VERSION "10.9.1"

NS_ :

BS_:

BU_: ACM ADAS_Body APM ASU_Gateway BCM BCM_BPM CCU_F CCU_R DUMMY_BCM_BPM DUMMY_ECU ETG LDM_L LDM_R OCS_P PSM_D SHVU_F SHVU_R TRM XGW_Body

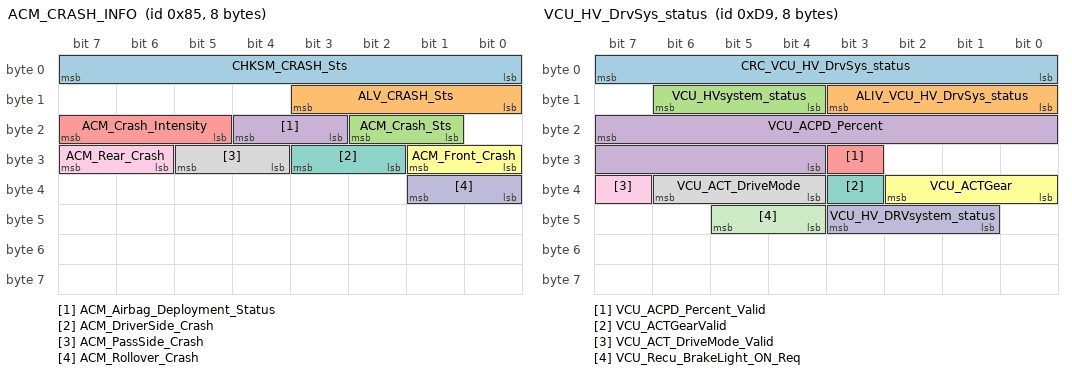
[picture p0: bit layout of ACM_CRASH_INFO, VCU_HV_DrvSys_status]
BO_ 133 ACM_CRASH_INFO: 8 ACM
 SG_ CHKSM_CRASH_Sts : 7|8@0+ (1,0) [0|255] ""  BCM,ETG,XGW_Body
 SG_ ALV_CRASH_Sts : 11|4@0+ (1,0) [0|14] ""  BCM,ETG,XGW_Body
 SG_ ACM_Crash_Sts : 18|2@0+ (1,0) [0|3] ""  BCM,CCU_F,ETG,XGW_Body
 SG_ ACM_Airbag_Deployment_Status : 20|2@0+ (1,0) [0|3] "-"  ETG,XGW_Body
 SG_ ACM_Crash_Intensity : 23|3@0+ (1,0) [0|7] ""  CCU_F,ETG,XGW_Body
 SG_ ACM_Front_Crash : 25|2@0+ (1,0) [0|3] "-"  BCM,ETG,XGW_Body
 SG_ ACM_DriverSide_Crash : 27|2@0+ (1,0) [0|3] ""  BCM,ETG,XGW_Body
 SG_ ACM_PassSide_Crash : 29|2@0+ (1,0) [0|3] "-"  BCM,ETG,XGW_Body
 SG_ ACM_Rear_Crash : 31|2@0+ (1,0) [0|3] "-"  BCM,ETG,XGW_Body
 SG_ ACM_Rollover_Crash : 33|2@0+ (1,0) [0|3] "-"  BCM,ETG,XGW_Body

BO_ 134 ACM_CRASH_DELTA_V_INFO: 8 ACM
 SG_ ACM_CrashDeltaV_PackID : 7|8@0+ (1,0) [1|9] ""  XGW_Body
 SG_ ACM_DeltaVx_01 : 15|9@0+ (1,-250) [-250|250] "Km/h"  XGW_Body
 SG_ ACM_DeltaVx_02 : 22|9@0+ (1,-250) [-250|250] "Km/h"  XGW_Body
 SG_ ACM_DeltaVx_03 : 29|9@0+ (1,-250) [-250|250] "Km/h"  XGW_Body
 SG_ ACM_DeltaVy_01 : 36|9@0+ (1,-250) [-250|250] "Km/h"  XGW_Body
 SG_ ACM_DeltaVy_02 : 43|9@0+ (1,-250) [-250|250] "Km/h"  XGW_Body
 SG_ ACM_DeltaVy_03 : 50|9@0+ (1,-250) [-250|250] "Km/h"  XGW_Body

BO_ 149 IDB_FUNCTION: 8 XGW_Body
 SG_ CHKSM_IDB_FUNCTION : 7|8@0+ (1,0) [0|255] ""  ACM,BCM,DUMMY_ECU
 SG_ ALV_IDB_FUNCTION : 11|4@0+ (1,0) [0|14] ""  ACM,BCM,DUMMY_ECU
 SG_ STAT_ABS : 13|2@0+ (1,0) [0|3] ""  DUMMY_ECU
 SG_ ABS_Active : 15|2@0+ (1,0) [0|3] ""  DUMMY_ECU
 SG_ AYC_Active : 17|2@0+ (1,0) [0|3] "Bit"  DUMMY_ECU
 SG_ ASR_Active : 19|2@0+ (1,0) [0|3] "-"  DUMMY_ECU
 SG_ STAT_DSC : 21|2@0+ (1,0) [0|3] "-"  ACM
 SG_ DSC_Active : 23|2@0+ (1,0) [0|3] ""  DUMMY_ECU
 SG_ HBA_ActiveSignal : 25|2@0+ (1,0) [0|3] ""  DUMMY_ECU
 SG_ ARM_ActiveSignal : 27|2@0+ (1,0) [0|3] "-"  DUMMY_ECU
 SG_ STAT_AutoHazardBlinking : 29|2@0+ (1,0) [0|3] "Bit"  BCM
 SG_ MSR_Active : 31|2@0+ (1,0) [0|3] "-"  DUMMY_ECU
 SG_ HSA_ActiveSignal : 33|2@0+ (1,0) [0|3] ""  DUMMY_ECU
 SG_ EPBi_ECD_ActiveSignal : 35|2@0+ (1,0) [0|3] ""  DUMMY_ECU
 SG_ TSM_Active : 37|2@0+ (1,0) [0|3] "-"  DUMMY_ECU
 SG_ HAS_Available : 41|2@0+ (1,0) [0|3] ""  DUMMY_ECU
 SG_ STAT_EBD : 43|2@0+ (1,0) [0|3] ""  DUMMY_ECU
 SG_ EBD_Active : 45|2@0+ (1,0) [0|3] ""  DUMMY_ECU
 SG_ ST_BRG_MSA : 55|4@0+ (1,0) [0|15] ""  DUMMY_ECU

BO_ 217 VCU_HV_DrvSys_status: 8 XGW_Body
 SG_ CRC_VCU_HV_DrvSys_status : 7|8@0+ (1,0) [0|255] ""  ACM,BCM,LDM_L,LDM_R
 SG_ ALIV_VCU_HV_DrvSys_status : 11|4@0+ (1,0) [0|14] ""  ACM,BCM,LDM_L,LDM_R
 SG_ VCU_HVsystem_status : 14|3@0+ (1,0) [0|7] "-"  ACM,BCM
 SG_ VCU_ACPD_Percent : 23|12@0+ (0.0625,0) [0|100] "%"  ACM
 SG_ VCU_ACPD_Percent_Valid : 27|1@0+ (1,0) [0|1] ""  ACM
 SG_ VCU_ACTGear : 34|3@0+ (1,0) [0|7] ""  BCM,LDM_L,LDM_R
 SG_ VCU_ACTGearValid : 35|1@0+ (1,0) [0|1] ""  BCM,LDM_L,LDM_R
 SG_ VCU_ACT_DriveMode : 38|3@0+ (1,0) [0|7] ""  BCM
 SG_ VCU_ACT_DriveMode_Valid : 39|1@0+ (1,0) [0|1] "-"  BCM
 SG_ VCU_HV_DRVsystem_status : 43|3@0+ (1,0) [0|7] ""  BCM
 SG_ VCU_Recu_BrakeLight_ON_Req : 45|2@0+ (1,0) [0|3] "-"  BCM

BO_ 256 MHU_Vehicle_Info: 8 XGW_Body
 SG_ CHKSM_MHU_VEH_INFO : 7|8@0+ (1,0) [0|255] ""  BCM
 SG_ ALV_MHU_VEH_INFO : 11|4@0+ (1,0) [0|14] ""  BCM
 SG_ MHU_UserProfileId : 23|4@0+ (1,0) [0|15] "-"  BCM
 SG_ MHU_Connectivity_Status : 47|3@0+ (1,0) [0|7] ""  BCM

BO_ 258 BCM_LOGICAL_CLAMP: 3 BCM
 SG_ CHKSM_BCM_LOGICAL_CLAMP : 7|8@0+ (1,0) [0|255] ""  ASU_Gateway,XGW_Body
 SG_ ALIVE_BCM_LOGICAL_CLAMP : 11|4@0+ (1,0) [0|14] ""  ASU_Gateway,XGW_Body
 SG_ STAT_CL30s_Light_L : 13|2@0+ (1,0) [0|3] ""  XGW_Body
 SG_ STAT_CL30s_L : 15|2@0+ (1,0) [0|3] "Bit"  ASU_Gateway,XGW_Body
 SG_ STAT_CL15Wup_L : 17|2@0+ (1,0) [0|3] "Bit"  ASU_Gateway,XGW_Body
 SG_ STAT_CrankRelayHW_BCM : 19|2@0+ (1,0) [0|3] "Bit"  XGW_Body

BO_ 259 BCM_ENERGY_MANAGEMENT: 8 BCM
 SG_ REQ_ConsumerControlSeatMassage : 13|2@0+ (1,0) [0|3] "" XGW_Body
 SG_ REQ_ConsumerControlWirelessCharg : 15|2@0+ (1,0) [0|3] "-"  XGW_Body
 SG_ REQ_ConsumerControlAudioVolumeCo : 18|3@0+ (1,0) [0|7] "-"  XGW_Body
 SG_ REQ_CCU_PTC_Limitation : 21|3@0+ (1,0) [0|7] ""  CCU_F,CCU_R
 SG_ REQ_ConsumerControlRearDefrost : 23|2@0+ (1,0) [0|3] "-"  CCU_F,CCU_R,XGW_Body
 SG_ REQ_ConsumerControlSeatHeatingRe : 31|8@0+ (1,0) [0|100] "%"  SHVU_F,SHVU_R,XGW_Body
 SG_ REQ_ConsumerControlSeatVentilati : 39|8@0+ (1,0) [0|100] "%"  SHVU_F,SHVU_R,XGW_Body
 SG_ REQ_ConsumerControlSeatHeatingFr : 47|8@0+ (1,0) [0|100] "%"  SHVU_F,SHVU_R,XGW_Body
 SG_ DriverIdealTimerCount : 55|8@0+ (5,0) [0|1275] "s"  XGW_Body
 SG_ REQ_ConsumerControlVentilationCl : 63|8@0+ (1,0) [0|100] "%"  CCU_F,CCU_R,SHVU_F,SHVU_R,XGW_Body

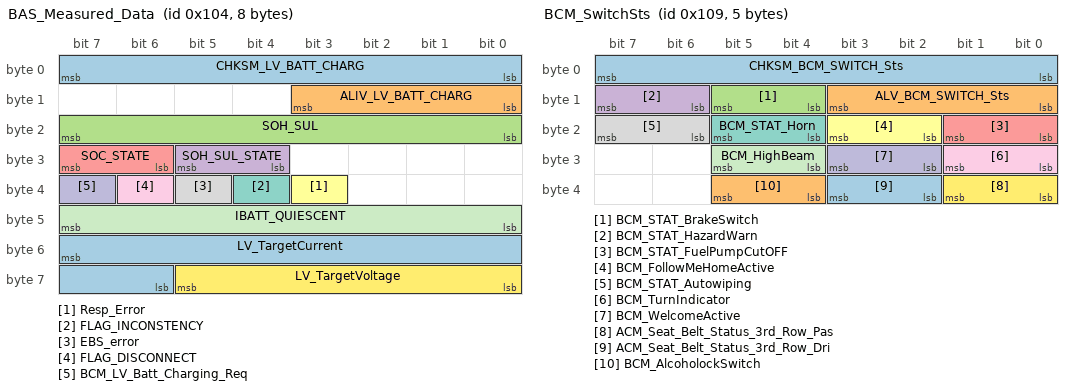
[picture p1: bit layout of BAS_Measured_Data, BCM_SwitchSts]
BO_ 260 BAS_Measured_Data: 8 BCM
 SG_ CHKSM_LV_BATT_CHARG : 7|8@0+ (1,0) [0|255] ""  XGW_Body
 SG_ ALIV_LV_BATT_CHARG : 11|4@0+ (1,0) [0|14] ""  XGW_Body
 SG_ SOH_SUL : 23|8@0+ (1,0) [0|100] "%"  XGW_Body
 SG_ SOH_SUL_STATE : 29|2@0+ (1,0) [0|3] ""  XGW_Body
 SG_ SOC_STATE : 31|2@0+ (1,0) [0|3] "%"  XGW_Body
 SG_ Resp_Error : 35|1@0+ (1,0) [0|1] ""  XGW_Body
 SG_ FLAG_INCONSTENCY : 36|1@0+ (1,0) [0|1] "%"  XGW_Body
 SG_ EBS_error : 37|1@0+ (1,0) [0|1] ""  XGW_Body
 SG_ FLAG_DISCONNECT : 38|1@0+ (1,0) [0|1] ""  XGW_Body
 SG_ BCM_LV_Batt_Charging_Req : 39|1@0+ (1,0) [0|1] ""  XGW_Body
 SG_ IBATT_QUIESCENT : 47|8@0+ (0.00390625,0) [0|0.984375] ""  DUMMY_ECU
 SG_ LV_TargetVoltage : 61|6@0+ (0.112903,9) [9|16] "V" XGW_Body
 SG_ LV_TargetCurrent : 55|10@0+ (0.25,-128) [-128|127] "A" XGW_Body

BO_ 261 BCM_STAT_DOOR_FLAP: 4 BCM
 SG_ CHKSM_BCM_STAT_DOOR_FLAP : 7|8@0+ (1,0) [0|255] ""  ADAS_Body,APM,ASU_Gateway,CCU_F,CCU_R,XGW_Body
 SG_ ALIVE_BCM_STAT_DOOR_FLAP : 11|4@0+ (1,0) [0|14] ""  ADAS_Body,APM,ASU_Gateway,CCU_F,CCU_R,XGW_Body
 SG_ BCM_STAT_TrunkAjar : 17|2@0+ (1,0) [0|3] "Bit"  ADAS_Body,APM,ASU_Gateway,CCU_R,XGW_Body
 SG_ BCM_STAT_DoorAjarFL : 19|2@0+ (1,0) [0|3] "Bit"  ADAS_Body,APM,ASU_Gateway,CCU_F,CCU_R,XGW_Body
 SG_ BCM_STAT_DoorAjarFR : 21|2@0+ (1,0) [0|3] "Bit"  ADAS_Body,APM,ASU_Gateway,CCU_F,CCU_R,XGW_Body
 SG_ BCM_STAT_DoorAjarRL : 23|2@0+ (1,0) [0|3] "Bit"  ADAS_Body,APM,ASU_Gateway,CCU_F,CCU_R,XGW_Body
 SG_ BCM_STAT_DoorAjarRR : 25|2@0+ (1,0) [0|3] "Bit"  ADAS_Body,APM,ASU_Gateway,CCU_F,CCU_R,XGW_Body
 SG_ BCM_STAT_BonnetAjar : 27|2@0+ (1,0) [0|3] "Bit"  ADAS_Body,APM,XGW_Body

BO_ 262 BCM_LIGHT: 8 BCM
 SG_ CHKSM_BCM_LIGHT : 7|8@0+ (1,0) [0|255] ""  ADAS_Body,APM,CCU_F,LDM_L,LDM_R,XGW_Body
 SG_ ALIVE_BCM_LIGHT : 11|4@0+ (1,0) [0|14] ""  ADAS_Body,APM,CCU_F,LDM_L,LDM_R,XGW_Body
 SG_ BCM_DayRunningLampSts : 13|2@0+ (1,0) [0|3] ""  ADAS_Body,LDM_L,LDM_R,XGW_Body
 SG_ BCM_ReverseLightSts : 15|2@0+ (1,0) [0|3] ""  ADAS_Body,TRM,XGW_Body
 SG_ BCM_StopLightSts : 17|2@0+ (1,0) [0|3] ""  ADAS_Body,TRM,XGW_Body
 SG_ BCM_LicensePlateLightSts : 19|2@0+ (1,0) [0|3] ""  ADAS_Body,XGW_Body
 SG_ BCM_Fr_Dimming_dome_lampSts : 21|2@0+ (1,0) [0|3] ""  ADAS_Body,XGW_Body
 SG_ BCM_Rr_Dimming_dome_lampSts : 23|2@0+ (1,0) [0|3] ""  ADAS_Body,XGW_Body
 SG_ BCM_STAT_InteriorLight : 25|2@0+ (1,0) [0|3] "Bit"  ADAS_Body,XGW_Body
 SG_ BCM_STAT_LightActivation : 28|3@0+ (1,0) [0|7] "-"  ADAS_Body,LDM_L,LDM_R,TRM,XGW_Body
 SG_ BCM_HighBeamSts : 31|2@0+ (1,0) [0|3] ""  ADAS_Body,LDM_L,LDM_R,TRM,XGW_Body
 SG_ BCM_STAT_SwitchLightBrightness : 39|7@0+ (1,0) [0|100] "%"  ADAS_Body,XGW_Body
 SG_ BCM_LowBeamSts : 41|2@0+ (1,0) [0|3] "-"  ADAS_Body,LDM_L,LDM_R,TRM,XGW_Body
 SG_ BCM_RearFogLmpSts : 43|2@0+ (1,0) [0|3] "-"  ADAS_Body,TRM,XGW_Body
 SG_ BCM_FrntFogLmpSts : 45|2@0+ (1,0) [0|3] ""  ADAS_Body,XGW_Body
 SG_ BCM_PosLmpSts : 47|2@0+ (1,0) [0|3] "-"  ADAS_Body,LDM_L,LDM_R,TRM,XGW_Body
 SG_ BCM_BackGrdCl58Sts : 51|2@0+ (1,0) [0|3] ""  DUMMY_ECU
 SG_ BCM_HornSts : 53|2@0+ (1,0) [0|3] ""  XGW_Body
 SG_ BCM_TurnIndicatorSts : 55|2@0+ (1,0) [0|3] ""  ADAS_Body,LDM_L,LDM_R,TRM,XGW_Body

BO_ 263 BCM_STAT_CENTRAL_LOCK: 3 BCM
 SG_ CHKSM_BCM_CENTRAL_LOCK : 7|8@0+ (1,0) [0|255] ""  ADAS_Body,ASU_Gateway,XGW_Body
 SG_ ALV_BCM_CENTRAL_LOCK : 11|4@0+ (1,0) [0|14] ""  ADAS_Body,ASU_Gateway,XGW_Body
 SG_ STAT_CDL_LED : 15|2@0+ (1,0) [0|3] "-"  XGW_Body
 SG_ STAT_DoorUnlockFL : 17|2@0+ (1,0) [0|3] "Bit"  XGW_Body
 SG_ STAT_ATWS : 20|3@0+ (1,0) [0|7] "Bit"  ADAS_Body,XGW_Body
 SG_ BCM_CentralLockSwSts : 21|1@0+ (1,0) [0|0] ""  DUMMY_ECU
 SG_ STAT_DoorLockFL : 23|2@0+ (1,0) [0|3] "Bit"  ADAS_Body,ASU_Gateway,XGW_Body

BO_ 265 BCM_SwitchSts: 5 BCM
 SG_ CHKSM_BCM_SWITCH_Sts : 7|8@0+ (1,0) [0|255] ""  ACM,ADAS_Body,LDM_L,LDM_R,TRM,XGW_Body
 SG_ ALV_BCM_SWITCH_Sts : 11|4@0+ (1,0) [0|14] ""  ACM,ADAS_Body,LDM_L,LDM_R,TRM,XGW_Body
 SG_ BCM_STAT_BrakeSwitch : 13|2@0+ (1,0) [0|3] ""  ACM,ADAS_Body,TRM,XGW_Body
 SG_ BCM_STAT_HazardWarn : 15|2@0+ (1,0) [0|3] "-"  ADAS_Body,LDM_L,LDM_R,TRM,XGW_Body
 SG_ BCM_STAT_FuelPumpCutOFF : 17|2@0+ (1,0) [0|3] ""  XGW_Body
 SG_ BCM_FollowMeHomeActive : 19|2@0+ (1,0) [0|3] ""  TRM,XGW_Body
 SG_ BCM_STAT_Horn : 21|2@0+ (1,0) [0|3] "-"  XGW_Body
 SG_ BCM_STAT_Autowiping : 23|2@0+ (1,0) [0|3] ""  XGW_Body
 SG_ BCM_TurnIndicator : 25|2@0+ (1,0) [0|3] ""  ADAS_Body,LDM_L,LDM_R,TRM,XGW_Body
 SG_ BCM_WelcomeActive : 27|2@0+ (1,0) [0|3] "-"  TRM,XGW_Body
 SG_ BCM_HighBeam : 29|2@0+ (1,0) [0|3] ""  LDM_L,LDM_R,TRM,XGW_Body
 SG_ ACM_Seat_Belt_Status_3rd_Row_Pas : 33|2@0+ (1,0) [0|3] ""  XGW_Body
 SG_ ACM_Seat_Belt_Status_3rd_Row_Dri : 35|2@0+ (1,0) [0|3] "-"  XGW_Body
 SG_ BCM_AlcoholockSwitch : 37|2@0+ (1,0) [0|3] ""  DUMMY_ECU

BO_ 266 BCM_VOLTAGE: 8 BCM
 SG_ CHKSM_BCM_VOLTAGE : 7|8@0+ (1,0) [0|255] ""  ACM,ADAS_Body,APM,ASU_Gateway,BCM_BPM,CCU_F,CCU_R,ETG,LDM_L,LDM_R,OCS_P,PSM_D,SHVU_F,SHVU_R,TRM,XGW_Body
 SG_ ALIVE_BCM_VOLTAGE : 11|4@0+ (1,0) [0|14] ""  ACM,ADAS_Body,APM,ASU_Gateway,BCM_BPM,CCU_F,CCU_R,ETG,LDM_L,LDM_R,OCS_P,PSM_D,SHVU_F,SHVU_R,TRM,XGW_Body
 SG_ LV_BatteryType : 13|2@0+ (1,0) [0|3] "Number" XGW_Body
 SG_ UBatt : 23|14@0+ (0.0009777,3) [3|18] "V"  ACM,ADAS_Body,APM,ASU_Gateway,BCM_BPM,CCU_F,CCU_R,ETG,LDM_L,LDM_R,OCS_P,PSM_D,SHVU_F,SHVU_R,TRM,XGW_Body
 SG_ LV_Batt_Temp : 39|8@0+ (1,-40) [-40|105] "Degree C"  ACM,ADAS_Body,APM,ASU_Gateway,BCM_BPM,CCU_F,CCU_R,ETG,LDM_L,LDM_R,OCS_P,PSM_D,SHVU_F,SHVU_R,TRM,XGW_Body
 SG_ LV_SOC : 47|8@0+ (1,0) [0|100] "%"  ACM,ADAS_Body,APM,ASU_Gateway,BCM_BPM,CCU_F,CCU_R,ETG,LDM_L,LDM_R,OCS_P,PSM_D,SHVU_F,SHVU_R,TRM,XGW_Body
 SG_ LV_Batt_Current : 55|16@0+ (0.03125,-1536) [-1536|511.90625] "A"  ACM,ADAS_Body,APM,ASU_Gateway,BCM_BPM,CCU_F,CCU_R,ETG,LDM_L,LDM_R,OCS_P,PSM_D,SHVU_F,SHVU_R,TRM,XGW_Body

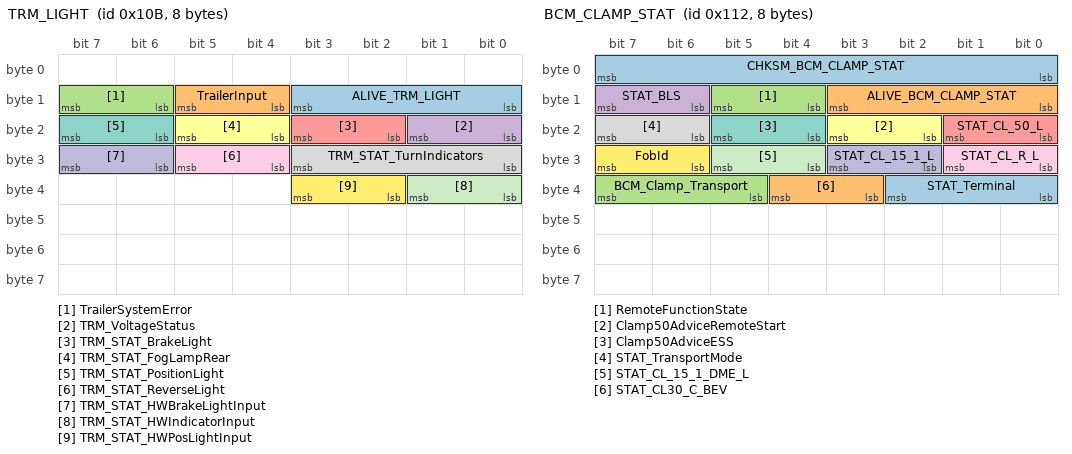
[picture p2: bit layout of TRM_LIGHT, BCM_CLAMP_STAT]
BO_ 267 TRM_LIGHT: 8 TRM
 SG_ ALIVE_TRM_LIGHT : 11|4@0+ (1,0) [0|14] ""  BCM,XGW_Body
 SG_ TrailerInput : 13|2@0+ (1,0) [0|3] ""  BCM,XGW_Body
 SG_ TrailerSystemError : 15|2@0+ (1,0) [0|3] ""  BCM,XGW_Body
 SG_ TRM_VoltageStatus : 17|2@0+ (1,0) [0|3] ""  BCM,XGW_Body
 SG_ TRM_STAT_BrakeLight : 19|2@0+ (1,0) [0|3] ""  BCM,XGW_Body
 SG_ TRM_STAT_FogLampRear : 21|2@0+ (1,0) [0|3] ""  BCM,XGW_Body
 SG_ TRM_STAT_PositionLight : 23|2@0+ (1,0) [0|3] ""  BCM,XGW_Body
 SG_ TRM_STAT_TurnIndicators : 27|4@0+ (1,0) [0|15] ""  BCM,XGW_Body
 SG_ TRM_STAT_ReverseLight : 29|2@0+ (1,0) [0|3] ""  BCM,XGW_Body
 SG_ TRM_STAT_HWBrakeLightInput : 31|2@0+ (1,0) [0|3] ""  BCM,XGW_Body
 SG_ TRM_STAT_HWIndicatorInput : 33|2@0+ (1,0) [0|3] ""  BCM,XGW_Body
 SG_ TRM_STAT_HWPosLightInput : 35|2@0+ (1,0) [0|3] ""  BCM,XGW_Body

BO_ 268 BCM_RemoteCtrlSts: 8 BCM
 SG_ Checksum_0x10C : 7|8@0+ (1,0) [0|255] ""  XGW_Body
 SG_ Rolling_Counter_0x10C : 11|4@0+ (1,0) [0|14] ""  XGW_Body
 SG_ BCM_TboxAuthStatus : 23|2@0+ (1,0) [0|3] "-"  XGW_Body
 SG_ BCM_RandomNum32bit : 31|32@0+ (1,0) [0|4294967295] "-"  XGW_Body

BO_ 269 MHU_BCM_DoorsCtrl: 8 XGW_Body
 SG_ MHU_APM_ReqWindow : 3|2@0+ (1,0) [0|3] "-"  BCM
 SG_ MHU_BCM_RemoteDoorCtrl : 5|2@0+ (1,0) [0|3] "-"  BCM
 SG_ MHU_BCM_reqTrunk : 7|2@0+ (1,0) [0|3] "-"  BCM
 SG_ MHU_BCM_reqFrunk : 9|2@0+ (1,0) [0|3] "-"  BCM
 SG_ MHU_BCM_ReqSunroof : 23|8@0+ (1,0) [0|255] "%"  BCM
 SG_ TBOX_AuthCode_0x10D : 55|16@0+ (1,0) [0|65535] "-"  BCM

BO_ 270 BCM_ENTRY_CONTROL: 3 BCM
 SG_ GlobalWindowReq : 3|3@0+ (1,0) [0|7] ""  APM
 SG_ RemoteAccessKey : 7|4@0+ (1,0) [0|15] "-"  APM,ETG,XGW_Body
 SG_ PassiveAccessTrunk : 9|2@0+ (1,0) [0|3] "-"  ETG,XGW_Body
 SG_ ComfortOpen : 11|2@0+ (1,0) [0|3] "-"  ETG,XGW_Body
 SG_ PassiveAccessDoor : 13|2@0+ (1,0) [0|3] "-"  APM,ETG,XGW_Body
 SG_ FksOpen : 15|2@0+ (1,0) [0|3] ""  ETG,XGW_Body

BO_ 271 MHU_BCM_HornLightControl: 8 XGW_Body
 SG_ MHU_SetHornOnOff : 3|2@0+ (1,0) [0|3] "-"  BCM
 SG_ MHU_SetLowBeam : 5|2@0+ (1,0) [0|3] ""  BCM
 SG_ MHU_SetHighBeam : 7|2@0+ (1,0) [0|3] ""  BCM
 SG_ TBOX_AuthCode_0x10F : 55|16@0+ (1,0) [0|65535] "-"  BCM

BO_ 273 BCM_Stat_SwitchLightBrightness: 8 BCM
 SG_ BCM_Stat_SwitchLightBrightness : 7|8@0+ (0.4,0) [0|102] ""  XGW_Body
 SG_ BCM_Rear_Wiper_Park_Pos_Status : 32|1@0+ (1,0) [0|1] ""  DUMMY_ECU
 SG_ BCM_Front_Wiper_Park_Pos_Status : 33|1@0+ (1,0) [0|1] ""  DUMMY_ECU
 SG_ BCM_Rear_Wash_Status : 34|1@0+ (1,0) [0|1] ""  DUMMY_ECU
 SG_ BCM_Front_Wash_Status : 35|1@0+ (1,0) [0|1] ""  DUMMY_ECU

BO_ 274 BCM_CLAMP_STAT: 8 BCM
 SG_ CHKSM_BCM_CLAMP_STAT : 7|8@0+ (1,0) [0|255] ""  ACM,ADAS_Body,APM,ASU_Gateway,BCM_BPM,CCU_F,CCU_R,ETG,LDM_L,LDM_R,OCS_P,PSM_D,SHVU_F,SHVU_R,TRM,XGW_Body
 SG_ ALIVE_BCM_CLAMP_STAT : 11|4@0+ (1,0) [0|14] ""  ACM,ADAS_Body,APM,ASU_Gateway,BCM_BPM,CCU_F,CCU_R,ETG,LDM_L,LDM_R,OCS_P,PSM_D,SHVU_F,SHVU_R,TRM,XGW_Body
 SG_ RemoteFunctionState : 13|2@0+ (1,0) [0|3] ""  ACM,ADAS_Body,APM,ASU_Gateway,BCM_BPM,CCU_F,CCU_R,ETG,LDM_L,LDM_R,OCS_P,PSM_D,SHVU_F,SHVU_R,TRM,XGW_Body
 SG_ STAT_BLS : 15|2@0+ (1,0) [0|3] "-"  ACM,ADAS_Body,APM,ASU_Gateway,BCM_BPM,CCU_F,CCU_R,ETG,LDM_L,LDM_R,OCS_P,PSM_D,SHVU_F,SHVU_R,TRM,XGW_Body
 SG_ STAT_CL_50_L : 17|2@0+ (1,0) [0|3] ""  ACM,ADAS_Body,APM,ASU_Gateway,BCM_BPM,CCU_F,CCU_R,ETG,LDM_L,LDM_R,OCS_P,PSM_D,SHVU_F,SHVU_R,TRM,XGW_Body
 SG_ Clamp50AdviceRemoteStart : 19|2@0+ (1,0) [0|3] "-"  ACM,ADAS_Body,APM,ASU_Gateway,BCM_BPM,CCU_F,CCU_R,ETG,LDM_L,LDM_R,OCS_P,PSM_D,SHVU_F,SHVU_R,TRM,XGW_Body
 SG_ Clamp50AdviceESS : 21|2@0+ (1,0) [0|3] "-"  ACM,ADAS_Body,APM,ASU_Gateway,BCM_BPM,CCU_F,CCU_R,ETG,LDM_L,LDM_R,OCS_P,PSM_D,SHVU_F,SHVU_R,TRM,XGW_Body
 SG_ STAT_TransportMode : 23|2@0+ (1,0) [0|3] "" XGW_Body
 SG_ STAT_CL_R_L : 25|2@0+ (1,0) [0|3] ""  ACM,ADAS_Body,APM,ASU_Gateway,BCM_BPM,CCU_F,CCU_R,ETG,LDM_L,LDM_R,OCS_P,PSM_D,SHVU_F,SHVU_R,TRM,XGW_Body
 SG_ STAT_CL_15_1_L : 27|2@0+ (1,0) [0|3] "-"  ACM,ADAS_Body,APM,ASU_Gateway,BCM_BPM,CCU_F,CCU_R,ETG,LDM_L,LDM_R,OCS_P,PSM_D,SHVU_F,SHVU_R,TRM,XGW_Body
 SG_ STAT_CL_15_1_DME_L : 29|2@0+ (1,0) [0|3] ""  ACM,ADAS_Body,APM,ASU_Gateway,BCM_BPM,CCU_F,CCU_R,ETG,LDM_L,LDM_R,OCS_P,PSM_D,SHVU_F,SHVU_R,TRM,XGW_Body
 SG_ FobId : 31|2@0+ (1,0) [0|3] "Bit"  ACM,ADAS_Body,APM,ASU_Gateway,BCM_BPM,CCU_F,CCU_R,ETG,LDM_L,LDM_R,OCS_P,PSM_D,SHVU_F,SHVU_R,TRM,XGW_Body
 SG_ STAT_Terminal : 34|3@0+ (1,0) [0|7] "Bit"  ACM,ADAS_Body,APM,ASU_Gateway,BCM_BPM,CCU_F,CCU_R,ETG,LDM_L,LDM_R,OCS_P,PSM_D,SHVU_F,SHVU_R,TRM,XGW_Body
 SG_ STAT_CL30_C_BEV : 36|2@0+ (1,0) [0|3] "Bit"  ACM,ADAS_Body,APM,ASU_Gateway,BCM_BPM,CCU_F,CCU_R,ETG,LDM_L,LDM_R,OCS_P,PSM_D,SHVU_F,SHVU_R,TRM,XGW_Body
 SG_ BCM_Clamp_Transport : 39|3@0+ (1,0) [0|7] ""  ACM,ADAS_Body,APM,ASU_Gateway,BCM_BPM,CCU_F,CCU_R,ETG,LDM_L,LDM_R,OCS_P,PSM_D,SHVU_F,SHVU_R,TRM,XGW_Body

BO_ 276 BCM_LVBAT_Data: 8 BCM
 SG_ CHKSM_LVBAT_DATA : 7|8@0+ (1,0) [0|255] "" XGW_Body
 SG_ ALIV_LVBAT_DATA : 11|4@0+ (1,0) [0|14] "" XGW_Body
 SG_ LV_ErrorSts : 14|3@0+ (1,0) [0|7] "" XGW_Body
 SG_ LV_MinCellVolt : 23|8@0+ (0.015625,1) [1|5] "V" XGW_Body
 SG_ LV_MaxCellVolt : 31|8@0+ (0.015625,1) [1|5] "V" XGW_Body
 SG_ LV_MinCellTemp : 39|8@0+ (1,-40) [-40|215] "Degree C" XGW_Body
 SG_ LV_MaxCellTemp : 47|8@0+ (1,-40) [-40|215] "Degree C" XGW_Body
 SG_ LV_Discharger_Err : 48|1@0+ (1,0) [0|1] "" XGW_Body
 SG_ LV_Discharger_Sts : 49|1@0+ (1,0) [0|1] "" XGW_Body
 SG_ LV_Charger_Err : 50|1@0+ (1,0) [0|1] "" XGW_Body
 SG_ LV_Charger_Sts : 51|1@0+ (1,0) [0|1] "" XGW_Body
 SG_ LV_OverVoltage : 52|1@0+ (1,0) [0|1] "" XGW_Body
 SG_ LV_UnderVoltage : 53|1@0+ (1,0) [0|1] "" XGW_Body
 SG_ LV_OverCurrent : 54|1@0+ (1,0) [0|1] "" XGW_Body
 SG_ LV_UnderTemp : 55|1@0+ (1,0) [0|1] "" XGW_Body
 SG_ LV_OverTemp : 56|1@0+ (1,0) [0|1] "" XGW_Body
 SG_ LV_OverCharge : 57|1@0+ (1,0) [0|1] "" XGW_Body
 SG_ LV_OverDischarge : 58|1@0+ (1,0) [0|1] "" XGW_Body
 SG_ LV_CellBalance_Sts : 59|1@0+ (1,0) [0|1] "" XGW_Body
 SG_ LV_CellBalance_Error : 60|1@0+ (1,0) [0|1] "" XGW_Body
 SG_ LV_ThermalRunaway : 61|1@0+ (1,0) [0|1] "" XGW_Body
 SG_ LV_WarmupRequest : 63|2@0+ (1,0) [0|3] "" XGW_Body

BO_ 277 BCM_Childlock: 8 BCM
 SG_ BCM_ChildLock_Feedback : 7|2@0+ (1,0) [0|3] ""  XGW_Body

BO_ 278 BCM_LVBAT_COM_INFO2: 8 BCM
 SG_ CHKSM_LVBAT_INFO2 : 7|8@0+ (1,0) [0|255] "" XGW_Body
 SG_ ALIV_LVBAT_INFO2 : 11|4@0+ (1,0) [0|14] "" XGW_Body
 SG_ LV_MaxAllowDischargeCurrent : 16|8@0+ (1,0) [0|253] "A" XGW_Body
 SG_ LV_WakeupReason : 19|3@0+ (1,0) [0|7] "" XGW_Body
 SG_ LV_MaxAllowChargeCurrent : 24|8@0+ (1,0) [0|253] "A" XGW_Body
 SG_ LV_SOE : 32|7@0+ (1,0) [0|100] "%" XGW_Body

BO_ 280 BCM_MHU_Ctrl_Fbk: 8 BCM
 SG_ CHKSM_BCM_MHU_Ctrl_Fbk : 7|8@0+ (1,0) [0|255] "" XGW_Body
 SG_ ALV_BCM_MHU_Ctrl_Fbk : 11|4@0+ (1,0) [0|14] "" XGW_Body
 SG_ BCM_DrvInhibitStsFbk : 13|2@0+ (1,0) [0|3] "" XGW_Body

BO_ 282 MHU_ServiceMode_Setting: 8 XGW_Body
 SG_ MHU_SET_WiperServicePositionMod : 5|2@0+ (1,0) [0|3] ""  BCM
 SG_ MHU_Read_KeyFobOnCenterConsole : 7|2@0+ (1,0) [0|3] ""  BCM

BO_ 283 MHU_BCM_RemoteClampCtrl: 8 XGW_Body
 SG_ TBOX_STAT_TerminalReq : 7|3@0+ (1,0) [0|7] "-"  BCM
 SG_ TBOX_AuthCode_0x11B : 55|16@0+ (1,0) [0|65535] ""  BCM

BO_ 284 MHU_BCM_FOTAClampCtrl: 8 XGW_Body
 SG_ TBOX_FOTA_STAT_TerminalReq : 7|3@0+ (1,0) [0|7] "-"  BCM

BO_ 285 CCU_RearHVACControl: 8 CCU_F
 SG_ CCU_ERL_Rear : 7|8@0+ (1,0) [0|255] ""  CCU_R
 SG_ CCU_EvapTempSet_Rear : 15|8@0+ (0.1,-5) [-5|20.5] "Degree C"  CCU_R
 SG_ CCU_AirDistribFlapPos_Rear : 23|8@0+ (0.5,0) [0|100] "%"  CCU_R
 SG_ CCU_BlowerFltPwm_Rear : 31|8@0+ (0.5,0) [0|100] "%"  CCU_R
 SG_ CCU_DuctTargetTemp_Rear : 39|8@0+ (0.5,-40) [-40|85] "Degree C"  CCU_R
 SG_ CCU_TempFlapPos_Rear : 47|8@0+ (0.5,0) [0|100] "%"  CCU_R
 SG_ CCU_FanSpeed_Rear : 51|4@0+ (1,0) [0|15] "%"  CCU_R
 SG_ CCUF_InteriorTemp_Rear : 63|8@0+ (0.5,-40) [-40|85] "Degree C"  DUMMY_ECU

BO_ 286 CCUR_SensorInfo: 8 CCU_R
 SG_ CCUR_DuctActRearFace : 7|8@0+ (0.5,-40) [-40|85] "Degree C"  CCU_F
 SG_ CCUR_DuctActRearFoot : 15|8@0+ (0.5,-40) [-40|85] "Degree C"  CCU_F
 SG_ CCUR_EvaporatorTemp : 23|8@0+ (0.5,-40) [-40|85] "Degree C"  CCU_F
 SG_ CCUR_InteriorTemp : 31|8@0+ (0.5,-40) [-40|85] "Degree C"  CCU_F
 SG_ CCUR_AirDistribFeedback_Rear : 39|8@0+ (0.5,0) [0|5] "V"  CCU_F
 SG_ CCUR_TempFeedback_Rear : 47|8@0+ (0.5,0) [0|5] "V"  CCU_F
 SG_ CCUR_BlowerFeedback_Rear : 55|8@0+ (0.5,0) [0|5] "V"  CCU_F

BO_ 287 MHU_BCM_Ctrl: 8 XGW_Body
 SG_ MHU_DrvInhibitSts : 13|2@0+ (1,0) [0|3] "" BCM
 SG_ TBOX_AuthCode_0x11F : 55|16@0+ (1,0) [0|65535] "" BCM

BO_ 290 CCU_MaxReq: 4 CCU_F
 SG_ CHKSM_CCU_REQUEST : 7|8@0+ (1,0) [0|255] ""  XGW_Body
 SG_ ALV_CCU_REQUEST : 11|4@0+ (1,0) [0|14] ""  XGW_Body
 SG_ CCU_REQ_MaxCool : 13|2@0+ (1,0) [0|3] ""  XGW_Body
 SG_ CCU_REQ_MaxHeat : 15|2@0+ (1,0) [0|3] ""  XGW_Body
 SG_ CCU_REQ_ESSMotorControl : 18|3@0+ (1,0) [0|7] "Bit"  XGW_Body
 SG_ CCU_AC_PWM : 31|7@0+ (1,0) [0|100] "%"  XGW_Body

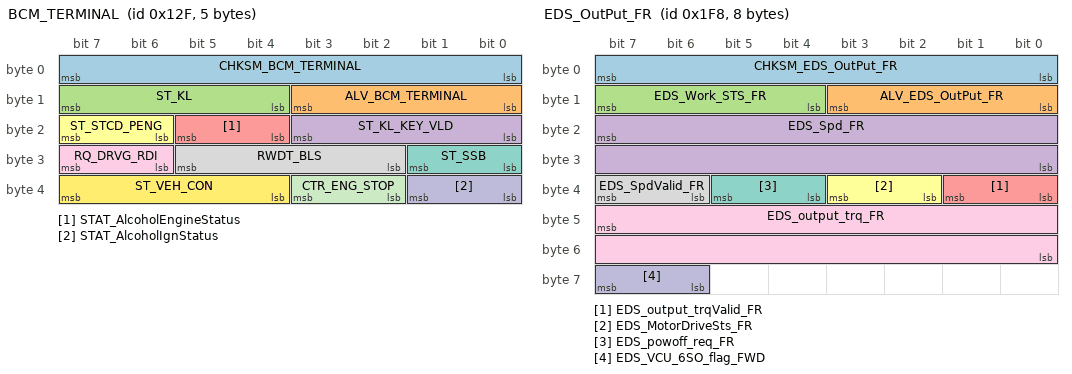
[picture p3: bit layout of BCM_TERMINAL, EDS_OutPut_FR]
BO_ 303 BCM_TERMINAL: 5 BCM
 SG_ CHKSM_BCM_TERMINAL : 7|8@0+ (1,0) [0|255] ""  XGW_Body
 SG_ ALV_BCM_TERMINAL : 11|4@0+ (1,0) [0|14] ""  XGW_Body
 SG_ ST_KL : 15|4@0+ (1,0) [0|15] "-"  XGW_Body
 SG_ ST_KL_KEY_VLD : 19|4@0+ (1,0) [0|15] ""  XGW_Body
 SG_ STAT_AlcoholEngineStatus : 21|2@0+ (1,0) [0|3] ""  XGW_Body
 SG_ ST_STCD_PENG : 23|2@0+ (1,0) [0|3] ""  XGW_Body
 SG_ ST_SSB : 25|2@0+ (1,0) [0|3] "-"  XGW_Body
 SG_ RWDT_BLS : 29|4@0+ (1,0) [0|15] "-"  XGW_Body
 SG_ RQ_DRVG_RDI : 31|2@0+ (1,0) [0|3] ""  XGW_Body
 SG_ STAT_AlcoholIgnStatus : 33|2@0+ (1,0) [0|3] ""  XGW_Body
 SG_ CTR_ENG_STOP : 35|2@0+ (1,0) [0|3] "Bit"  XGW_Body
 SG_ ST_VEH_CON : 39|4@0+ (1,0) [0|15] "-"  XGW_Body

BO_ 359 VCU_TWV1_Frm: 8 XGW_Body
 SG_ TWV1_N_Position : 7|16@0+ (0.1,0) [0|100] "%"  CCU_F
 SG_ TWV1_St_Feedback : 23|16@0+ (1,0) [0|15] ""  CCU_F
 SG_ TWV1_Frm_Error : 39|1@0+ (1,0) [0|1] ""  CCU_F

BO_ 376 YSS_LongAcc: 8 XGW_Body
 SG_ CHKSM_YSS_LongAcc : 7|8@0+ (1,0) [0|255] ""  ASU_Gateway
 SG_ ALV_YSS_LongAcc : 11|4@0+ (1,0) [0|14] ""  ASU_Gateway
 SG_ YSS_LONG_ACCUNFILTERED_QUAL : 15|4@0+ (1,0) [0|15] ""  ASU_Gateway
 SG_ YSS_LONG_ACC_UNFILTERED : 23|16@0+ (0.002,-65.532) [-65.532|65.532] "m/s2"  ASU_Gateway
 SG_ YSS_LONG_ACC_QUAL : 35|4@0+ (1,0) [0|15] ""  ASU_Gateway
 SG_ YSS_LONG_ACC : 47|16@0+ (0.002,-65.532) [-65.532|65.532] "m/s2"  ASU_Gateway

BO_ 381 YSS_YawRate: 8 XGW_Body
 SG_ CHKSM_YSS_YawRate : 7|8@0+ (1,0) [0|255] ""  ASU_Gateway
 SG_ ALV_YSS_YawRate : 11|4@0+ (1,0) [0|14] ""  ASU_Gateway
 SG_ YSS_YAW_RATEUNFILTERED_QUAL : 15|4@0+ (1,0) [0|15] ""  ASU_Gateway
 SG_ YSS_YAW_RATE_UNFILTERED : 23|16@0+ (0.005,-163.83) [-163.83|163.83] "°/s"  ASU_Gateway
 SG_ YSS_YAW_RATE_QUAL : 35|4@0+ (1,0) [0|15] ""  ASU_Gateway
 SG_ YSS_SC_STATUS : 39|4@0+ (1,0) [0|15] ""  ASU_Gateway
 SG_ YSS_YAW_RATE : 47|16@0+ (0.005,-163.83) [-163.83|163.83] "°/s"  ASU_Gateway
 SG_ YSS_TEMPERATURE : 63|8@0+ (1,-40) [-40|115] "°C"  ASU_Gateway

BO_ 382 SAS_Sensor: 7 XGW_Body
 SG_ CHKSM_SAS_Sensor : 7|8@0+ (1,0) [0|255] ""  ACM,BCM,LDM_L,LDM_R
 SG_ ALV_SAS_Sensor : 11|4@0+ (1,0) [0|14] ""  ACM,BCM,LDM_L,LDM_R
 SG_ SAS_SASStsSnsr : 13|2@0+ (1,0) [0|1] "-"  ACM,LDM_L,LDM_R
 SG_ SAS_SteerWhlRotSpd : 21|14@0+ (0.125,-1024) [-1024|1023.875] "degree/s"  LDM_L,LDM_R
 SG_ SAS_SteerWhlRotSpdStatus : 23|2@0+ (1,0) [0|1] ""  LDM_L,LDM_R
 SG_ SAS_SASFailure : 33|2@0+ (1,0) [0|1] ""  ACM,LDM_L,LDM_R
 SG_ SAS_Calibrated : 35|2@0+ (1,0) [0|1] ""  ACM,LDM_L,LDM_R
 SG_ SAS_SteerWheelAngleValid : 39|2@0+ (1,0) [0|1] ""  ACM,LDM_L,LDM_R
 SG_ SAS_SteerWheelAngle : 47|16@0+ (0.0238,-780) [-780|779.7] "deg"  ACM,BCM,LDM_L,LDM_R

BO_ 385 CAM_MSG1: 8 ADAS_Body
 SG_ CAM_CamSts : 1|2@0+ (1,0) [0|3] ""  LDM_L,LDM_R
 SG_ CAM_AmbLi : 8|1@0+ (1,0) [0|1] ""  LDM_L,LDM_R
 SG_ CAM_RoadIllmn : 12|1@0+ (1,0) [0|1] ""  LDM_L,LDM_R
 SG_ CAM_Obj_TrfcStyle : 21|2@0+ (1,0) [0|3] ""  LDM_L,LDM_R

BO_ 401 CAM_MSG2: 8 ADAS_Body
 SG_ CAM_Obj1_ID : 7|8@0+ (1,0) [0|255] ""  LDM_L,LDM_R
 SG_ CAM_Obj1_HozlDst : 14|9@0+ (1,0) [0|511] "m"  LDM_L,LDM_R
 SG_ CAM_Obj1_Valid : 15|1@0+ (1,0) [0|1] ""  LDM_L,LDM_R
 SG_ CAM_Obj1_HozlPosnRi : 19|10@0+ (0.08,-40) [-40|40] "degree"  LDM_L,LDM_R
 SG_ CAM_Obj1_Typ : 21|2@0+ (1,0) [0|3] ""  LDM_L,LDM_R
 SG_ CAM_Obj1_HozlPosnLe : 25|10@0+ (0.08,-40) [-40|40] "degree"  LDM_L,LDM_R
 SG_ CAM_Obj1_VertPosn : 47|8@0+ (0.1,-12) [-12|12] "degree"  LDM_L,LDM_R
 SG_ CAM_Obj1_HozlSpdLe : 55|8@0+ (0.5,-64) [-64|63.5] "degree/s"  LDM_L,LDM_R
 SG_ CAM_Obj1_HozlSpdRi : 63|8@0+ (0.5,-64) [-64|63.5] "degree/s"  LDM_L,LDM_R

BO_ 404 CAM_MSG3: 8 ADAS_Body
 SG_ CAM_Obj2_ID : 7|8@0+ (1,0) [0|255] ""  LDM_L,LDM_R
 SG_ CAM_Obj2_HozlDst : 14|9@0+ (1,0) [0|511] "m"  LDM_L,LDM_R
 SG_ CAM_Obj2_Valid : 15|1@0+ (1,0) [0|1] ""  LDM_L,LDM_R
 SG_ CAM_Obj2_HozlPosnRi : 19|10@0+ (0.08,-40) [-40|40] "degree"  LDM_L,LDM_R
 SG_ CAM_Obj2_Typ : 21|2@0+ (1,0) [0|3] ""  LDM_L,LDM_R
 SG_ CAM_Obj2_HozlPosnLe : 25|10@0+ (0.08,-40) [-40|40] "degree"  LDM_L,LDM_R
 SG_ CAM_Obj2_VertPosn : 47|8@0+ (0.1,-12) [-12|12] "degree"  LDM_L,LDM_R
 SG_ CAM_Obj2_HozlSpdLe : 55|8@0+ (0.5,-64) [-64|63.5] "degree/s"  LDM_L,LDM_R
 SG_ CAM_Obj2_HozlSpdRi : 63|8@0+ (0.5,-64) [-64|63.5] "degree/s"  LDM_L,LDM_R

BO_ 406 CAM_MSG4: 8 ADAS_Body
 SG_ CAM_Obj3_ID : 7|8@0+ (1,0) [0|255] ""  LDM_L,LDM_R
 SG_ CAM_Obj3_HozlDst : 14|9@0+ (1,0) [0|511] "m"  LDM_L,LDM_R
 SG_ CAM_Obj3_Valid : 15|1@0+ (1,0) [0|1] ""  LDM_L,LDM_R
 SG_ CAM_Obj3_HozlPosnRi : 19|10@0+ (0.08,-40) [-40|40] "degree"  LDM_L,LDM_R
 SG_ CAM_Obj3_Typ : 21|2@0+ (1,0) [0|3] ""  LDM_L,LDM_R
 SG_ CAM_Obj3_HozlPosnLe : 25|10@0+ (0.08,-40) [-40|40] "degree"  LDM_L,LDM_R
 SG_ CAM_Obj3_VertPosn : 47|8@0+ (0.1,-12) [-12|12] "degree"  LDM_L,LDM_R
 SG_ CAM_Obj3_HozlSpdLe : 55|8@0+ (0.5,-64) [-64|63.5] "degree/s"  LDM_L,LDM_R
 SG_ CAM_Obj3_HozlSpdRi : 63|8@0+ (0.5,-64) [-64|63.5] "degree/s"  LDM_L,LDM_R

BO_ 410 CAM_MSG5: 8 ADAS_Body
 SG_ CAM_Obj4_ID : 7|8@0+ (1,0) [0|255] ""  LDM_L,LDM_R
 SG_ CAM_Obj4_HozlDst : 14|9@0+ (1,0) [0|511] "m"  LDM_L,LDM_R
 SG_ CAM_Obj4_Valid : 15|1@0+ (1,0) [0|1] ""  LDM_L,LDM_R
 SG_ CAM_Obj4_HozlPosnRi : 19|10@0+ (0.08,-40) [-40|40] "degree"  LDM_L,LDM_R
 SG_ CAM_Obj4_Typ : 21|2@0+ (1,0) [0|3] ""  LDM_L,LDM_R
 SG_ CAM_Obj4_HozlPosnLe : 25|10@0+ (0.08,-40) [-40|40] "degree"  LDM_L,LDM_R
 SG_ CAM_Obj4_VertPosn : 47|8@0+ (0.1,-12) [-12|12] "degree"  LDM_L,LDM_R
 SG_ CAM_Obj4_HozlSpdLe : 55|8@0+ (0.5,-64) [-64|63.5] "degree/s"  LDM_L,LDM_R
 SG_ CAM_Obj4_HozlSpdRi : 63|8@0+ (0.5,-64) [-64|63.5] "degree/s"  LDM_L,LDM_R

BO_ 412 CAM_MSG6: 8 ADAS_Body
 SG_ CAM_Obj5_ID : 7|8@0+ (1,0) [0|255] ""  LDM_L,LDM_R
 SG_ CAM_Obj5_HozlDst : 14|9@0+ (1,0) [0|511] "m"  LDM_L,LDM_R
 SG_ CAM_Obj5_Valid : 15|1@0+ (1,0) [0|1] ""  LDM_L,LDM_R
 SG_ CAM_Obj5_HozlPosnRi : 19|10@0+ (0.08,-40) [-40|40] "degree"  LDM_L,LDM_R
 SG_ CAM_Obj5_Typ : 21|2@0+ (1,0) [0|3] ""  LDM_L,LDM_R
 SG_ CAM_Obj5_HozlPosnLe : 25|10@0+ (0.08,-40) [-40|40] "degree"  LDM_L,LDM_R
 SG_ CAM_Obj5_VertPosn : 47|8@0+ (0.1,-12) [-12|12] "degree"  LDM_L,LDM_R
 SG_ CAM_Obj5_HozlSpdLe : 55|8@0+ (0.5,-64) [-64|63.5] "degree/s"  LDM_L,LDM_R
 SG_ CAM_Obj5_HozlSpdRi : 63|8@0+ (0.5,-64) [-64|63.5] "degree/s"  LDM_L,LDM_R

BO_ 413 CAM_MSG7: 8 ADAS_Body
 SG_ CAM_Obj6_ID : 7|8@0+ (1,0) [0|255] ""  LDM_L,LDM_R
 SG_ CAM_Obj6_HozlDst : 14|9@0+ (1,0) [0|511] "m"  LDM_L,LDM_R
 SG_ CAM_Obj6_Valid : 15|1@0+ (1,0) [0|1] ""  LDM_L,LDM_R
 SG_ CAM_Obj6_HozlPosnRi : 19|10@0+ (0.08,-40) [-40|40] "degree"  LDM_L,LDM_R
 SG_ CAM_Obj6_Typ : 21|2@0+ (1,0) [0|3] ""  LDM_L,LDM_R
 SG_ CAM_Obj6_HozlPosnLe : 25|10@0+ (0.08,-40) [-40|40] "degree"  LDM_L,LDM_R
 SG_ CAM_Obj6_VertPosn : 47|8@0+ (0.1,-12) [-12|12] "degree"  LDM_L,LDM_R
 SG_ CAM_Obj6_HozlSpdLe : 55|8@0+ (0.5,-64) [-64|63.5] "degree/s"  LDM_L,LDM_R
 SG_ CAM_Obj6_HozlSpdRi : 63|8@0+ (0.5,-64) [-64|63.5] "degree/s"  LDM_L,LDM_R

BO_ 414 CAM_MSG8: 8 ADAS_Body
 SG_ CAM_Obj7_ID : 7|8@0+ (1,0) [0|255] ""  LDM_L,LDM_R
 SG_ CAM_Obj7_HozlDst : 14|9@0+ (1,0) [0|511] "m"  LDM_L,LDM_R
 SG_ CAM_Obj7_Valid : 15|1@0+ (1,0) [0|1] ""  LDM_L,LDM_R
 SG_ CAM_Obj7_HozlPosnRi : 19|10@0+ (0.08,-40) [-40|40] "degree"  LDM_L,LDM_R
 SG_ CAM_Obj7_Typ : 21|2@0+ (1,0) [0|3] ""  LDM_L,LDM_R
 SG_ CAM_Obj7_HozlPosnLe : 25|10@0+ (0.08,-40) [-40|40] "degree"  LDM_L,LDM_R
 SG_ CAM_Obj7_VertPosn : 47|8@0+ (0.1,-12) [-12|12] "degree"  LDM_L,LDM_R
 SG_ CAM_Obj7_HozlSpdLe : 55|8@0+ (0.5,-64) [-64|63.5] "degree/s"  LDM_L,LDM_R
 SG_ CAM_Obj7_HozlSpdRi : 63|8@0+ (0.5,-64) [-64|63.5] "degree/s"  LDM_L,LDM_R

BO_ 415 CAM_MSG9: 8 ADAS_Body
 SG_ CAM_Obj8_ID : 7|8@0+ (1,0) [0|255] ""  LDM_L,LDM_R
 SG_ CAM_Obj8_HozlDst : 14|9@0+ (1,0) [0|511] "m"  LDM_L,LDM_R
 SG_ CAM_Obj8_Valid : 15|1@0+ (1,0) [0|1] ""  LDM_L,LDM_R
 SG_ CAM_Obj8_HozlPosnRi : 19|10@0+ (0.08,-40) [-40|40] "degree"  LDM_L,LDM_R
 SG_ CAM_Obj8_Typ : 21|2@0+ (1,0) [0|3] ""  LDM_L,LDM_R
 SG_ CAM_Obj8_HozlPosnLe : 25|10@0+ (0.08,-40) [-40|40] "degree"  LDM_L,LDM_R
 SG_ CAM_Obj8_VertPosn : 47|8@0+ (0.1,-12) [-12|12] "degree"  LDM_L,LDM_R
 SG_ CAM_Obj8_HozlSpdLe : 55|8@0+ (0.5,-64) [-64|63.5] "degree/s"  LDM_L,LDM_R
 SG_ CAM_Obj8_HozlSpdRi : 63|8@0+ (0.5,-64) [-64|63.5] "degree/s"  LDM_L,LDM_R

BO_ 417 IDB_V_VEH: 5 XGW_Body
 SG_ CHSKM_V_VEH : 7|8@0+ (1,0) [0|255] ""  ACM
 SG_ ALIV_V_VEH : 11|4@0+ (1,0) [0|14] ""  ACM
 SG_ V_VEH_COG : 23|16@0+ (0.015625,0) [0|350] "km/h"  ACM
 SG_ DVCO_VEH : 35|3@0+ (1,0) [0|7] ""  ACM
 SG_ QU_V_VEH_COG : 39|4@0+ (1,0) [0|15] ""  ACM

BO_ 504 EDS_OutPut_FR: 8 XGW_Body
 SG_ CHKSM_EDS_OutPut_FR : 7|8@0+ (1,0) [0|255] ""  ACM,ADAS_Body,APM,ASU_Gateway,BCM_BPM,CCU_F,CCU_R,ETG,LDM_L,LDM_R,OCS_P,PSM_D,SHVU_F,SHVU_R,TRM
 SG_ ALV_EDS_OutPut_FR : 11|4@0+ (1,0) [0|14] ""  ACM,ADAS_Body,APM,ASU_Gateway,BCM_BPM,CCU_F,CCU_R,ETG,LDM_L,LDM_R,OCS_P,PSM_D,SHVU_F,SHVU_R,TRM
 SG_ EDS_Work_STS_FR : 15|4@0+ (1,0) [0|15] "-"  ACM,ADAS_Body,APM,ASU_Gateway,BCM_BPM,CCU_F,CCU_R,ETG,LDM_L,LDM_R,OCS_P,PSM_D,SHVU_F,SHVU_R,TRM
 SG_ EDS_Spd_FR : 23|16@0+ (1,-20000) [-20000|20000] "rpm"  ACM,ADAS_Body,APM,ASU_Gateway,BCM_BPM,CCU_F,CCU_R,ETG,LDM_L,LDM_R,OCS_P,PSM_D,SHVU_F,SHVU_R,TRM
 SG_ EDS_output_trqValid_FR : 33|2@0+ (1,0) [0|1] ""  ACM,ADAS_Body,APM,ASU_Gateway,BCM_BPM,CCU_F,CCU_R,ETG,LDM_L,LDM_R,OCS_P,PSM_D,SHVU_F,SHVU_R,TRM
 SG_ EDS_MotorDriveSts_FR : 35|2@0+ (1,0) [0|3] ""  ACM,ADAS_Body,APM,ASU_Gateway,BCM_BPM,CCU_F,CCU_R,ETG,LDM_L,LDM_R,OCS_P,PSM_D,SHVU_F,SHVU_R,TRM
 SG_ EDS_powoff_req_FR : 37|2@0+ (1,0) [0|1] ""  ACM,ADAS_Body,APM,ASU_Gateway,BCM_BPM,CCU_F,CCU_R,ETG,LDM_L,LDM_R,OCS_P,PSM_D,SHVU_F,SHVU_R,TRM
 SG_ EDS_SpdValid_FR : 39|2@0+ (1,0) [0|1] ""  ACM,ADAS_Body,APM,ASU_Gateway,BCM_BPM,CCU_F,CCU_R,ETG,LDM_L,LDM_R,OCS_P,PSM_D,SHVU_F,SHVU_R,TRM
 SG_ EDS_output_trq_FR : 47|16@0+ (1,-2000) [-2000|2000] "Nm"  ACM,ADAS_Body,APM,ASU_Gateway,BCM_BPM,CCU_F,CCU_R,ETG,LDM_L,LDM_R,OCS_P,PSM_D,SHVU_F,SHVU_R,TRM
 SG_ EDS_VCU_6SO_flag_FWD : 63|2@0+ (1,0) [0|1] ""  ACM,ADAS_Body,APM,ASU_Gateway,BCM_BPM,CCU_F,CCU_R,ETG,LDM_L,LDM_R,OCS_P,PSM_D,SHVU_F,SHVU_R,TRM

BO_ 505 EDS_OutPut_RR: 8 XGW_Body
 SG_ CHKSM_EDS_OutPut_RR : 7|8@0+ (1,0) [0|255] ""  ACM,ADAS_Body,APM,ASU_Gateway,BCM_BPM,CCU_F,CCU_R,ETG,LDM_L,LDM_R,OCS_P,PSM_D,SHVU_F,SHVU_R,TRM
 SG_ ALV_EDS_OutPut_RR : 11|4@0+ (1,0) [0|14] ""  ACM,ADAS_Body,APM,ASU_Gateway,BCM_BPM,CCU_F,CCU_R,ETG,LDM_L,LDM_R,OCS_P,PSM_D,SHVU_F,SHVU_R,TRM
 SG_ EDS_Work_STS_RR : 15|4@0+ (1,0) [0|15] "-"  ACM,ADAS_Body,APM,ASU_Gateway,BCM_BPM,CCU_F,CCU_R,ETG,LDM_L,LDM_R,OCS_P,PSM_D,SHVU_F,SHVU_R,TRM
 SG_ EDS_Spd_RR : 23|16@0+ (1,-20000) [-20000|20000] "rpm"  ACM,ADAS_Body,APM,ASU_Gateway,BCM_BPM,CCU_F,CCU_R,ETG,LDM_L,LDM_R,OCS_P,PSM_D,SHVU_F,SHVU_R,TRM
 SG_ EDS_output_trqValid_RR : 33|2@0+ (1,0) [0|1] ""  ACM,ADAS_Body,APM,ASU_Gateway,BCM_BPM,CCU_F,CCU_R,ETG,LDM_L,LDM_R,OCS_P,PSM_D,SHVU_F,SHVU_R,TRM
 SG_ EDS_MotorDriveSts_RR : 35|2@0+ (1,0) [0|3] ""  ACM,ADAS_Body,APM,ASU_Gateway,BCM_BPM,CCU_F,CCU_R,ETG,LDM_L,LDM_R,OCS_P,PSM_D,SHVU_F,SHVU_R,TRM
 SG_ EDS_powoff_req_RR : 37|2@0+ (1,0) [0|1] ""  ACM,ADAS_Body,APM,ASU_Gateway,BCM_BPM,CCU_F,CCU_R,ETG,LDM_L,LDM_R,OCS_P,PSM_D,SHVU_F,SHVU_R,TRM
 SG_ EDS_SpdValid_RR : 39|2@0+ (1,0) [0|1] ""  ACM,ADAS_Body,APM,ASU_Gateway,BCM_BPM,CCU_F,CCU_R,ETG,LDM_L,LDM_R,OCS_P,PSM_D,SHVU_F,SHVU_R,TRM
 SG_ EDS_output_trq_RR : 47|16@0+ (1,-2000) [-2000|2000] "Nm"  ACM,ADAS_Body,APM,ASU_Gateway,BCM_BPM,CCU_F,CCU_R,ETG,LDM_L,LDM_R,OCS_P,PSM_D,SHVU_F,SHVU_R,TRM
 SG_ EDS_VCU_6SO_flag_RWD : 63|2@0+ (1,0) [0|1] "-"  ACM,ADAS_Body,APM,ASU_Gateway,BCM_BPM,CCU_F,CCU_R,ETG,LDM_L,LDM_R,OCS_P,PSM_D,SHVU_F,SHVU_R,TRM

BO_ 519 BCM_SunroofSts: 8 BCM
 SG_ SR_Undervoltage_Fault_Sts : 0|1@0+ (1,0) [0|1] ""  XGW_Body
 SG_ SR_Overvoltage_Fault_Sts : 1|1@0+ (1,0) [0|1] ""  XGW_Body
 SG_ SR_SLEEP_RQ : 2|1@0+ (1,0) [0|1] "-"  XGW_Body
 SG_ SR_Position : 5|3@0+ (1,0) [0|7] ""  XGW_Body
 SG_ SR_Motor_Running_Sts : 7|2@0+ (1,0) [0|3] ""  XGW_Body
 SG_ SR_MotorReverse_Fault_Sts : 8|1@0+ (1,0) [0|1] ""  XGW_Body
 SG_ SR_Hall_Fault_Sts : 9|1@0+ (1,0) [0|1] ""  XGW_Body
 SG_ SR_Normalisation_Sts : 10|1@0+ (1,0) [0|1] ""  XGW_Body
 SG_ SR_Relay_Fault : 11|1@0+ (1,0) [0|1] ""  XGW_Body
 SG_ SR_Commu_Fault_Sts : 12|1@0+ (1,0) [0|1] ""  XGW_Body
 SG_ SR_Initialisation_Status : 13|1@0+ (1,0) [0|1] ""  XGW_Body
 SG_ SR_Ctrl_Result : 15|2@0+ (1,0) [0|3] ""  XGW_Body
 SG_ SR_ThermalProtection_Fault_Sts : 16|1@0+ (1,0) [0|1] "-"  XGW_Body
 SG_ SR_Posit_Percentage : 23|7@0+ (1,0) [0|100] "%"  XGW_Body
 SG_ SR_Operation_Stat : 27|4@0+ (1,0) [0|8] "-"  XGW_Body
 SG_ SR_Error_RSP : 28|1@0+ (1,0) [0|1] ""  XGW_Body
 SG_ BCM_AutoSunroof_Sts : 30|2@0+ (1,0) [0|3] ""  XGW_Body

BO_ 520 BCM_SunshadeSts: 8 BCM
 SG_ SS_MotorReverse_Fault_Status : 0|1@0+ (1,0) [0|1] ""  XGW_Body
 SG_ SS_Motor_Running_Status : 2|2@0+ (1,0) [0|3] ""  XGW_Body
 SG_ SS_Position : 5|3@0+ (1,0) [0|7] ""  XGW_Body
 SG_ SS_SLEEP_RQ : 6|1@0+ (1,0) [0|1] "-"  XGW_Body
 SG_ SS_Undervoltage_Fault_Status : 7|1@0+ (1,0) [0|1] ""  XGW_Body
 SG_ SS_Ctrl_Result : 9|2@0+ (1,0) [0|3] ""  XGW_Body
 SG_ SS_Overvoltage_Fault_Status : 10|1@0+ (1,0) [0|1] ""  XGW_Body
 SG_ SS_Relay_Fault : 11|1@0+ (1,0) [0|1] ""  XGW_Body
 SG_ SS_Normalisation_Status : 12|1@0+ (1,0) [0|1] ""  XGW_Body
 SG_ SS_Hall_Fault_Status : 13|1@0+ (1,0) [0|1] ""  XGW_Body
 SG_ SS_Commu_Fault_Status : 14|1@0+ (1,0) [0|1] ""  XGW_Body
 SG_ SS_Initialisation_Status : 15|1@0+ (1,0) [0|1] ""  XGW_Body
 SG_ SS_Posit_Percentage : 22|7@0+ (1,0) [0|100] "%"  XGW_Body
 SG_ SS_ThermalProtection_Flt_Sts : 23|1@0+ (1,0) [0|1] ""  XGW_Body
 SG_ SS_Operation_State : 31|3@0+ (1,0) [0|7] ""  XGW_Body
 SG_ SECCAN_SunshadeSts : 55|8@0+ (1,0) [0|255] ""  XGW_Body
 SG_ SS_Error_RSP : 63|1@0+ (1,0) [0|1] ""  XGW_Body

BO_ 522 ETG_STATUS: 8 ETG
 SG_ ETG_Lift_Gate_Status : 2|3@0+ (1,0) [0|7] "-"  BCM,XGW_Body
 SG_ ETG_Power_Latch_Status : 5|3@0+ (1,0) [0|7] "-"  BCM,XGW_Body
 SG_ ETG_Latch_Segment : 7|2@0+ (1,0) [0|3] ""  BCM,XGW_Body
 SG_ ETG_Opening_Percentage : 15|8@0+ (1,0) [0|100] "%"  BCM,XGW_Body
 SG_ ETG_DSW_Status : 16|1@0+ (1,0) [0|1] ""  BCM,XGW_Body
 SG_ ETG_GSW_Status : 17|1@0+ (1,0) [0|1] ""  BCM,XGW_Body
 SG_ ETG_LTS_Status : 18|1@0+ (1,0) [0|1] "-"  BCM,XGW_Body
 SG_ ETG_RTS_Status : 19|1@0+ (1,0) [0|1] "-"  BCM,XGW_Body
 SG_ ETG_HAL_Status : 20|1@0+ (1,0) [0|1] "-"  BCM,XGW_Body
 SG_ ETG_FUL_Status : 21|1@0+ (1,0) [0|1] "-"  BCM,XGW_Body
 SG_ ETG_AJR_Status : 22|1@0+ (1,0) [0|1] ""  BCM,XGW_Body
 SG_ ETG_NTL_Status : 23|1@0+ (1,0) [0|1] "-"  BCM,XGW_Body
 SG_ ETG_ERR_Voltage : 25|2@0+ (1,0) [0|3] "-"  BCM,XGW_Body
 SG_ ETG_ERR_Left_Motor : 27|2@0+ (1,0) [0|3] ""  BCM,XGW_Body
 SG_ ETG_ERR_Right_Motor : 29|2@0+ (1,0) [0|3] "-"  BCM,XGW_Body
 SG_ ETG_ERR_Latch : 31|2@0+ (1,0) [0|3] "-"  BCM,XGW_Body
 SG_ ETG_ERR_Hall : 33|2@0+ (1,0) [0|3] ""  BCM,XGW_Body
 SG_ ETG_Lift_Motor_Stall : 34|1@0+ (1,0) [0|1] ""  BCM,XGW_Body
 SG_ ETG_Lift_Motor_AntiPinch : 35|1@0+ (1,0) [0|1] "-"  BCM,XGW_Body
 SG_ ETG_Lift_Motor_Thermal : 36|1@0+ (1,0) [0|1] ""  BCM,XGW_Body
 SG_ ETG_Power_Latch_Thermal : 37|1@0+ (1,0) [0|1] "-"  BCM,XGW_Body
 SG_ ETG_Abuse_Protection : 38|1@0+ (1,0) [0|1] ""  BCM,XGW_Body

BO_ 523 BCM_FKS_STATUS: 2 BCM
 SG_ FKS_RespError : 0|1@0+ (1,0) [0|1] "-"  XGW_Body
 SG_ FKS_OpenReq : 2|2@0+ (1,0) [0|3] ""  XGW_Body
 SG_ FKS_HWError : 3|1@0+ (1,0) [0|1] "-"  XGW_Body
 SG_ FKS_AntennaError : 5|2@0+ (1,0) [0|3] "-"  XGW_Body
 SG_ FKS_OverVolDected : 6|1@0+ (1,0) [0|1] "-"  XGW_Body
 SG_ FKS_UnderVolDected : 7|1@0+ (1,0) [0|1] "-"  XGW_Body
 SG_ FKS_activate_deactivate : 10|2@0+ (1,0) [0|3] "-"  XGW_Body

BO_ 524 IC_ODO: 8 XGW_Body
 SG_ CHKSM_IC_ODO : 7|8@0+ (1,0) [0|255] ""  ACM,ADAS_Body,ASU_Gateway,BCM,CCU_R,LDM_L,LDM_R,OCS_P,PSM_D,SHVU_F,SHVU_R
 SG_ ALIV_IC_ODO : 11|4@0+ (1,0) [0|14] ""  ACM,ADAS_Body,ASU_Gateway,BCM,CCU_R,LDM_L,LDM_R,OCS_P,PSM_D,SHVU_F,SHVU_R
 SG_ MHU_Odometer_IC : 23|20@0+ (1,0) [0|999999] "km"  ACM,ADAS_Body,ASU_Gateway,BCM,CCU_R,LDM_L,LDM_R,OCS_P,PSM_D,SHVU_F,SHVU_R

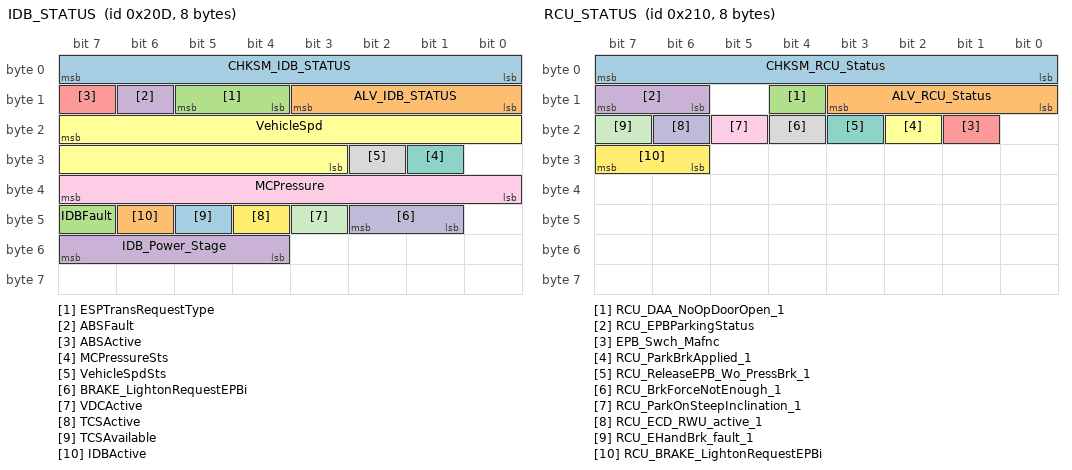
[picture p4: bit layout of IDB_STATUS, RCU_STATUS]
BO_ 525 IDB_STATUS: 8 XGW_Body
 SG_ CHKSM_IDB_STATUS : 7|8@0+ (1,0) [0|255] ""  ACM,APM,ASU_Gateway,BCM,CCU_F,CCU_R,ETG,LDM_L,LDM_R,OCS_P,PSM_D,SHVU_F,SHVU_R,TRM
 SG_ ALV_IDB_STATUS : 11|4@0+ (1,0) [0|14] ""  ACM,APM,ASU_Gateway,BCM,CCU_F,CCU_R,ETG,LDM_L,LDM_R,OCS_P,PSM_D,SHVU_F,SHVU_R,TRM
 SG_ ESPTransRequestType : 13|2@0+ (1,0) [0|3] ""  APM,CCU_F,CCU_R,ETG,TRM
 SG_ ABSFault : 14|1@0+ (1,0) [0|1] ""  ACM,APM,CCU_F,CCU_R,ETG,TRM
 SG_ ABSActive : 15|1@0+ (1,0) [0|1] ""  ACM,APM,CCU_F,CCU_R,ETG,TRM
 SG_ VehicleSpd : 23|13@0+ (0.05625,0) [0|300] "km/h"  ACM,ADAS_Body,APM,ASU_Gateway,BCM,BCM_BPM,CCU_F,CCU_R,ETG,LDM_L,LDM_R,OCS_P,PSM_D,SHVU_F,SHVU_R,TRM
 SG_ MCPressureSts : 25|1@0+ (1,0) [0|1] ""  APM,ASU_Gateway,CCU_F,CCU_R,ETG,TRM
 SG_ VehicleSpdSts : 26|1@0+ (1,0) [0|1] ""  ACM,APM,ASU_Gateway,BCM,CCU_F,CCU_R,ETG,LDM_L,LDM_R,OCS_P,PSM_D,SHVU_F,SHVU_R,TRM
 SG_ MCPressure : 39|8@0+ (2,-42.5) [-42.5|465.5] "bar"  APM,ASU_Gateway,CCU_F,CCU_R,ETG,TRM
 SG_ BRAKE_LightonRequestEPBi : 42|2@0+ (1,0) [0|3] ""  APM,BCM,CCU_F,CCU_R,ETG,TRM
 SG_ VDCActive : 43|1@0+ (1,0) [0|1] ""  APM,CCU_F,CCU_R,ETG,TRM
 SG_ TCSActive : 44|1@0+ (1,0) [0|1] ""  APM,CCU_F,CCU_R,ETG,TRM
 SG_ TCSAvailable : 45|1@0+ (1,0) [0|1] ""  APM,CCU_F,CCU_R,ETG,TRM
 SG_ IDBActive : 46|1@0+ (1,0) [0|1] ""  ACM,APM,CCU_F,CCU_R,ETG,TRM
 SG_ IDBFault : 47|1@0+ (1,0) [0|1] ""  ACM,APM,CCU_F,CCU_R,ETG,TRM
 SG_ IDB_Power_Stage : 55|4@0+ (1,0) [0|15] ""  APM,CCU_F,CCU_R,ETG,TRM

BO_ 527 ADAS_BCM_Status: 8 ADAS_Body
 SG_ ADAS_BCM_Status : 2|3@0+ (1,0) [0|7] ""  BCM
 SG_ ADAS_BCM_HeadlightReq : 3|1@0+ (1,0) [0|1] ""  BCM
 SG_ ADAS_BCM_IndicatorlightReq : 7|3@0+ (1,0) [0|7] ""  BCM
 SG_ ADAS_BCM_FoldMirrorReq : 15|2@0+ (1,0) [0|3] ""  BCM
 SG_ SECCAN_ADAS_BCM_Sts : 63|8@0+ (1,0) [0|255] ""  BCM

BO_ 528 RCU_STATUS: 8 XGW_Body
 SG_ CHKSM_RCU_Status : 7|8@0+ (1,0) [0|255] "" BCM
 SG_ ALV_RCU_Status : 11|4@0+ (1,0) [0|14] "" BCM
 SG_ RCU_DAA_NoOpDoorOpen_1 : 12|1@0+ (1,0) [0|1] "" BCM
 SG_ RCU_EPBParkingStatus : 15|2@0+ (1,0) [0|3] "" BCM
 SG_ EPB_Swch_Mafnc : 17|1@0+ (1,0) [0|1] "" BCM
 SG_ RCU_ParkBrkApplied_1 : 18|1@0+ (1,0) [0|1] "" BCM
 SG_ RCU_ReleaseEPB_Wo_PressBrk_1 : 19|1@0+ (1,0) [0|1] "" BCM
 SG_ RCU_BrkForceNotEnough_1 : 20|1@0+ (1,0) [0|1] "" BCM
 SG_ RCU_ParkOnSteepInclination_1 : 21|1@0+ (1,0) [0|1] "" BCM
 SG_ RCU_ECD_RWU_active_1 : 22|1@0+ (1,0) [0|1] "" BCM
 SG_ RCU_EHandBrk_fault_1 : 23|1@0+ (1,0) [0|1] "" BCM
 SG_ RCU_BRAKE_LightonRequestEPBi : 31|2@0+ (1,0) [0|3] "" BCM

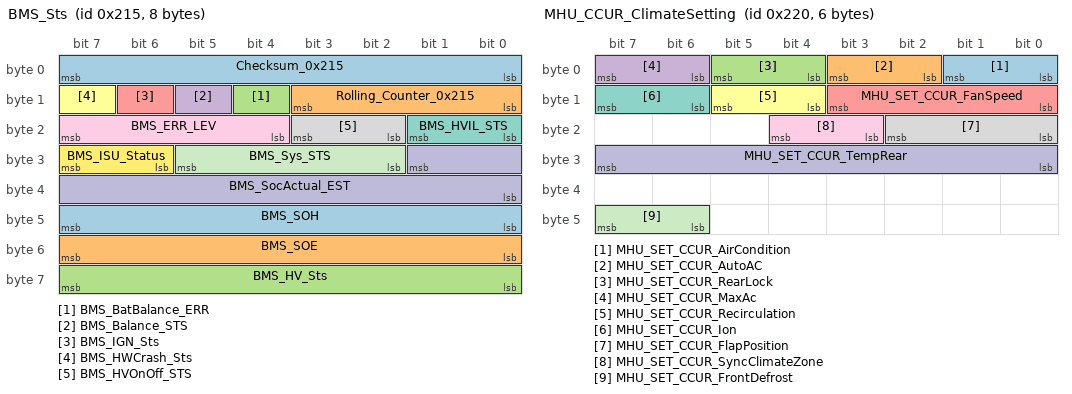
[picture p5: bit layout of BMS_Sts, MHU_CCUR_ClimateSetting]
BO_ 533 BMS_Sts: 8 XGW_Body
 SG_ Checksum_0x215 : 7|8@0+ (1,0) [0|255] ""  BCM,DUMMY_ECU
 SG_ Rolling_Counter_0x215 : 11|4@0+ (1,0) [0|14] ""  BCM,DUMMY_ECU
 SG_ BMS_BatBalance_ERR : 12|1@0+ (1,0) [0|1] ""  DUMMY_ECU
 SG_ BMS_Balance_STS : 13|1@0+ (1,0) [0|1] ""  DUMMY_ECU
 SG_ BMS_IGN_Sts : 14|1@0+ (1,0) [0|1] ""  DUMMY_ECU
 SG_ BMS_HWCrash_Sts : 15|1@0+ (1,0) [0|1] ""  DUMMY_ECU
 SG_ BMS_HVIL_STS : 17|2@0+ (1,0) [0|3] ""  DUMMY_ECU
 SG_ BMS_HVOnOff_STS : 19|2@0+ (1,0) [0|3] ""  BCM,DUMMY_ECU
 SG_ BMS_ERR_LEV : 23|4@0+ (1,0) [0|7] "-"  DUMMY_ECU
 SG_ BMS_SocActual_EST : 25|10@0+ (0.1,0) [0|100] "%"  BCM
 SG_ BMS_Sys_STS : 29|4@0+ (1,0) [0|15] ""  DUMMY_ECU
 SG_ BMS_ISU_Status : 31|2@0+ (1,0) [0|3] ""  DUMMY_ECU
 SG_ BMS_SOH : 47|8@0+ (0.5,0) [0|100] "%"  DUMMY_ECU
 SG_ BMS_SOE : 55|8@0+ (0.5,0) [0|100] "%"  DUMMY_ECU
 SG_ BMS_HV_Sts : 63|8@0+ (1,0) [0|255] ""  DUMMY_ECU

BO_ 537 VCU_PTControl: 8 XGW_Body
 SG_ CHSKM_VCU_PTControl : 7|8@0+ (1,0) [0|255] ""  BCM
 SG_ ALV_VCU_PTControl : 11|4@0+ (1,0) [0|14] ""  BCM
 SG_ VCU_ChargeAllow : 54|1@0+ (1,0) [0|1] ""  BCM

BO_ 544 MHU_CCUR_ClimateSetting: 6 XGW_Body
 SG_ MHU_SET_CCUR_AirCondition : 1|2@0+ (1,0) [0|3] "-"  CCU_F
 SG_ MHU_SET_CCUR_AutoAC : 3|2@0+ (1,0) [0|3] "-"  CCU_F
 SG_ MHU_SET_CCUR_RearLock : 5|2@0+ (1,0) [0|3] "-"  CCU_F
 SG_ MHU_SET_CCUR_MaxAc : 7|2@0+ (1,0) [0|3] ""  CCU_F
 SG_ MHU_SET_CCUR_FanSpeed : 11|4@0+ (1,0) [0|7] "-"  CCU_F
 SG_ MHU_SET_CCUR_Recirculation : 13|2@0+ (1,0) [0|3] "-"  CCU_F
 SG_ MHU_SET_CCUR_Ion : 15|2@0+ (1,0) [0|3] ""  CCU_F
 SG_ MHU_SET_CCUR_FlapPosition : 18|3@0+ (1,0) [0|7] "-"  CCU_F
 SG_ MHU_SET_CCUR_SyncClimateZone : 20|2@0+ (1,0) [0|3] "-"  CCU_F
 SG_ MHU_SET_CCUR_TempRear : 31|8@0+ (0.5,0) [16|32] "Degree C"  CCU_F
 SG_ MHU_SET_CCUR_FrontDefrost : 47|2@0+ (1,0) [0|3] ""  CCU_F

BO_ 545 CCUR_ClimateSetting: 8 CCU_R
 SG_ CCUR_Req_AirCondition : 1|2@0+ (1,0) [0|3] ""  CCU_F,XGW_Body
 SG_ CCUR_AirDistribFlapActPos : 15|8@0+ (0.5,0) [0|100] ""  CCU_F
 SG_ CCUR_TempFlapActPos : 23|8@0+ (0.5,0) [0|100] ""  CCU_F
 SG_ SECCAN_CCUR : 63|8@0+ (1,0) [0|255] ""  CCU_F,XGW_Body

BO_ 546 CCUF_ClimateSetting: 8 CCU_F
 SG_ FRONT_SET_Rear_AirCondition : 1|2@0+ (1,0) [0|3] ""  CCU_R,XGW_Body
 SG_ SECCAN_CCUF : 63|8@0+ (1,0) [0|255] ""  CCU_R,XGW_Body

BO_ 547 DoorFLCommand: 8 BCM
 SG_ NDoorFLVehicleLocked : 1|2@0+ (1,0) [0|3] ""  DUMMY_ECU
 SG_ NDoorFLVehicleMoving : 3|2@0+ (1,0) [0|3] ""  DUMMY_ECU
 SG_ NDoorFLOpenInvRequested : 5|2@0+ (1,0) [0|3] ""  XGW_Body
 SG_ NDoorFLOpenRequested : 7|2@0+ (1,0) [0|3] ""  XGW_Body
 SG_ NDoorFLChildLocked : 9|2@0+ (1,0) [0|3] ""  DUMMY_ECU
 SG_ NDoorFLVehicleCrash : 11|2@0+ (1,0) [0|3] ""  DUMMY_ECU
 SG_ NDoorFLCommandCounter : 23|8@0+ (1,0) [0|255] ""  XGW_Body
 SG_ NDoorFLCloseInvRequested : 25|2@0+ (1,0) [0|3] ""  XGW_Body
 SG_ NDoorFLCloseRequested : 27|2@0+ (1,0) [0|3] ""  XGW_Body

BO_ 548 VCU_BMS_Thermal_FB: 8 XGW_Body
 SG_ CHSKM_VCU_BMS_Thermal_FB : 7|8@0+ (1,0) [0|255] ""  BCM
 SG_ ALIV_VCU_BMS_Thermal_FB : 11|4@0+ (1,0) [0|14] ""  BCM
 SG_ VCU_BMS_PTCOnOff_Sts : 12|1@0+ (1,0) [0|1] ""  BCM
 SG_ VCU_BMS_ValveOnOff_Sts : 13|1@0+ (1,0) [0|1] ""  BCM
 SG_ VCU_BMS_PumpFB : 18|3@0+ (1,0) [0|3] ""  BCM

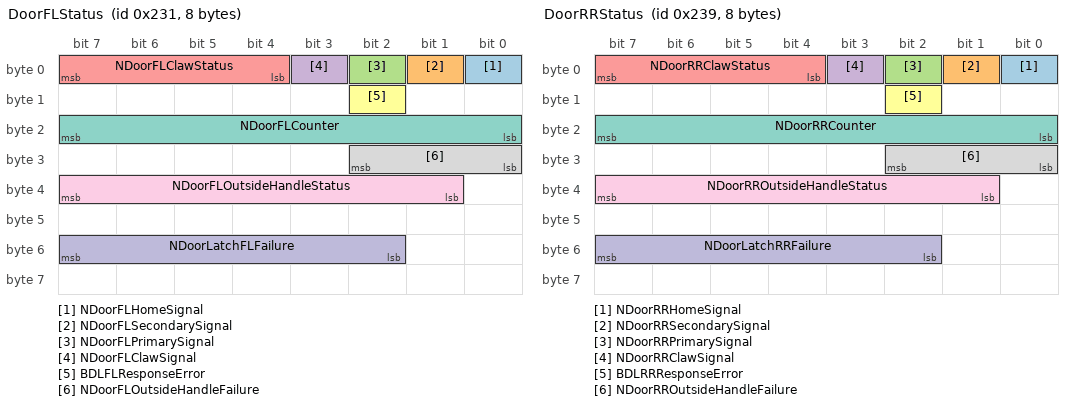
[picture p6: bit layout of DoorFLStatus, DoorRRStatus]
BO_ 561 DoorFLStatus: 8 XGW_Body
 SG_ NDoorFLHomeSignal : 0|1@0+ (1,0) [0|1] ""  BCM
 SG_ NDoorFLSecondarySignal : 1|1@0+ (1,0) [0|1] ""  BCM
 SG_ NDoorFLPrimarySignal : 2|1@0+ (1,0) [0|1] ""  BCM
 SG_ NDoorFLClawSignal : 3|1@0+ (1,0) [0|1] ""  BCM
 SG_ NDoorFLClawStatus : 7|4@0+ (1,0) [0|15] ""  BCM
 SG_ BDLFLResponseError : 10|1@0+ (1,0) [0|1] ""  BCM
 SG_ NDoorFLCounter : 23|8@0+ (1,0) [0|255] ""  BCM
 SG_ NDoorFLOutsideHandleFailure : 26|3@0+ (1,0) [0|7] ""  BCM
 SG_ NDoorFLOutsideHandleStatus : 39|7@0+ (1,0) [0|127] ""  BCM
 SG_ NDoorLatchFLFailure : 55|6@0+ (1,0) [0|63] ""  BCM

BO_ 565 TRM_STATUS: 3 TRM
 SG_ CHKSM_TRM_STATUS : 7|8@0+ (1,0) [0|255] ""  ADAS_Body,XGW_Body
 SG_ ALIVE_TRM_STATUS : 11|4@0+ (1,0) [0|14] ""  ADAS_Body,XGW_Body
 SG_ TowingDetected : 21|2@0+ (1,0) [0|3] ""  ADAS_Body,XGW_Body
 SG_ TrailerDetected : 23|2@0+ (1,0) [0|3] ""  ADAS_Body,ASU_Gateway,XGW_Body

BO_ 569 DoorRRStatus: 8 XGW_Body
 SG_ NDoorRRHomeSignal : 0|1@0+ (1,0) [0|1] ""  BCM
 SG_ NDoorRRSecondarySignal : 1|1@0+ (1,0) [0|1] ""  BCM
 SG_ NDoorRRPrimarySignal : 2|1@0+ (1,0) [0|1] ""  BCM
 SG_ NDoorRRClawSignal : 3|1@0+ (1,0) [0|1] ""  BCM
 SG_ NDoorRRClawStatus : 7|4@0+ (1,0) [0|15] ""  BCM
 SG_ BDLRRResponseError : 10|1@0+ (1,0) [0|1] ""  BCM
 SG_ NDoorRRCounter : 23|8@0+ (1,0) [0|255] ""  BCM
 SG_ NDoorRROutsideHandleFailure : 26|3@0+ (1,0) [0|7] ""  BCM
 SG_ NDoorRROutsideHandleStatus : 39|7@0+ (1,0) [0|127] ""  BCM
 SG_ NDoorLatchRRFailure : 55|6@0+ (1,0) [0|63] ""  BCM

BO_ 578 DoorFRCommand: 8 BCM
 SG_ NDoorFRVehicleLocked : 1|2@0+ (1,0) [0|3] ""  DUMMY_ECU
 SG_ NDoorFRVehicleMoving : 3|2@0+ (1,0) [0|3] ""  DUMMY_ECU
 SG_ NDoorFROpenInvRequested : 5|2@0+ (1,0) [0|3] ""  XGW_Body
 SG_ NDoorFROpenRequested : 7|2@0+ (1,0) [0|3] ""  XGW_Body
 SG_ NDoorFRChildLocked : 9|2@0+ (1,0) [0|3] ""  DUMMY_ECU
 SG_ NDoorFRVehicleCrash : 11|2@0+ (1,0) [0|3] ""  DUMMY_ECU
 SG_ NDoorFRCommandCounter : 23|8@0+ (1,0) [0|255] ""  XGW_Body
 SG_ NDoorFRCloseInvRequested : 25|2@0+ (1,0) [0|3] ""  XGW_Body
 SG_ NDoorFRCloseRequested : 27|2@0+ (1,0) [0|3] ""  XGW_Body

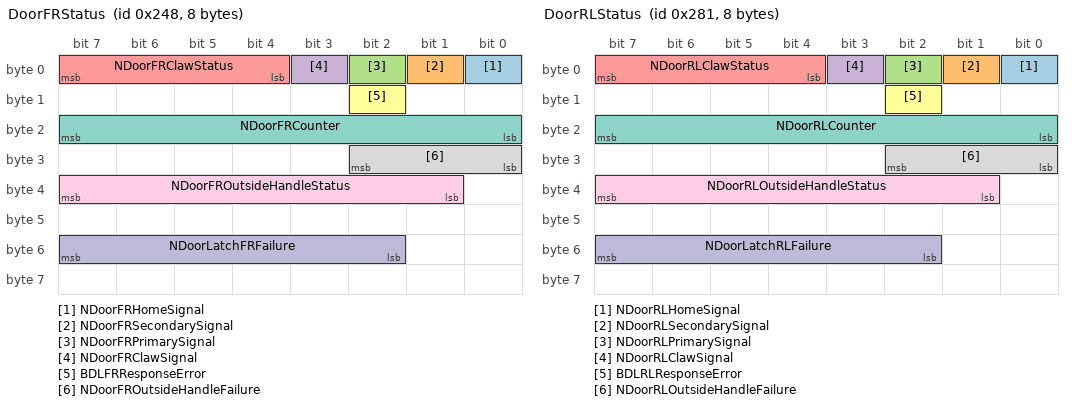
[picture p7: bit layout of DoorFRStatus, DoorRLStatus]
BO_ 584 DoorFRStatus: 8 XGW_Body
 SG_ NDoorFRHomeSignal : 0|1@0+ (1,0) [0|1] ""  BCM
 SG_ NDoorFRSecondarySignal : 1|1@0+ (1,0) [0|1] ""  BCM
 SG_ NDoorFRPrimarySignal : 2|1@0+ (1,0) [0|1] ""  BCM
 SG_ NDoorFRClawSignal : 3|1@0+ (1,0) [0|1] ""  BCM
 SG_ NDoorFRClawStatus : 7|4@0+ (1,0) [0|15] ""  BCM
 SG_ BDLFRResponseError : 10|1@0+ (1,0) [0|1] ""  BCM
 SG_ NDoorFRCounter : 23|8@0+ (1,0) [0|255] ""  BCM
 SG_ NDoorFROutsideHandleFailure : 26|3@0+ (1,0) [0|7] ""  BCM
 SG_ NDoorFROutsideHandleStatus : 39|7@0+ (1,0) [0|127] ""  BCM
 SG_ NDoorLatchFRFailure : 55|6@0+ (1,0) [0|63] ""  BCM

BO_ 592 BMS_VCU_THMReq: 8 XGW_Body
 SG_ CHSKM_BMS_VCU_THMReq : 7|8@0+ (1,0) [0|255] ""  BCM
 SG_ ALV_BMS_VCU_THMReq : 11|4@0+ (1,0) [0|14] ""  BCM
 SG_ BMS_FlowRate_Req : 23|8@0+ (1,0) [0|50] "l/min"  BCM
 SG_ BMS_CoolPwrDemand : 31|12@0+ (0.1,0) [0|10] "kW"  BCM
 SG_ BMS_HeatPwrDemand : 35|12@0+ (0.1,0) [0|10] "kW"  BCM
 SG_ BMS_VCU_PTCOnOff_Req : 48|1@0+ (1,0) [0|1] ""  BCM
 SG_ BMS_VCU_ValveOnOff_Req : 49|1@0+ (1,0) [0|1] ""  BCM
 SG_ BMS_PreHeatCoolReq : 51|2@0+ (1,0) [0|3] "" BCM

BO_ 593 DoorRLCommand: 8 BCM
 SG_ NDoorRLVehicleLocked : 1|2@0+ (1,0) [0|3] ""  DUMMY_ECU
 SG_ NDoorRLVehicleMoving : 3|2@0+ (1,0) [0|3] ""  DUMMY_ECU
 SG_ NDoorRLOpenInvRequested : 5|2@0+ (1,0) [0|3] ""  XGW_Body
 SG_ NDoorRLOpenRequested : 7|2@0+ (1,0) [0|3] ""  XGW_Body
 SG_ NDoorRLChildLocked : 9|2@0+ (1,0) [0|3] ""  DUMMY_ECU
 SG_ NDoorRLVehicleCrash : 11|2@0+ (1,0) [0|3] ""  DUMMY_ECU
 SG_ NDoorRLCommandCounter : 23|8@0+ (1,0) [0|255] ""  XGW_Body
 SG_ NDoorRLCloseInvRequested : 25|2@0+ (1,0) [0|3] ""  XGW_Body
 SG_ NDoorRLCloseRequested : 27|2@0+ (1,0) [0|3] ""  XGW_Body

BO_ 596 IDB_AVL_RPM_WHL_REAR: 8 XGW_Body
 SG_ CRC_AVL_RPM_WHL_REAR : 7|8@0+ (1,0) [0|255] ""  LDM_L,LDM_R
 SG_ ALIV_AVL_RPM_WHL_REAR : 11|4@0+ (1,0) [0|14] ""  LDM_L,LDM_R
 SG_ AVL_RPM_WHL_RLH : 23|16@0+ (0.0156,-511.9844) [-400|400] "rad/s"  LDM_L,LDM_R
 SG_ AVL_RPM_WHL_RRH : 39|16@0+ (0.0156,-511.9844) [-400|400] "rad/s"  LDM_L,LDM_R
 SG_ QU_AVL_RPM_WHL_RLH : 55|4@0+ (1,0) [0|15] "Bit"  LDM_L,LDM_R
 SG_ QU_AVL_RPM_WHL_RRH : 63|4@0+ (1,0) [0|15] "Bit"  LDM_L,LDM_R

BO_ 597 IDB_AVL_RPM_WHL_FRONT: 8 XGW_Body
 SG_ CRC_AVL_RPM_WHL_FRONT : 7|8@0+ (1,0) [0|255] ""  LDM_L,LDM_R
 SG_ ALIV_AVL_RPM_WHL_FRONT : 11|4@0+ (1,0) [0|14] ""  LDM_L,LDM_R
 SG_ AVL_RPM_WHL_FLH : 23|16@0+ (0.0156,-511.9844) [-400|400] "rad/s"  LDM_L,LDM_R
 SG_ AVL_RPM_WHL_FRH : 39|16@0+ (0.0156,-511.9844) [-400|400] "rad/s"  LDM_L,LDM_R
 SG_ QU_AVL_RPM_WHL_FLH : 55|4@0+ (1,0) [0|15] "Bit"  LDM_L,LDM_R
 SG_ QU_AVL_RPM_WHL_FRH : 63|4@0+ (1,0) [0|15] "Bit"  LDM_L,LDM_R

BO_ 598 BCM_LDM_Animation_Info: 8 BCM
 SG_ BCM_Animation_Req : 18|3@0+ (1,0) [0|7] ""  LDM_L,LDM_R
 SG_ BCM_Charging_Sts : 21|3@0+ (1,0) [0|7] ""  LDM_L,LDM_R
 SG_ BCM_Lock_Sts : 23|2@0+ (1,0) [0|3] ""  LDM_L,LDM_R
 SG_ BCM_Panic_Status : 24|1@0+ (1,0) [0|1] ""  LDM_L,LDM_R
 SG_ BCM_Charging_SOC : 28|4@0+ (1,0) [0|15] ""  LDM_L,LDM_R
 SG_ BCM_LeftPosLmpSts : 33|2@0+ (1,0) [0|3] ""  LDM_L
 SG_ BCM_RightPosLmpSts : 35|2@0+ (1,0) [0|3] ""  LDM_R

BO_ 618 ST_LCS_VEH: 3 ASU_Gateway
 SG_ ALIV_ST_LCS_VEH : 0|4@1+ (1,0) [0|14] ""  BCM,DUMMY_ECU
 SG_ ST_ECU_ST_LCS_VEH : 4|4@1+ (1,0) [0|15] ""  BCM,DUMMY_ECU
 SG_ QU_FN_LCS_VEH : 8|12@1+ (1,0) [0|0] ""  BCM,DUMMY_ECU

BO_ 641 DoorRLStatus: 8 XGW_Body
 SG_ NDoorRLHomeSignal : 0|1@0+ (1,0) [0|1] ""  BCM
 SG_ NDoorRLSecondarySignal : 1|1@0+ (1,0) [0|1] ""  BCM
 SG_ NDoorRLPrimarySignal : 2|1@0+ (1,0) [0|1] ""  BCM
 SG_ NDoorRLClawSignal : 3|1@0+ (1,0) [0|1] ""  BCM
 SG_ NDoorRLClawStatus : 7|4@0+ (1,0) [0|15] ""  BCM
 SG_ BDLRLResponseError : 10|1@0+ (1,0) [0|1] ""  BCM
 SG_ NDoorRLCounter : 23|8@0+ (1,0) [0|255] ""  BCM
 SG_ NDoorRLOutsideHandleFailure : 26|3@0+ (1,0) [0|7] ""  BCM
 SG_ NDoorRLOutsideHandleStatus : 39|7@0+ (1,0) [0|127] ""  BCM
 SG_ NDoorLatchRLFailure : 55|6@0+ (1,0) [0|63] ""  BCM

BO_ 649 IDB_ACC_LONG_LAT_YAW: 8 XGW_Body
 SG_ CHKSM_IDB_ZF2 : 7|8@0+ (1,0) [0|255] ""  LDM_L,LDM_R
 SG_ ALIVE_IDB_ZF2 : 11|4@0+ (1,0) [0|14] ""  LDM_L,LDM_R
 SG_ AxOutStatus : 15|3@0+ (1,0) [0|7] ""  LDM_L,LDM_R
 SG_ QU_VYAW_VEH : 19|4@0+ (1,0) [0|15] ""  LDM_L,LDM_R
 SG_ AyOutStatus : 23|3@0+ (1,0) [0|7] ""  LDM_L,LDM_R
 SG_ AcceleratorY : 31|12@0+ (0.02713,-21.5928) [-21.593|21.5928] "m/s^2"  LDM_L,LDM_R
 SG_ AcceleratorX : 35|12@0+ (0.02713,-21.5928) [-21.593|21.5928] "m/s^2"  LDM_L,LDM_R
 SG_ VYAW_VEH : 55|16@0+ (0.005,-163.84) [-163.84|163.83] "°/s"  LDM_L,LDM_R

BO_ 654 APM_WINDOW_POS: 4 APM
 SG_ CHKSM_APM_WINDOW_POS : 7|8@0+ (1,0) [0|255] ""  XGW_Body
 SG_ ALV_APM_WINDOW_POS : 11|4@0+ (1,0) [0|14] ""  XGW_Body
 SG_ Window_PosFL : 14|3@0+ (1,0) [0|7] "-"  XGW_Body
 SG_ Window_Warning : 17|2@0+ (1,0) [0|3] ""  XGW_Body
 SG_ Wndow_PosRL : 20|3@0+ (1,0) [0|7] ""  XGW_Body
 SG_ Window_PosFR : 23|3@0+ (1,0) [0|7] ""  XGW_Body
 SG_ Global_close : 26|2@0+ (1,0) [0|3] ""  XGW_Body
 SG_ Global_open : 28|2@0+ (1,0) [0|3] ""  XGW_Body
 SG_ Window_PosRR : 31|3@0+ (1,0) [0|7] "-"  XGW_Body

BO_ 657 DoorRRCommand: 8 BCM
 SG_ NDoorRRVehicleLocked : 1|2@0+ (1,0) [0|3] ""  DUMMY_ECU
 SG_ NDoorRRVehicleMoving : 3|2@0+ (1,0) [0|3] ""  DUMMY_ECU
 SG_ NDoorRROpenInvRequested : 5|2@0+ (1,0) [0|3] ""  XGW_Body
 SG_ NDoorRROpenRequested : 7|2@0+ (1,0) [0|3] ""  XGW_Body
 SG_ NDoorRRChildLocked : 9|2@0+ (1,0) [0|3] ""  DUMMY_ECU
 SG_ NDoorRRVehicleCrash : 11|2@0+ (1,0) [0|3] ""  DUMMY_ECU
 SG_ NDoorRRCommandCounter : 23|8@0+ (1,0) [0|255] ""  XGW_Body
 SG_ NDoorRRCloseInvRequested : 25|2@0+ (1,0) [0|3] ""  XGW_Body
 SG_ NDoorRRCloseRequested : 27|2@0+ (1,0) [0|3] ""  XGW_Body

BO_ 673 SeatMassage_Input: 8 XGW_Body
 SG_ DrvSeatMsgStrLvl : 7|3@0+ (1,0) [0|7] ""  PSM_D
 SG_ PassSeatMsgStrLvl : 15|3@0+ (1,0) [0|7] ""  PSM_D
 SG_ RearDrvSeatMsgStrLvl : 23|3@0+ (1,0) [0|7] "-"  PSM_D
 SG_ RearPassSeatMsgStrLvl : 31|3@0+ (1,0) [0|7] ""  PSM_D
 SG_ DrvSeatMsgMode : 39|3@0+ (1,0) [0|7] ""  PSM_D
 SG_ PassSeatMsgMode : 47|3@0+ (1,0) [0|7] ""  PSM_D
 SG_ RearDrvSeatMsgMode : 55|3@0+ (1,0) [0|7] ""  PSM_D
 SG_ RearPassSeatMsgMode : 63|3@0+ (1,0) [0|7] "-"  PSM_D

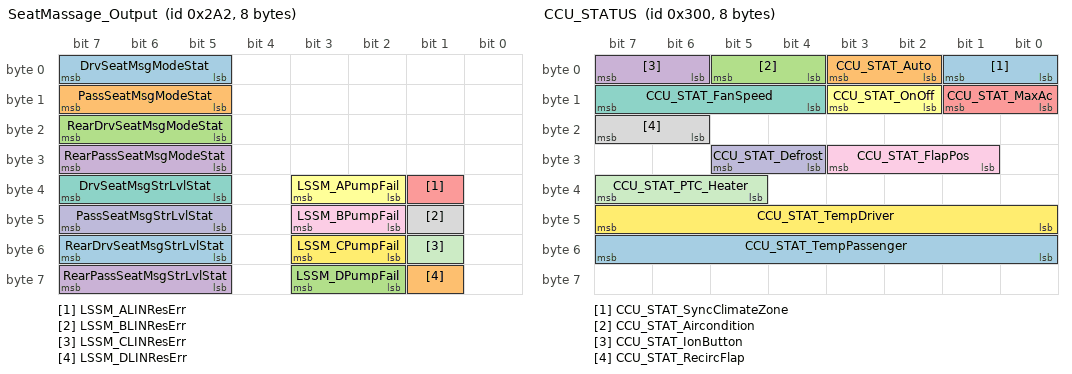
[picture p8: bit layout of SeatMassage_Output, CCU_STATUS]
BO_ 674 SeatMassage_Output: 8 PSM_D
 SG_ DrvSeatMsgModeStat : 7|3@0+ (1,0) [0|7] ""  XGW_Body
 SG_ PassSeatMsgModeStat : 15|3@0+ (1,0) [0|7] ""  XGW_Body
 SG_ RearDrvSeatMsgModeStat : 23|3@0+ (1,0) [0|7] ""  XGW_Body
 SG_ RearPassSeatMsgModeStat : 31|3@0+ (1,0) [0|7] ""  XGW_Body
 SG_ LSSM_ALINResErr : 33|1@0+ (1,0) [0|1] ""  XGW_Body
 SG_ LSSM_APumpFail : 35|2@0+ (1,0) [0|3] ""  XGW_Body
 SG_ DrvSeatMsgStrLvlStat : 39|3@0+ (1,0) [0|7] ""  XGW_Body
 SG_ LSSM_BLINResErr : 41|1@0+ (1,0) [0|1] ""  XGW_Body
 SG_ LSSM_BPumpFail : 43|2@0+ (1,0) [0|3] ""  XGW_Body
 SG_ PassSeatMsgStrLvlStat : 47|3@0+ (1,0) [0|7] "-"  XGW_Body
 SG_ LSSM_CLINResErr : 49|1@0+ (1,0) [0|1] ""  XGW_Body
 SG_ LSSM_CPumpFail : 51|2@0+ (1,0) [0|3] "-"  XGW_Body
 SG_ RearDrvSeatMsgStrLvlStat : 55|3@0+ (1,0) [0|7] "-"  XGW_Body
 SG_ LSSM_DLINResErr : 57|1@0+ (1,0) [0|1] ""  XGW_Body
 SG_ LSSM_DPumpFail : 59|2@0+ (1,0) [0|3] "-"  XGW_Body
 SG_ RearPassSeatMsgStrLvlStat : 63|3@0+ (1,0) [0|7] ""  XGW_Body

BO_ 676 SVC_EHC_EHC_2: 8 ASU_Gateway
 SG_ ID2 M : 0|8@1+ (1,0) [0|0] ""  BCM,XGW_Body
 SG_ ECU_ID_WUPREG m39 : 8|8@1+ (1,0) [0|127] ""  BCM,XGW_Body
 SG_ ID_FN_INQY m1 : 8|16@1+ (1,0) [0|0] ""  BCM,XGW_Body
 SG_ ID_FN_RQ_BUS m12 : 8|16@1+ (1,0) [0|0] ""  BCM,XGW_Body
 SG_ NO_CC_MESS_EXT m65 : 8|16@1+ (1,0) [0|65534] ""  BCM,XGW_Body
 SG_ NO_CC_MESS_STD m64 : 8|16@1+ (1,0) [0|65534] ""  BCM,XGW_Body
 SG_ WACA m39 : 16|8@1+ (1,0) [0|0] ""  BCM,XGW_Body
 SG_ ID_RQ_BUS m12 : 24|8@1+ (1,0) [0|0] ""  BCM,XGW_Body
 SG_ ST_CC_MESS_EXT m65 : 24|2@1+ (1,0) [0|0] ""  BCM,XGW_Body
 SG_ ST_CC_MESS_STD m64 : 24|2@1+ (1,0) [0|0] ""  BCM,XGW_Body
 SG_ TRANF_CC_MESS_EXT m65 : 26|4@1+ (1,0) [0|14] ""  BCM,XGW_Body
 SG_ TRANF_CC_MESS_STD m64 : 26|4@1+ (1,0) [0|14] ""  BCM,XGW_Body
 SG_ ST_IDC_CCLK_CC_MESS_EXT m65 : 30|2@1+ (1,0) [0|0] ""  BCM,XGW_Body
 SG_ ST_IDC_CCLK_CC_MESS_STD m64 : 30|2@1+ (1,0) [0|0] ""  BCM,XGW_Body
 SG_ NO_FRM_CC_MESS_EXT m65 : 32|4@1+ (1,0) [0|14] ""  BCM,XGW_Body
 SG_ ST_RQ_BUS m12 : 32|4@1+ (1,0) [0|0] ""  BCM,XGW_Body
 SG_ QUAN_FRM_CC_MESS_EXT m65 : 36|4@1+ (1,0) [0|14] ""  BCM,XGW_Body
 SG_ ST_LAW_RQ m12 : 36|4@1+ (1,0) [0|0] ""  BCM,XGW_Body
 SG_ DUR_FLLUPT m12 : 40|8@1+ (1,0) [0|254] "min"  BCM,XGW_Body
 SG_ UTDT_CC_MESS m65 : 40|24@1+ (1,0) [0|0] ""  BCM,XGW_Body

BO_ 714 IC_SENSOR: 8 XGW_Body
 SG_ CHKSM_IC_SENSOR : 7|8@0+ (1,0) [0|255] ""  ACM,ADAS_Body,APM,ASU_Gateway,BCM,BCM_BPM,CCU_F,CCU_R,ETG,LDM_L,LDM_R,OCS_P,PSM_D,SHVU_F,SHVU_R,TRM
 SG_ ALV_IC_SENSOR : 11|4@0+ (1,0) [0|14] ""  ACM,ADAS_Body,APM,ASU_Gateway,BCM,BCM_BPM,CCU_F,CCU_R,ETG,LDM_L,LDM_R,OCS_P,PSM_D,SHVU_F,SHVU_R,TRM
 SG_ MHU_STAT_AmbientTempRaw : 23|8@0+ (0.5,-40) [-40|85] "°C"  ACM,ADAS_Body,APM,ASU_Gateway,BCM,BCM_BPM,CCU_F,CCU_R,ETG,LDM_L,LDM_R,OCS_P,PSM_D,SHVU_F,SHVU_R,TRM
 SG_ MHU_STAT_FuelLevel : 31|8@0+ (1,0) [0|100] "l"  ACM,ADAS_Body,APM,ASU_Gateway,BCM,BCM_BPM,CCU_F,CCU_R,ETG,LDM_L,LDM_R,OCS_P,PSM_D,SHVU_F,SHVU_R,TRM
 SG_ MHU_STAT_AmbientTemp : 39|8@0+ (0.5,-40) [-40|85] "Degree C"  ACM,ADAS_Body,APM,ASU_Gateway,BCM,BCM_BPM,CCU_F,CCU_R,ETG,LDM_L,LDM_R,OCS_P,PSM_D,SHVU_F,SHVU_R,TRM
 SG_ MHU_STAT_CoolantLevelStatus : 47|2@0+ (1,0) [0|3] "-"  ACM,ADAS_Body,APM,ASU_Gateway,BCM,BCM_BPM,CCU_F,CCU_R,ETG,LDM_L,LDM_R,OCS_P,PSM_D,SHVU_F,SHVU_R,TRM

BO_ 715 IC_TEMP: 8 BCM
 SG_ TEMP_EX : 7|8@0+ (0.5,-40) [-40|85] "°C"  DUMMY_ECU,XGW_Body
 SG_ TEMP_EX_UNFILT : 15|8@0+ (0.5,-40) [-40|85] "°C"  CCU_F,CCU_R,DUMMY_ECU,LDM_L,LDM_R,XGW_Body

BO_ 753 IC_STAT_AIRBAG: 1 XGW_Body
 SG_ MHU_STAT_AirbagWarnLamp : 1|2@0+ (1,0) [0|3] ""  ACM

BO_ 760 MHU_DATE_TIME: 8 XGW_Body
 SG_ DISP_HR : 7|8@0+ (1,0) [0|23] "h"  ACM,ADAS_Body,APM,ASU_Gateway,BCM,BCM_BPM,CCU_F,CCU_R,ETG,LDM_L,LDM_R,OCS_P,PSM_D,SHVU_F,SHVU_R,TRM
 SG_ DISP_MN : 15|8@0+ (1,0) [0|59] "min"  ACM,ADAS_Body,APM,ASU_Gateway,BCM,BCM_BPM,CCU_F,CCU_R,ETG,LDM_L,LDM_R,OCS_P,PSM_D,SHVU_F,SHVU_R,TRM
 SG_ DISP_SEC : 23|8@0+ (1,0) [0|59] "s"  ACM,ADAS_Body,APM,ASU_Gateway,BCM,BCM_BPM,CCU_F,CCU_R,ETG,LDM_L,LDM_R,OCS_P,PSM_D,SHVU_F,SHVU_R,TRM
 SG_ DISP_DATE_DAY : 31|8@0+ (1,0) [1|31] "Day"  ACM,ADAS_Body,APM,ASU_Gateway,BCM,BCM_BPM,CCU_F,CCU_R,ETG,LDM_L,LDM_R,OCS_P,PSM_D,SHVU_F,SHVU_R,TRM
 SG_ DISP_DATE_MON : 35|4@0+ (1,0) [1|12] "Month"  ACM,ADAS_Body,APM,ASU_Gateway,BCM,BCM_BPM,CCU_F,CCU_R,ETG,LDM_L,LDM_R,OCS_P,PSM_D,SHVU_F,SHVU_R,TRM
 SG_ DISP_DATE_WDAY : 39|4@0+ (1,0) [0|15] ""  ACM,ADAS_Body,APM,ASU_Gateway,BCM,BCM_BPM,CCU_F,CCU_R,ETG,LDM_L,LDM_R,OCS_P,PSM_D,SHVU_F,SHVU_R,TRM
 SG_ DISP_DATE_YR : 47|16@0+ (1,0) [1|65534] "Year"  ACM,ADAS_Body,APM,ASU_Gateway,BCM,BCM_BPM,CCU_F,CCU_R,ETG,LDM_L,LDM_R,OCS_P,PSM_D,SHVU_F,SHVU_R,TRM
 SG_ ST_DISP_CTI_DATE : 63|4@0+ (1,0) [0|15] ""  ACM,ADAS_Body,APM,ASU_Gateway,BCM,BCM_BPM,CCU_F,CCU_R,ETG,LDM_L,LDM_R,OCS_P,PSM_D,SHVU_F,SHVU_R,TRM

BO_ 768 CCU_STATUS: 8 CCU_F
 SG_ CCU_STAT_SyncClimateZone : 1|2@0+ (1,0) [0|3] ""  CCU_R,XGW_Body
 SG_ CCU_STAT_Auto : 3|2@0+ (1,0) [0|3] "-"  CCU_R,XGW_Body
 SG_ CCU_STAT_Aircondition : 5|2@0+ (1,0) [0|3] ""  CCU_R,XGW_Body
 SG_ CCU_STAT_IonButton : 7|2@0+ (1,0) [0|3] ""  CCU_R,XGW_Body
 SG_ CCU_STAT_MaxAc : 9|2@0+ (1,0) [0|3] ""  CCU_R,XGW_Body
 SG_ CCU_STAT_OnOff : 11|2@0+ (1,0) [0|3] "Bit"  CCU_R,XGW_Body
 SG_ CCU_STAT_FanSpeed : 15|4@0+ (1,0) [0|15] ""  CCU_R,XGW_Body
 SG_ CCU_STAT_RecircFlap : 23|2@0+ (1,0) [0|3] ""  CCU_R,XGW_Body
 SG_ CCU_STAT_FlapPos : 27|3@0+ (1,0) [0|7] ""  CCU_R,XGW_Body
 SG_ CCU_STAT_Defrost : 29|2@0+ (1,0) [0|3] "-"  CCU_R,XGW_Body
 SG_ CCU_STAT_PTC_Heater : 39|3@0+ (1,0) [0|7] "-"  CCU_R,XGW_Body
 SG_ CCU_STAT_TempDriver : 47|8@0+ (0.5,0) [16|32] "Degree C"  CCU_R,XGW_Body
 SG_ CCU_STAT_TempPassenger : 55|8@0+ (0.5,0) [16|32] "Degree C"  CCU_R,XGW_Body

BO_ 770 CCU_TEMP_PRESSURE: 6 CCU_F
 SG_ CHKSM_CCU_TEMP_PRESSURE : 7|8@0+ (1,0) [0|255] ""  XGW_Body
 SG_ ALV_CCU_TEMP_PRESSURE : 11|4@0+ (1,0) [0|14] ""  XGW_Body
 SG_ CCU_Pressure_AC : 23|6@0+ (1,0) [0|62] "bar"  XGW_Body
 SG_ CCU_InteriorTemp : 31|8@0+ (0.5,-40) [-40|85] "Degree C"  ACM,ADAS_Body,APM,ASU_Gateway,BCM,BCM_BPM,CCU_R,ETG,LDM_L,LDM_R,OCS_P,PSM_D,SHVU_F,SHVU_R,TRM,XGW_Body
 SG_ CCU_TempEx_AC : 39|8@0+ (0.5,-40) [-40|85] "Degree C"  ACM,ADAS_Body,APM,ASU_Gateway,BCM,BCM_BPM,CCU_R,ETG,LDM_L,LDM_R,OCS_P,PSM_D,SHVU_F,SHVU_R,TRM,XGW_Body
 SG_ CCU_EvaporatorTemp : 47|8@0+ (0.5,-40) [-40|85] "Degree C"  XGW_Body

BO_ 773 VCU_HeatCoolStat: 8 XGW_Body
 SG_ HtrMediumOutletTemp : 7|9@0+ (0.5,-40) [-40|200] "°C"  CCU_F,CCU_R
 SG_ CcuHtrOnOffSts : 12|3@0+ (1,0) [0|7] ""  CCU_F,CCU_R
 SG_ EcompOnOffSts : 14|2@0+ (1,0) [0|3] ""  CCU_F,CCU_R
 SG_ HtrMediumInletTemp : 23|9@0+ (0.5,-40) [-40|200] "Degree C"  CCU_F,CCU_R
 SG_ ECompRpm : 39|16@0+ (1,0) [0|12000] "1/min"  CCU_F,CCU_R
 SG_ ECompPowerConsumption : 55|8@0+ (0.1,0) [0|12] "kW"  CCU_F,CCU_R

BO_ 774 CCU_HeatCoolReq: 7 CCU_F
 SG_ CCU_EcompOnOffRequest : 1|2@0+ (1,0) [0|3] ""  XGW_Body
 SG_ CCU_HtrOnOffRequest : 3|2@0+ (1,0) [0|3] ""  XGW_Body
 SG_ CCU_AcOffCode_CCU : 15|8@0+ (1,0) [0|255] ""  XGW_Body
 SG_ CCU_CoolPowerDemand : 23|8@0+ (0.1,0) [0|10] "kW"  XGW_Body
 SG_ CCU_HeatPowerDemand : 31|8@0+ (0.1,0) [0|10] "kW"  XGW_Body
 SG_ CCU_PTCOffCode_CCU : 39|8@0+ (1,0) [0|255] ""  XGW_Body
 SG_ CCU_CoolDemand : 47|8@0+ (0.5,0) [0|100] "%"  XGW_Body
 SG_ CCU_HeatDemand : 55|8@0+ (0.5,0) [0|100] "%"  XGW_Body

BO_ 775 CPD_OUTPUT: 3 XGW_Body
 SG_ CHKSM_CPD_Output_1 : 7|8@0+ (1,0) [0|255] ""  BCM
 SG_ ALV_CPD_Output_1 : 11|4@0+ (1,0) [0|14] ""  BCM
 SG_ OUT_Alert_TO_BCM : 14|3@0+ (1,0) [0|7] "-"  BCM,CCU_F,CCU_R
 SG_ CPD_State_information : 20|3@0+ (1,0) [0|7] "-"  BCM

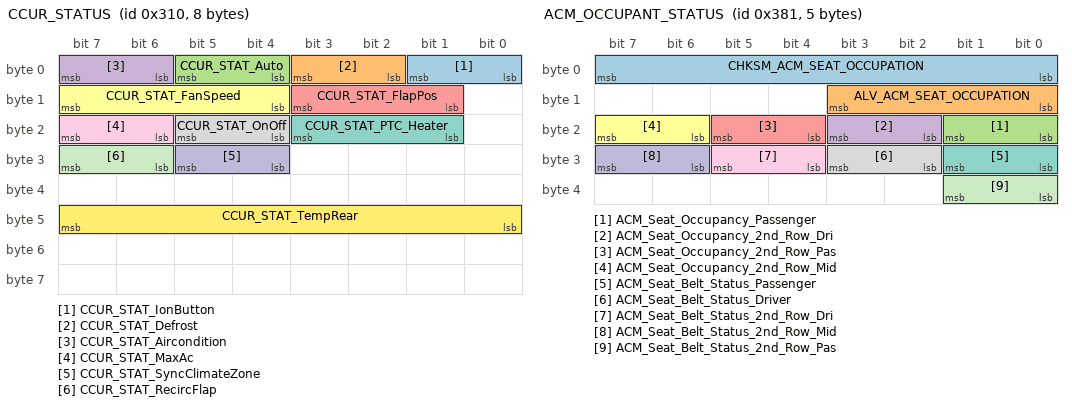
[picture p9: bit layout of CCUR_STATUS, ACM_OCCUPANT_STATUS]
BO_ 784 CCUR_STATUS: 8 CCU_F
 SG_ CCUR_STAT_IonButton : 1|2@0+ (1,0) [0|3] "-"  XGW_Body
 SG_ CCUR_STAT_Defrost : 3|2@0+ (1,0) [0|3] ""  XGW_Body
 SG_ CCUR_STAT_Auto : 5|2@0+ (1,0) [0|3] ""  XGW_Body
 SG_ CCUR_STAT_Aircondition : 7|2@0+ (1,0) [0|3] "-"  XGW_Body
 SG_ CCUR_STAT_FlapPos : 11|3@0+ (1,0) [0|7] "-"  XGW_Body
 SG_ CCUR_STAT_FanSpeed : 15|4@0+ (1,0) [0|15] "-"  XGW_Body
 SG_ CCUR_STAT_PTC_Heater : 19|3@0+ (1,0) [0|7] ""  XGW_Body
 SG_ CCUR_STAT_OnOff : 21|2@0+ (1,0) [0|3] "Bit"  XGW_Body
 SG_ CCUR_STAT_MaxAc : 23|2@0+ (1,0) [0|3] ""  XGW_Body
 SG_ CCUR_STAT_SyncClimateZone : 29|2@0+ (1,0) [0|3] "-"  XGW_Body
 SG_ CCUR_STAT_RecircFlap : 31|2@0+ (1,0) [0|3] "-"  XGW_Body
 SG_ CCUR_STAT_TempRear : 47|8@0+ (0.5,0) [16|32] "Degree C"  XGW_Body

BO_ 808 IC_RELATIVTIME: 8 BCM
 SG_ T_SEC_COU_REL : 0|32@1+ (1,0) [0|4294967294] "s"  ASU_Gateway
 SG_ T_DAY_COU_ABSL : 32|16@1+ (1,0) [0|65534] "Day"  ADAS_Body,DUMMY_ECU

BO_ 806 POD_StatusDCDC1: 8 XGW_Body
  SG_ CHSKM_POD_StatusDCDC1 : 7|8@0+ (1,0) [0|255] "" BCM
  SG_ ALV_POD_StatusDCDC1 : 11|4@0+ (1,0) [0|14] "" BCM
  SG_ POD_statusDCDC : 14|3@0+ (1,0) [0|7] "" BCM

BO_ 809 BCM_ODO: 8 BCM
 SG_ CRC_BCM_ODO : 7|8@0+ (1,0) [0|255] ""  XGW_Body
 SG_ ALIV_BCM_ODO : 11|4@0+ (1,0) [0|14] ""  XGW_Body
 SG_ Odometer_BCM : 23|20@0+ (1,0) [0|999999] "km"  XGW_Body
 SG_ SECCAN_BCM_ODO : 63|8@0+ (1,0) [0|255] ""  XGW_Body

BO_ 812 ASU_HEIGHT_LEVEL: 8 ASU_Gateway
 SG_ CRC_HGLV_EHC : 0|8@1+ (1,0) [0|255] ""  BCM,DUMMY_ECU
 SG_ ALIV_HGLV_EHC : 8|4@1+ (1,0) [0|14] ""  BCM,DUMMY_ECU
 SG_ HGLV_RLH_EHC : 16|8@1+ (1,-127) [-127|127] "mm"  BCM,DUMMY_ECU
 SG_ HGLV_RRH_EHC : 24|8@1+ (1,-127) [-127|127] "mm"  BCM,DUMMY_ECU
 SG_ QU_HGLV_RLH_EHC : 32|4@1+ (1,0) [0|15] ""  BCM,DUMMY_ECU
 SG_ QU_HGLV_RRH_EHC : 36|4@1+ (1,0) [0|15] ""  BCM,DUMMY_ECU

BO_ 816 IC_MILEAGE: 8 BCM
 SG_ MILE_KM : 7|24@0+ (1,0) [0|999999] "km"  ACM,ADAS_Body,APM,ASU_Gateway,BCM_BPM,CCU_F,CCU_R,DUMMY_ECU,ETG,LDM_L,LDM_R,OCS_P,PSM_D,SHVU_F,SHVU_R,TRM,XGW_Body
 SG_ FLLV_FUTA : 31|8@0+ (1,0) [0|254] "l"  ACM,ADAS_Body,APM,ASU_Gateway,BCM_BPM,CCU_F,CCU_R,DUMMY_ECU,ETG,LDM_L,LDM_R,OCS_P,PSM_D,SHVU_F,SHVU_R,TRM,XGW_Body
 SG_ RNG : 51|12@0+ (1,0) [0|4094] "km"  ACM,ADAS_Body,APM,ASU_Gateway,BCM_BPM,CCU_F,CCU_R,DUMMY_ECU,ETG,LDM_L,LDM_R,OCS_P,PSM_D,SHVU_F,SHVU_R,TRM,XGW_Body
 SG_ ST_FLLV_FUTA_SPAR : 55|2@0+ (1,0) [0|3] ""  ACM,ADAS_Body,APM,ASU_Gateway,BCM_BPM,CCU_F,CCU_R,DUMMY_ECU,ETG,LDM_L,LDM_R,OCS_P,PSM_D,SHVU_F,SHVU_R,TRM,XGW_Body

BO_ 880 MHU_SBR_Status: 8 XGW_Body
 SG_ CRC_MHU_SBR_Status : 7|8@0+ (1,0) [0|255] ""  ACM
 SG_ ALV_MHU_SBR_Status : 11|4@0+ (1,0) [0|14] ""  ACM
 SG_ SBR_STAT_Chime : 13|2@0+ (1,0) [0|3] ""  ACM
 SG_ SBR_STAT_Telltale : 15|2@0+ (1,0) [0|3] ""  ACM
 SG_ SBR_STAT_Active : 16|1@0+ (1,0) [0|1] ""  ACM

BO_ 896 BCM_VEHICLE_IDENT_NUMBER: 8 BCM
 SG_ VIN_Byte1 : 7|8@0+ (1,0) [0|255] ""  ACM,ADAS_Body,APM,ASU_Gateway,BCM_BPM,CCU_F,CCU_R,ETG,LDM_L,LDM_R,OCS_P,PSM_D,SHVU_F,SHVU_R,TRM,XGW_Body
 SG_ VIN_Byte2 : 15|8@0+ (1,0) [0|255] ""  ACM,ADAS_Body,APM,ASU_Gateway,BCM_BPM,CCU_F,CCU_R,ETG,LDM_L,LDM_R,OCS_P,PSM_D,SHVU_F,SHVU_R,TRM,XGW_Body
 SG_ VIN_Byte3 : 23|8@0+ (1,0) [0|255] ""  ACM,ADAS_Body,APM,ASU_Gateway,BCM_BPM,CCU_F,CCU_R,ETG,LDM_L,LDM_R,OCS_P,PSM_D,SHVU_F,SHVU_R,TRM,XGW_Body
 SG_ VIN_Byte4 : 31|8@0+ (1,0) [0|255] ""  ACM,ADAS_Body,APM,ASU_Gateway,BCM_BPM,CCU_F,CCU_R,ETG,LDM_L,LDM_R,OCS_P,PSM_D,SHVU_F,SHVU_R,TRM,XGW_Body
 SG_ VIN_Byte5 : 39|8@0+ (1,0) [0|255] ""  ACM,ADAS_Body,APM,ASU_Gateway,BCM_BPM,CCU_F,CCU_R,ETG,LDM_L,LDM_R,OCS_P,PSM_D,SHVU_F,SHVU_R,TRM,XGW_Body
 SG_ VIN_Byte6 : 47|8@0+ (1,0) [0|255] ""  ACM,ADAS_Body,APM,ASU_Gateway,BCM_BPM,CCU_F,CCU_R,ETG,LDM_L,LDM_R,OCS_P,PSM_D,SHVU_F,SHVU_R,TRM,XGW_Body
 SG_ VIN_Byte7 : 55|8@0+ (1,0) [0|255] ""  ACM,ADAS_Body,APM,ASU_Gateway,BCM_BPM,CCU_F,CCU_R,ETG,LDM_L,LDM_R,OCS_P,PSM_D,SHVU_F,SHVU_R,TRM,XGW_Body

BO_ 897 ACM_OCCUPANT_STATUS: 5 ACM
 SG_ CHKSM_ACM_SEAT_OCCUPATION : 7|8@0+ (1,0) [0|255] ""  ADAS_Body,XGW_Body,CCU_F
 SG_ ALV_ACM_SEAT_OCCUPATION : 11|4@0+ (1,0) [0|14] ""  ADAS_Body,XGW_Body,CCU_F
 SG_ ACM_Seat_Occupancy_Passenger : 17|2@0+ (1,0) [0|3] ""  BCM,XGW_Body,CCU_F
 SG_ ACM_Seat_Occupancy_2nd_Row_Dri : 19|2@0+ (1,0) [0|3] ""  BCM,XGW_Body,CCU_F
 SG_ ACM_Seat_Occupancy_2nd_Row_Pas : 21|2@0+ (1,0) [0|3] "-"  BCM,XGW_Body,CCU_F
 SG_ ACM_Seat_Occupancy_2nd_Row_Mid : 23|2@0+ (1,0) [0|3] "-"  BCM,XGW_Body,CCU_F
 SG_ ACM_Seat_Belt_Status_Passenger : 25|2@0+ (1,0) [0|3] ""  XGW_Body,CCU_F
 SG_ ACM_Seat_Belt_Status_Driver : 27|2@0+ (1,0) [0|3] ""  ADAS_Body,BCM,XGW_Body,CCU_F
 SG_ ACM_Seat_Belt_Status_2nd_Row_Dri : 29|2@0+ (1,0) [0|3] "-"  XGW_Body,CCU_F
 SG_ ACM_Seat_Belt_Status_2nd_Row_Mid : 31|2@0+ (1,0) [0|3] ""  XGW_Body,CCU_F
 SG_ ACM_Seat_Belt_Status_2nd_Row_Pas : 33|2@0+ (1,0) [0|3] "-"  XGW_Body,CCU_F

BO_ 905 VCU_Sts3: 8 XGW_Body
 SG_ VCU_IMMO_Sts : 35|2@0+ (1,0) [0|3] ""  BCM
 SG_ SECCAN_VCU_IMMO_Sts : 63|8@0+ (1,0) [0|255] ""  BCM

BO_ 920 BCM_Auth_Immo: 8 BCM
 SG_ BCM_Immo_Byte_0 : 7|8@0+ (1,0) [0|255] ""  XGW_Body
 SG_ BCM_Immo_Byte_1 : 15|8@0+ (1,0) [0|255] ""  XGW_Body
 SG_ BCM_Immo_Byte_2 : 23|8@0+ (1,0) [0|255] ""  XGW_Body
 SG_ BCM_Immo_Byte_3 : 31|8@0+ (1,0) [0|255] ""  XGW_Body
 SG_ BCM_Immo_Byte_4 : 39|8@0+ (1,0) [0|255] ""  XGW_Body
 SG_ BCM_Immo_Byte_5 : 47|8@0+ (1,0) [0|255] ""  XGW_Body
 SG_ BCM_Immo_Byte_6 : 55|8@0+ (1,0) [0|255] ""  XGW_Body
 SG_ BCM_Immo_Byte_7 : 63|8@0+ (1,0) [0|255] ""  XGW_Body

BO_ 921 VCU_Auth_Immo: 8 XGW_Body
 SG_ VCU_Immo_Byte_0 : 7|8@0+ (1,0) [0|255] ""  BCM
 SG_ VCU_Immo_Byte_1 : 15|8@0+ (1,0) [0|255] ""  BCM
 SG_ VCU_Immo_Byte_2 : 23|8@0+ (1,0) [0|255] ""  BCM
 SG_ VCU_Immo_Byte_3 : 31|8@0+ (1,0) [0|255] ""  BCM
 SG_ VCU_Immo_Byte_4 : 39|8@0+ (1,0) [0|255] ""  BCM
 SG_ VCU_Immo_Byte_5 : 47|8@0+ (1,0) [0|255] ""  BCM
 SG_ VCU_Immo_Byte_6 : 55|8@0+ (1,0) [0|255] ""  BCM
 SG_ VCU_Immo_Byte_7 : 63|8@0+ (1,0) [0|255] ""  BCM

BO_ 922 MHU_Auth_Immo: 8 XGW_Body
 SG_ MHU_Immo_Byte_0 : 7|8@0+ (1,0) [0|255] "-"  ADAS_Body,BCM
 SG_ MHU_Immo_Byte_1 : 15|8@0+ (1,0) [0|255] "-"  BCM
 SG_ MHU_Immo_Byte_2 : 23|8@0+ (1,0) [0|255] ""  BCM
 SG_ MHU_Immo_Byte_3 : 31|8@0+ (1,0) [0|255] ""  BCM
 SG_ MHU_Immo_Byte_4 : 39|8@0+ (1,0) [0|255] ""  BCM
 SG_ MHU_Immo_Byte_5 : 47|8@0+ (1,0) [0|255] ""  BCM
 SG_ MHU_Immo_Byte_6 : 55|8@0+ (1,0) [0|255] ""  BCM
 SG_ MHU_Immo_Byte_7 : 63|8@0+ (1,0) [0|255] "-"  BCM

BO_ 923 BCM_Immo_MHU_Byte_0: 8 BCM
 SG_ BCM_Immo_MHU_Byte_0 : 7|8@0+ (1,0) [0|255] "-"  XGW_Body
 SG_ BCM_Immo_MHU_Byte_1 : 15|8@0+ (1,0) [0|255] "-"  XGW_Body
 SG_ BCM_Immo_MHU_Byte_2 : 23|8@0+ (1,0) [0|255] "-"  XGW_Body
 SG_ BCM_Immo_MHU_Byte_3 : 31|8@0+ (1,0) [0|255] "-"  XGW_Body
 SG_ BCM_Immo_MHU_Byte_4 : 39|8@0+ (1,0) [0|255] "-"  XGW_Body
 SG_ BCM_Immo_MHU_Byte_5 : 47|8@0+ (1,0) [0|255] ""  XGW_Body
 SG_ BCM_Immo_MHU_Byte_6 : 55|8@0+ (1,0) [0|255] "-"  XGW_Body
 SG_ BCM_Immo_MHU_Byte_7 : 63|8@0+ (1,0) [0|255] "-"  XGW_Body

BO_ 924 ADAS_Request_BODY: 4 ADAS_Body
 SG_ ADAS_Body_Checksum : 7|8@0+ (1,0) [0|255] ""  BCM
 SG_ ADAS_Body_Alive : 11|4@0+ (1,0) [0|14] ""  BCM
 SG_ SECCAN_Request_BODY : 23|8@0+ (1,0) [0|255] ""  BCM
 SG_ ADAS_AHB_LBPos : 28|3@0+ (1,0) [0|7] "-"  BCM
 SG_ ADAS_AHB_RBPos : 31|3@0+ (1,0) [0|7] ""  BCM

BO_ 925 BCM_HighBeam_PosReq: 4 BCM
 SG_ BCM_AHB_Override : 17|2@0+ (1,0) [0|3] ""  ADAS_Body,LDM_L,LDM_R,XGW_Body
 SG_ BCM_ADAS_AHB_RBPos_feed : 20|3@0+ (1,0) [0|7] ""  ADAS_Body
 SG_ BCM_ADAS_AHB_LBPos_feed : 23|3@0+ (1,0) [0|7] ""  ADAS_Body
 SG_ SECCAN_BCM_AHB_L : 31|8@0+ (1,0) [0|255] ""  ADAS_Body

BO_ 926 ADAS_AMB: 8 ADAS_Body
 SG_ Checksum_AMB : 7|8@0+ (1,0) [0|255] ""  BCM
 SG_ ALV_Counter_AMB : 11|4@0+ (1,0) [0|14] ""  BCM
 SG_ SECCAN_ADAS_AMB : 55|8@0+ (1,0) [0|255] ""  BCM
 SG_ ADAS_DOW_LockReqRight : 56|1@0+ (1,0) [0|1] ""  BCM
 SG_ ADAS_DOW_LockReqLeft : 57|1@0+ (1,0) [0|1] ""  BCM
 SG_ ADAS_AmbLightLeft : 59|2@0+ (1,0) [0|3] ""  BCM
 SG_ ADAS_AmbLightRight : 61|2@0+ (1,0) [0|3] ""  BCM

BO_ 1015 MFS_Control_Button: 8 XGW_Body
 SG_ CHSKM_MFS_Control_Button : 7|8@0+ (1,0) [0|255] ""  BCM
 SG_ ALV_MFS_Control_Button : 11|4@0+ (1,0) [0|14] ""  BCM
 SG_ MFS_VoiceRecognitionOn_Off : 15|3@0+ (1,0) [0|4] "Bit"  BCM
 SG_ MFS_ISAControl : 17|2@0+ (1,0) [0|3] "Bit"  BCM
 SG_ MFS_CruiseSpeedIncrease : 20|3@0+ (1,0) [0|4] "Bit"  BCM
 SG_ MFS_TelephoneCall_EndCall : 23|3@0+ (1,0) [0|4] "Bit"  BCM
 SG_ MFS_LKAControl : 25|2@0+ (1,0) [0|3] "Bit"  BCM
 SG_ MFS_CruiseGapIncrease : 28|3@0+ (1,0) [0|4] "Bit"  BCM
 SG_ MFS_CruiseOn_Off : 31|3@0+ (1,0) [0|4] "Bit"  BCM
 SG_ MFS_CruiseGapDecrease : 34|3@0+ (1,0) [0|4] "Bit"  BCM
 SG_ MFS_CAN_RESControl : 36|2@0+ (1,0) [0|3] "-"  BCM
 SG_ MFS_CruiseSpeedDecrease : 39|3@0+ (1,0) [0|4] "Bit"  BCM
 SG_ MFS_M2Control : 41|2@0+ (1,0) [0|3] "Bit"  BCM
 SG_ MFS_SourseControl : 44|3@0+ (1,0) [0|4] "Bit"  BCM
 SG_ MFS_UpControl : 47|3@0+ (1,0) [0|4] "Bit"  BCM
 SG_ MFS_DownControl : 52|3@0+ (1,0) [0|4] "Bit"  BCM
 SG_ MFS_LeftControl : 55|3@0+ (1,0) [0|4] "Bit"  BCM
 SG_ MFS_Failure : 57|1@0+ (1,0) [0|1] "Bit"  BCM
 SG_ MFS_RightControl : 60|3@0+ (1,0) [0|4] "Bit"  BCM
 SG_ MFS_OK_Control : 63|3@0+ (1,0) [0|4] "Bit"  BCM

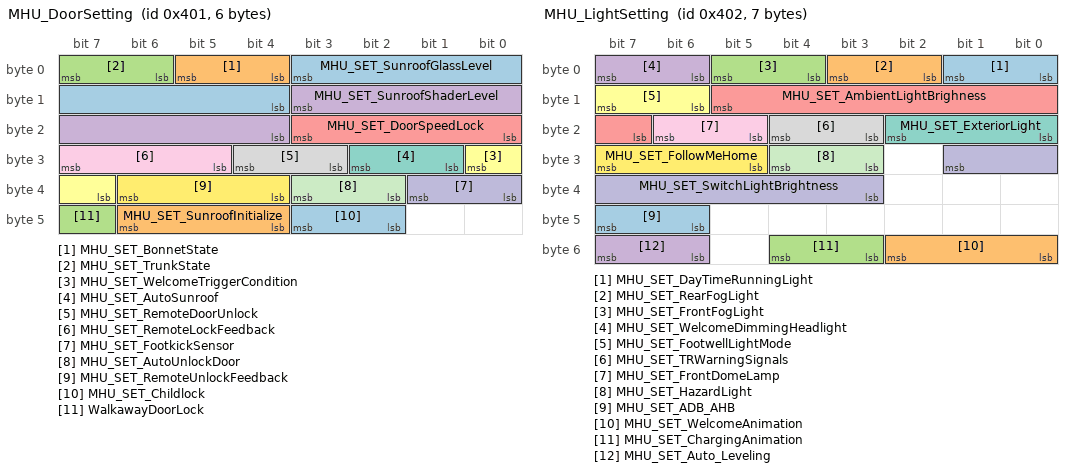
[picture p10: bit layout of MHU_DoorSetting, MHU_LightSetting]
BO_ 1025 MHU_DoorSetting: 6 XGW_Body
 SG_ MHU_SET_SunroofGlassLevel : 3|8@0+ (1,0) [0|255] "%"  BCM
 SG_ MHU_SET_BonnetState : 5|2@0+ (1,0) [0|3] "-"  BCM
 SG_ MHU_SET_TrunkState : 7|2@0+ (1,0) [0|3] "-"  BCM
 SG_ MHU_SET_SunroofShaderLevel : 11|8@0+ (1,0) [0|255] "%"  BCM
 SG_ MHU_SET_DoorSpeedLock : 19|4@0+ (1,0) [0|7] ""  BCM
 SG_ MHU_SET_WelcomeTriggerCondition : 24|2@0+ (1,0) [0|3] ""  BCM
 SG_ MHU_SET_AutoSunroof : 26|2@0+ (1,0) [0|3] ""  BCM
 SG_ MHU_SET_RemoteDoorUnlock : 28|2@0+ (1,0) [0|3] "-"  BCM
 SG_ MHU_SET_RemoteLockFeedback : 31|3@0+ (1,0) [0|7] "-"  BCM
 SG_ MHU_SET_FootkickSensor : 33|2@0+ (1,0) [0|3] "-"  BCM
 SG_ MHU_SET_AutoUnlockDoor : 35|2@0+ (1,0) [0|3] ""  BCM
 SG_ MHU_SET_RemoteUnlockFeedback : 38|3@0+ (1,0) [0|7] ""  BCM
 SG_ MHU_SET_Childlock : 43|2@0+ (1,0) [0|3] ""  BCM
 SG_ MHU_SET_SunroofInitialize : 46|3@0+ (1,0) [0|7] ""  BCM
 SG_ WalkawayDoorLock : 47|1@0+ (1,0) [0|1] "" BCM

BO_ 1026 MHU_LightSetting: 7 XGW_Body
 SG_ MHU_SET_DayTimeRunningLight : 1|2@0+ (1,0) [0|3] "-"  BCM,LDM_L,LDM_R
 SG_ MHU_SET_RearFogLight : 3|2@0+ (1,0) [0|3] ""  BCM,LDM_L,LDM_R
 SG_ MHU_SET_FrontFogLight : 5|2@0+ (1,0) [0|3] ""  BCM,LDM_L,LDM_R
 SG_ MHU_SET_WelcomeDimmingHeadlight : 7|2@0+ (1,0) [0|3] ""  BCM,LDM_L,LDM_R
 SG_ MHU_SET_AmbientLightBrighness : 13|7@0+ (1,0) [0|100] "%"  BCM,LDM_L,LDM_R
 SG_ MHU_SET_FootwellLightMode : 15|2@0+ (1,0) [0|3] "-"  BCM,LDM_L,LDM_R
 SG_ MHU_SET_ExteriorLight : 18|3@0+ (1,0) [0|7] ""  BCM,LDM_L,LDM_R
 SG_ MHU_SET_TRWarningSignals : 20|2@0+ (1,0) [0|3] "" BCM
 SG_ MHU_SET_FrontDomeLamp : 22|2@0+ (1,0) [0|3] ""  BCM,LDM_L,LDM_R
 SG_ MHU_SET_SwitchLightBrightness : 25|7@0+ (1,0) [0|100] "%"  BCM,LDM_L,LDM_R
 SG_ MHU_SET_HazardLight : 28|2@0+ (1,0) [0|3] ""  BCM
 SG_ MHU_SET_FollowMeHome : 31|3@0+ (1,0) [0|7] ""  BCM,LDM_L,LDM_R
 SG_ MHU_SET_ADB_AHB : 47|2@0+ (1,0) [0|3] ""  BCM,LDM_L
 SG_ MHU_SET_WelcomeAnimation : 50|3@0+ (1,0) [0|5] ""  BCM
 SG_ MHU_SET_ChargingAnimation : 52|2@0+ (1,0) [0|3] ""  BCM
 SG_ MHU_SET_Auto_Leveling : 55|2@0+ (1,0) [0|3] "-"  BCM,LDM_L

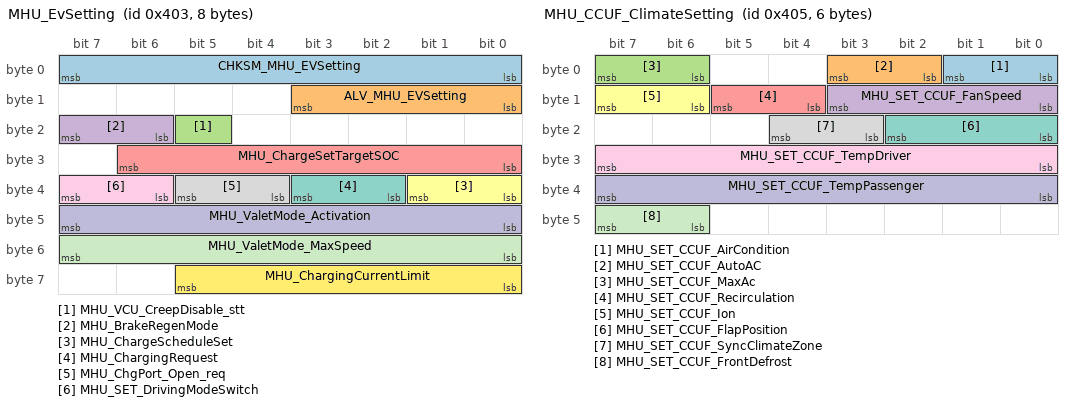
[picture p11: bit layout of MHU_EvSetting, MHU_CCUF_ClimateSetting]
BO_ 1027 MHU_EvSetting: 8 XGW_Body
 SG_ CHKSM_MHU_EVSetting : 7|8@0+ (1,0) [0|255] ""  BCM
 SG_ ALV_MHU_EVSetting : 11|4@0+ (1,0) [0|14] ""  BCM
 SG_ MHU_VCU_CreepDisable_stt : 21|1@0+ (1,0) [0|1] ""  BCM
 SG_ MHU_BrakeRegenMode : 23|2@0+ (1,0) [0|3] ""  DUMMY_ECU
 SG_ MHU_ChargeSetTargetSOC : 30|7@0+ (1,0) [10|100] "%"  DUMMY_ECU
 SG_ MHU_ChargeScheduleSet : 33|2@0+ (1,0) [0|3] ""  DUMMY_ECU
 SG_ MHU_ChargingRequest : 35|2@0+ (1,0) [0|3] "-"  BCM,DUMMY_ECU
 SG_ MHU_ChgPort_Open_req : 37|2@0+ (1,0) [0|3] "-"  BCM
 SG_ MHU_SET_DrivingModeSwitch : 39|2@0+ (1,0) [0|3] "-"  BCM
 SG_ MHU_ValetMode_Activation : 47|8@0+ (1,0) [0|255] ""  DUMMY_ECU
 SG_ MHU_ValetMode_MaxSpeed : 55|8@0+ (1,0) [0|255] "km/h"  DUMMY_ECU
 SG_ MHU_ChargingCurrentLimit : 61|6@0+ (1,0) [0|63] "A"  BCM

BO_ 1028 MHU_MirrorAdjust: 8 XGW_Body
 SG_ MHU_SET_LeftMirrorPosX : 7|8@0+ (1,-15) [-15|15] "deg"  BCM
 SG_ MHU_SET_LeftMirrorPosY : 15|8@0+ (1,-15) [-15|15] "deg"  BCM
 SG_ MHU_SET_RightMirrorPosX : 23|8@0+ (1,-15) [-15|15] "deg"  BCM
 SG_ MHU_SET_RightMirrorPosY : 31|8@0+ (1,-15) [-15|15] "deg"  BCM
 SG_ MHU_SET_MirrorAdjustLeft : 39|2@0+ (1,0) [0|3] "-"  BCM
 SG_ MHU_SET_MirrorAdjustRight : 41|2@0+ (1,0) [0|3] "-"  BCM
 SG_ MHU_SET_MirrorManual : 43|2@0+ (1,0) [0|3] ""  BCM
 SG_ SECCAN_MirrorAdj : 63|8@0+ (1,0) [0|255] ""  BCM

BO_ 1029 MHU_CCUF_ClimateSetting: 6 XGW_Body
 SG_ MHU_SET_CCUF_AirCondition : 1|2@0+ (1,0) [0|3] ""  CCU_F
 SG_ MHU_SET_CCUF_AutoAC : 3|2@0+ (1,0) [0|3] ""  CCU_F
 SG_ MHU_SET_CCUF_MaxAc : 7|2@0+ (1,0) [0|3] ""  CCU_F
 SG_ MHU_SET_CCUF_FanSpeed : 11|4@0+ (1,0) [0|7] "-"  CCU_F
 SG_ MHU_SET_CCUF_Recirculation : 13|2@0+ (1,0) [0|3] ""  CCU_F
 SG_ MHU_SET_CCUF_Ion : 15|2@0+ (1,0) [0|3] "-"  CCU_F
 SG_ MHU_SET_CCUF_FlapPosition : 18|3@0+ (1,0) [0|7] "-"  CCU_F
 SG_ MHU_SET_CCUF_SyncClimateZone : 20|2@0+ (1,0) [0|3] "-"  CCU_F
 SG_ MHU_SET_CCUF_TempDriver : 31|8@0+ (0.5,0) [16|32] "Degree C"  CCU_F
 SG_ MHU_SET_CCUF_TempPassenger : 39|8@0+ (0.5,0) [16|32] "Degree C"  CCU_F
 SG_ MHU_SET_CCUF_FrontDefrost : 47|2@0+ (1,0) [0|3] ""  CCU_F

BO_ 1030 MHU_SeatVentHeat: 4 XGW_Body
 SG_ MHU_SET_SeatHeatingFrontL : 2|3@0+ (1,0) [0|7] "-"  SHVU_F
 SG_ MHU_SET_SeatHeatingFrontR : 5|3@0+ (1,0) [0|7] "-"  SHVU_F
 SG_ MHU_SET_SeatHeatingReartL : 10|3@0+ (1,0) [0|7] "-"  SHVU_R
 SG_ MHU_SET_SeatHeatingRearR : 13|3@0+ (1,0) [0|7] "-"  SHVU_R
 SG_ MHU_SET_SeatCoolingFrontL : 18|3@0+ (1,0) [0|7] "-"  SHVU_F
 SG_ MHU_SET_SeatCoolingFrontR : 21|3@0+ (1,0) [0|7] ""  SHVU_F
 SG_ MHU_SET_SeatCoolingRearL : 26|3@0+ (1,0) [0|7] ""  SHVU_R
 SG_ MHU_SET_SeatCoolingRearR : 29|3@0+ (1,0) [0|7] "-"  SHVU_R

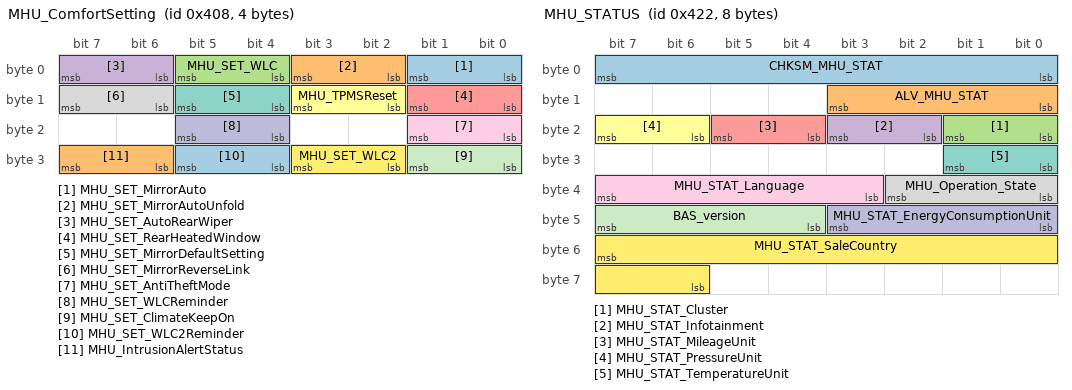
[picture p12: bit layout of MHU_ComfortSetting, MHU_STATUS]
BO_ 1032 MHU_ComfortSetting: 4 XGW_Body
 SG_ MHU_SET_MirrorAuto : 1|2@0+ (1,0) [0|3] ""  BCM
 SG_ MHU_SET_MirrorAutoUnfold : 3|2@0+ (1,0) [0|3] ""  BCM
 SG_ MHU_SET_WLC : 5|2@0+ (1,0) [0|3] "-"  BCM
 SG_ MHU_SET_AutoRearWiper : 7|2@0+ (1,0) [0|3] "-"  BCM
 SG_ MHU_SET_RearHeatedWindow : 9|2@0+ (1,0) [0|3] ""  BCM
 SG_ MHU_TPMSReset : 11|2@0+ (1,0) [0|3] ""  BCM
 SG_ MHU_SET_MirrorDefaultSetting : 13|2@0+ (1,0) [0|3] ""  BCM
 SG_ MHU_SET_MirrorReverseLink : 15|2@0+ (1,0) [0|3] "-"  BCM
 SG_ MHU_SET_AntiTheftMode : 17|2@0+ (1,0) [0|3] ""  BCM
 SG_ MHU_SET_WLCReminder : 21|2@0+ (1,0) [0|3] ""  BCM
 SG_ MHU_SET_ClimateKeepOn : 25|2@0+ (1,0) [0|3] ""  BCM
 SG_ MHU_SET_WLC2 : 27|2@0+ (1,0) [0|3] "-"  BCM
 SG_ MHU_SET_WLC2Reminder : 29|2@0+ (1,0) [0|3] "-"  BCM
 SG_ MHU_IntrusionAlertStatus : 31|2@0+ (1,0) [0|3] "-"  BCM

BO_ 1036 MHU_SEAT_CONTROL: 8 XGW_Body
 SG_ CHSKM_MHU_SEAT_CONTROL : 7|8@0+ (1,0) [0|255] ""  PSM_D
 SG_ ALV_MHU_SEAT_CONTROL : 11|4@0+ (1,0) [0|14] ""  PSM_D
 SG_ MHU_DrvSeat_Control_Status : 15|3@0+ (1,0) [0|7] "-"  PSM_D
 SG_ MHU_ExpDrvReclinerPos : 23|7@0+ (1,0) [0|127] "degree"  PSM_D
 SG_ MHU_ExpDrvTiltPos : 31|5@0+ (1,0) [0|31] "mm"  PSM_D
 SG_ MHU_ExpDrvTrackPos : 39|8@0+ (1,0) [0|255] "mm"  PSM_D
 SG_ MHU_ExpDrvHeightPos : 47|6@0+ (1,0) [0|63] "mm"  PSM_D

BO_ 1037 MHU_DIGIT_SPEED: 5 XGW_Body
 SG_ CHKSM_MHU_DIGIT_SPEED : 7|8@0+ (1,0) [0|255] ""  ACM
 SG_ ALV_MHU_DIGIT_SPEED : 11|4@0+ (1,0) [0|14] ""  ACM
 SG_ MHU_DigitSpeed : 23|9@0+ (1,0) [0|300] "km/h"  ACM

BO_ 1044 HOD_Status: 8 XGW_Body
 SG_ CRC_SW_1 : 7|8@0+ (1,0) [0|255] ""  ADAS_Body
 SG_ Message_Counter_SW_1 : 11|4@0+ (1,0) [0|14] ""  ADAS_Body
 SG_ Calc_Threshold : 23|8@0+ (1,0) [0|255] ""  ADAS_Body
 SG_ Real_Impedence : 31|8@0+ (1,0) [0|255] ""  ADAS_Body
 SG_ Immag_Impedence : 39|8@0+ (1,0) [0|255] ""  ADAS_Body
 SG_ ERR_ST_HOD : 43|4@0+ (1,0) [0|15] ""  ADAS_Body
 SG_ RsErr_HOD : 44|1@0+ (1,0) [0|1] ""  ADAS_Body
 SG_ HOD_status : 59|4@0+ (1,0) [0|15] ""  ADAS_Body

BO_ 1046 BCM_Mirror_Confirm_sts: 8 BCM
 SG_ BCM_STAT_LeftMirrorPosX : 7|8@0+ (1,-15) [-15|15] "deg"  ADAS_Body,XGW_Body
 SG_ BCM_STAT_LeftMirrorPosY : 15|8@0+ (1,-15) [-15|15] "deg"  ADAS_Body,XGW_Body
 SG_ BCM_STAT_RightMirrorPosX : 23|8@0+ (1,-15) [-15|15] "deg"  ADAS_Body,XGW_Body
 SG_ BCM_STAT_RightMirrorPosY : 31|8@0+ (1,-15) [-15|15] "deg"  ADAS_Body,XGW_Body
 SG_ BCM_STAT_Mirror : 37|2@0+ (1,0) [0|3] ""  ADAS_Body,XGW_Body
 SG_ BCM_STAT_MirrorAdjustLeft : 39|2@0+ (1,0) [0|3] "-"  ADAS_Body,XGW_Body
 SG_ BCM_STAT_MirrorAdjustRight : 41|2@0+ (1,0) [0|3] ""  ADAS_Body,XGW_Body

BO_ 1049 SHVU_F_Confirm_Sts: 2 SHVU_F
 SG_ SHVU_STAT_SeatHeatingFrontL : 2|3@0+ (1,0) [0|7] "-"  XGW_Body
 SG_ SHVU_STAT_SeatHeatingFrontR : 5|3@0+ (1,0) [0|7] "-"  XGW_Body
 SG_ SHVU_STAT_SeatCoolingFrontL : 10|3@0+ (1,0) [0|7] "-"  XGW_Body
 SG_ SHVU_STAT_SeatCoolingFrontR : 13|3@0+ (1,0) [0|7] ""  XGW_Body
 SG_ SHVU_STAT_FrontSeatVentSts : 15|2@0+ (1,0) [0|3] ""  XGW_Body

BO_ 1050 SHVU_R_Confirm_Sts: 2 SHVU_R
 SG_ SHVU_STAT_SeatCoolingRearL : 2|3@0+ (1,0) [0|7] "-"  XGW_Body
 SG_ SHVU_STAT_SeatCoolingRearR : 5|3@0+ (1,0) [0|7] ""  XGW_Body
 SG_ SHVU_STAT_SeatHeatingReartL : 10|3@0+ (1,0) [0|7] ""  XGW_Body
 SG_ SHVU_STAT_SeatHeatingRearR : 13|3@0+ (1,0) [0|7] ""  XGW_Body
 SG_ SHVU_STAT_RearSeatVentSts : 15|2@0+ (1,0) [0|3] ""  XGW_Body

BO_ 1052 PSM_SEAT_POSITION: 3 PSM_D
 SG_ CHKSM_PSM_SEAT_POSITION : 7|8@0+ (1,0) [0|255] ""  ACM,XGW_Body
 SG_ AVL_PSM_SEAT_POSITION : 11|4@0+ (1,0) [0|14] "-"  ACM,XGW_Body
 SG_ PSM_Seat_track_pos_Dri : 19|2@0+ (1,0) [0|3] ""  ACM,XGW_Body
 SG_ PSM_Seat_track_posPas : 21|2@0+ (1,0) [0|3] ""  ACM,XGW_Body

BO_ 1053 BCM_Comfort_Confirm_sts: 8 BCM
 SG_ BCM_STAT_AutoRearWiper : 1|2@0+ (1,0) [0|3] "-"  XGW_Body
 SG_ BCM_STAT_MirrorFoldSetting : 3|2@0+ (1,0) [0|3] ""  XGW_Body
 SG_ BCM_STAT_IMMO_KeyfobID2 : 7|3@0+ (1,0) [0|7] ""  XGW_Body
 SG_ BCM_STAT_MirrorAutoUnfold : 9|2@0+ (1,0) [0|3] "-"  XGW_Body
 SG_ BCM_STAT_MirrorReverseLink : 11|2@0+ (1,0) [0|3] ""  XGW_Body
 SG_ BCM_STAT_MirrorDefaultSTATting : 13|2@0+ (1,0) [0|3] "-"  XGW_Body
 SG_ BCM_STAT_WelcomeTriggerCondition : 15|2@0+ (1,0) [0|3] ""  XGW_Body
 SG_ BCM_STAT_FrontDomeLamp : 17|2@0+ (1,0) [0|3] "-"  XGW_Body
 SG_ BCM_STAT_FollowMeHome : 20|3@0+ (1,0) [0|7] "-"  XGW_Body
 SG_ BCM_STAT_ExteriorLight : 23|3@0+ (1,0) [0|7] "-"  XGW_Body
 SG_ BCM_STAT_RemoteLockFeedback : 26|3@0+ (1,0) [0|7] "-"  XGW_Body
 SG_ BCM_STAT_RemoteDoorUnlock : 28|2@0+ (1,0) [0|3] ""  XGW_Body
 SG_ BCM_STAT_AutoDoorUnlock : 30|2@0+ (1,0) [0|3] ""  XGW_Body
 SG_ BCM_STAT_WalkawayDoorLock : 31|1@0+ (1,0) [0|1] "" XGW_Body
 SG_ BCM_STAT_AmbientLightBrighness : 39|7@0+ (1,0) [0|100] "%"  XGW_Body
 SG_ BCM_STAT_WiperServiceMode : 42|2@0+ (1,0) [0|3] ""  XGW_Body
 SG_ BCM_STAT_IMMO_KeyfobID : 45|2@0+ (1,0) [0|3] ""  XGW_Body
 SG_ BCM_STAT_RearHeatedWindowMirror : 47|2@0+ (1,0) [0|3] ""  XGW_Body
 SG_ BCM_STAT_AntiTheftMode : 50|3@0+ (1,0) [0|7] "-"  XGW_Body
 SG_ BCM_STAT_ClimateKeepOnSts : 53|2@0+ (1,0) [0|3] ""  XGW_Body,CCU_F,CCU_R
 SG_ BCM_STAT_FKSfeedback : 55|2@0+ (1,0) [0|3] ""  XGW_Body
 SG_ SECCAN_CmftCnfrm : 63|8@0+ (1,0) [0|255] ""  XGW_Body

BO_ 1055 OCS_PasSts: 3 OCS_P
 SG_ OCS_P_CHKSM : 7|8@0+ (1,0) [0|255] ""  ACM
 SG_ OCS_P_AVL : 11|4@0+ (1,0) [0|14] ""  ACM
 SG_ OCS_Passenger_class_stat : 17|2@0+ (1,0) [0|3] ""  ACM

BO_ 1058 MHU_STATUS: 8 XGW_Body
 SG_ CHKSM_MHU_STAT : 7|8@0+ (1,0) [0|255] ""  ADAS_Body,CCU_F,PSM_D,SHVU_F,SHVU_R
 SG_ ALV_MHU_STAT : 11|4@0+ (1,0) [0|14] ""  ADAS_Body,CCU_F,PSM_D,SHVU_F,SHVU_R
 SG_ MHU_STAT_Cluster : 17|2@0+ (1,0) [0|3] "-"  CCU_F
 SG_ MHU_STAT_Infotainment : 19|2@0+ (1,0) [0|3] ""  CCU_F,PSM_D,SHVU_F,SHVU_R
 SG_ MHU_STAT_MileageUnit : 21|2@0+ (1,0) [0|3] ""  ADAS_Body,CCU_F,PSM_D,SHVU_F,SHVU_R
 SG_ MHU_STAT_PressureUnit : 23|2@0+ (1,0) [0|3] "-"  CCU_F,PSM_D,SHVU_F,SHVU_R
 SG_ MHU_STAT_TemperatureUnit : 25|2@0+ (1,0) [0|3] "-"  CCU_F,PSM_D,SHVU_F,SHVU_R
 SG_ MHU_Operation_State : 34|3@0+ (1,0) [0|7] ""  CCU_F,PSM_D,SHVU_F,SHVU_R
 SG_ MHU_STAT_Language : 39|5@0+ (1,0) [0|31] "-"  CCU_F,PSM_D,SHVU_F,SHVU_R
 SG_ MHU_STAT_EnergyConsumptionUnit : 43|4@0+ (1,0) [0|15] "-"  CCU_F,PSM_D,SHVU_F,SHVU_R
 SG_ BAS_version : 47|4@0+ (1,0) [0|15] "" Vector__XXX
 SG_ MHU_STAT_SaleCountry : 55|10@0+ (1,0) [0|1023] "-"  CCU_F,PSM_D,SHVU_F,SHVU_R

BO_ 1068 PSM_D_SEAT_CONTROL: 8 PSM_D
 SG_ CHSKM_PSM_D_SEAT_CONTROL : 7|8@0+ (1,0) [0|255] ""  XGW_Body
 SG_ ALV_PSM_D_SEAT_CONTROL : 11|4@0+ (1,0) [0|14] ""  XGW_Body
 SG_ PSM_D_DrvSeat_Control_Status : 15|3@0+ (1,0) [0|7] ""  XGW_Body
 SG_ PSM_D_DrvReclinerPos : 23|7@0+ (1,0) [0|127] "degree"  XGW_Body
 SG_ PSM_D_DrvTiltPos : 31|5@0+ (1,0) [0|31] "mm"  XGW_Body
 SG_ PSM_D_DrvTrackPos : 39|8@0+ (1,0) [0|255] "mm"  XGW_Body
 SG_ PSM_D_DrvHeightPos : 47|6@0+ (1,0) [0|63] "mm"  XGW_Body

BO_ 1074 MHU_FOTA_STATUS: 8 XGW_Body
 SG_ MHU_FOTA_Checksum : 7|8@0+ (1,0) [0|255] ""  ACM,APM,ASU_Gateway,BCM,BCM_BPM,CCU_F,CCU_R,ETG,LDM_L,LDM_R,OCS_P,PSM_D,TRM
 SG_ MHU_FOTA_Alive_Counter : 11|4@0+ (1,0) [0|14] ""  ACM,APM,ASU_Gateway,BCM,BCM_BPM,CCU_F,CCU_R,ETG,LDM_L,LDM_R,OCS_P,PSM_D,TRM
 SG_ MHU_FOTA_State : 15|4@0+ (1,0) [0|14] "-"  ACM,APM,ASU_Gateway,BCM,BCM_BPM,CCU_F,CCU_R,ETG,LDM_L,LDM_R,OCS_P,PSM_D,TRM
 SG_ MHU_FOTA_Error_Code : 23|8@0+ (1,0) [0|255] "-"  ACM,APM,ASU_Gateway,BCM,BCM_BPM,CCU_F,CCU_R,ETG,LDM_L,LDM_R,OCS_P,PSM_D,TRM

BO_ 1077 BCM_SCM_LIN_Info: 1 BCM
 SG_ BCM_SCM_BC_Button : 1|2@0+ (1,0) [0|3] "-"  XGW_Body

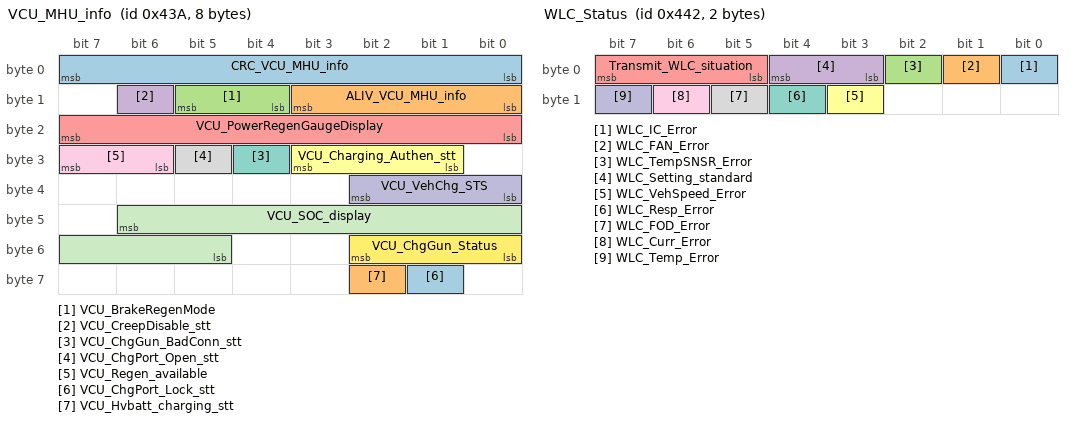
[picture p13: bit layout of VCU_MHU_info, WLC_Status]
BO_ 1082 VCU_MHU_info: 8 XGW_Body
 SG_ CRC_VCU_MHU_info : 7|8@0+ (1,0) [0|255] ""  BCM
 SG_ ALIV_VCU_MHU_info : 11|4@0+ (1,0) [0|14] ""  BCM
 SG_ VCU_BrakeRegenMode : 13|2@0+ (1,0) [0|3] "-"  BCM
 SG_ VCU_CreepDisable_stt : 14|1@0+ (1,0) [0|1] ""  BCM
 SG_ VCU_PowerRegenGaugeDisplay : 23|8@0+ (1,-100) [-100|100] "%"  BCM
 SG_ VCU_Charging_Authen_stt : 27|3@0+ (1,0) [0|7] "-"  BCM
 SG_ VCU_ChgGun_BadConn_stt : 28|1@0+ (1,0) [0|1] ""  BCM
 SG_ VCU_ChgPort_Open_stt : 29|1@0+ (1,0) [0|1] ""  BCM
 SG_ VCU_Regen_available : 31|2@0+ (1,0) [0|3] ""  BCM
 SG_ VCU_VehChg_STS : 34|3@0+ (1,0) [0|7] ""  BCM
 SG_ VCU_SOC_display : 46|10@0+ (0.1,0) [0|100] "%"  BCM
 SG_ VCU_ChgGun_Status : 50|3@0+ (1,0) [0|7] ""  BCM
 SG_ VCU_ChgPort_Lock_stt : 57|1@0+ (1,0) [0|1] ""  BCM
 SG_ VCU_Hvbatt_charging_stt : 58|1@0+ (1,0) [0|1] "-"  BCM

BO_ 1089 APM_RESP_REMOTE_FUNCTION: 8 APM
 SG_ CHKSM_RESP_REM_FUNC_APM : 7|8@0+ (1,0) [0|255] ""  XGW_Body
 SG_ RESP_REM_ResponseID_APM : 15|8@0+ (1,0) [0|254] ""  XGW_Body
 SG_ RESP_REM_DataByte0_APM : 23|8@0+ (1,0) [0|254] ""  XGW_Body
 SG_ RESP_REM_DataByte1_APM : 31|8@0+ (1,0) [0|254] ""  XGW_Body
 SG_ RESP_REM_DataByte2_APM : 39|8@0+ (1,0) [0|254] ""  XGW_Body
 SG_ RESP_REM_DataByte3_APM : 47|8@0+ (1,0) [0|254] ""  XGW_Body
 SG_ RESP_REM_DataByte4_APM : 55|8@0+ (1,0) [0|254] ""  XGW_Body
 SG_ RESP_REM_LengthTyp_APM : 57|2@0+ (1,0) [0|3] ""  XGW_Body
 SG_ RESP_REM_DataLength_APM : 63|6@0+ (1,0) [0|63] ""  XGW_Body

BO_ 1090 WLC_Status: 2 BCM
 SG_ WLC_IC_Error : 0|1@0+ (1,0) [0|1] ""  XGW_Body
 SG_ WLC_FAN_Error : 1|1@0+ (1,0) [0|1] "-"  XGW_Body
 SG_ WLC_TempSNSR_Error : 2|1@0+ (1,0) [0|1] "-"  XGW_Body
 SG_ WLC_Setting_standard : 4|2@0+ (1,0) [0|3] "-"  XGW_Body
 SG_ Transmit_WLC_situation : 7|3@0+ (1,0) [0|7] ""  XGW_Body
 SG_ WLC_VehSpeed_Error : 11|1@0+ (1,0) [0|1] ""  XGW_Body
 SG_ WLC_Resp_Error : 12|1@0+ (1,0) [0|1] ""  XGW_Body
 SG_ WLC_FOD_Error : 13|1@0+ (1,0) [0|1] "-"  XGW_Body
 SG_ WLC_Curr_Error : 14|1@0+ (1,0) [0|1] "-"  XGW_Body
 SG_ WLC_Temp_Error : 15|1@0+ (1,0) [0|1] ""  XGW_Body

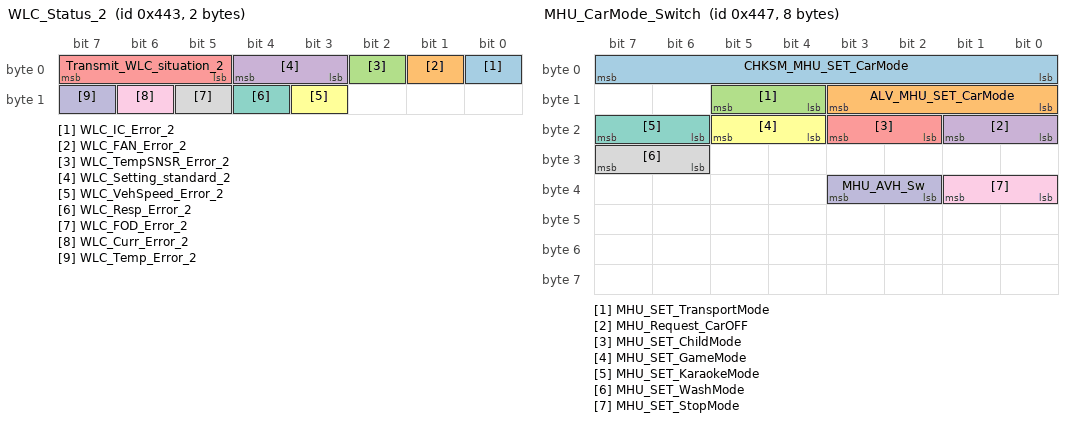
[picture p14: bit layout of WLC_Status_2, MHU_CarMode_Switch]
BO_ 1091 WLC_Status_2: 2 BCM
 SG_ WLC_IC_Error_2 : 0|1@0+ (1,0) [0|1] "-"  XGW_Body
 SG_ WLC_FAN_Error_2 : 1|1@0+ (1,0) [0|1] ""  XGW_Body
 SG_ WLC_TempSNSR_Error_2 : 2|1@0+ (1,0) [0|1] "-"  XGW_Body
 SG_ WLC_Setting_standard_2 : 4|2@0+ (1,0) [0|3] ""  XGW_Body
 SG_ Transmit_WLC_situation_2 : 7|3@0+ (1,0) [0|7] ""  XGW_Body
 SG_ WLC_VehSpeed_Error_2 : 11|1@0+ (1,0) [0|1] ""  XGW_Body
 SG_ WLC_Resp_Error_2 : 12|1@0+ (1,0) [0|1] "-"  XGW_Body
 SG_ WLC_FOD_Error_2 : 13|1@0+ (1,0) [0|1] "-"  XGW_Body
 SG_ WLC_Curr_Error_2 : 14|1@0+ (1,0) [0|1] "-"  XGW_Body
 SG_ WLC_Temp_Error_2 : 15|1@0+ (1,0) [0|1] ""  XGW_Body

BO_ 1093 BCM_RainLightSnr: 5 BCM
 SG_ RS_Sol_L : 7|8@0+ (5,0) [0|1000] "W/m^2"  CCU_F,LDM_L,LDM_R,XGW_Body
 SG_ RS_Sol_R : 15|8@0+ (5,0) [0|1000] "W/m^2"  CCU_F,LDM_L,LDM_R,XGW_Body
 SG_ RS_F_LightSensor : 17|1@0+ (1,0) [0|1] ""  XGW_Body
 SG_ RS_F_HUD_Sensor : 18|1@0+ (1,0) [0|1] "cd/m2"  XGW_Body
 SG_ RS_St_LampReq : 20|2@0+ (1,0) [0|3] ""  CCU_F,LDM_L,LDM_R,XGW_Body
 SG_ RS_St_CurrentRain : 23|3@0+ (1,0) [0|7] ""  ADAS_Body,CCU_F,XGW_Body
 SG_ RS_HUD_illuminance : 31|16@0+ (1,0) [0|10000] "cd/m2"  ADAS_Body,XGW_Body

BO_ 1095 MHU_CarMode_Switch: 8 XGW_Body
 SG_ CHKSM_MHU_SET_CarMode : 7|8@0+ (1,0) [0|255] ""  BCM
 SG_ ALV_MHU_SET_CarMode : 11|4@0+ (1,0) [0|14] ""  BCM
 SG_ MHU_SET_TransportMode : 13|2@0+ (1,0) [0|3] "" BCM
 SG_ MHU_Request_CarOFF : 17|2@0+ (1,0) [0|3] "-"  BCM
 SG_ MHU_SET_ChildMode : 19|2@0+ (1,0) [0|3] ""  BCM
 SG_ MHU_SET_GameMode : 21|2@0+ (1,0) [0|3] ""  BCM
 SG_ MHU_SET_KaraokeMode : 23|2@0+ (1,0) [0|3] ""  BCM
 SG_ MHU_SET_WashMode : 31|2@0+ (1,0) [0|3] ""  BCM
 SG_ MHU_SET_StopMode : 33|2@0+ (1,0) [0|3] ""  BCM
 SG_ MHU_AVH_Sw : 35|2@0+ (1,0) [0|3] "" BCM

BO_ 1104 MHU_WindowSetting: 8 XGW_Body
 SG_ WindowLifterFrontL : 7|3@0+ (1,0) [0|7] ""  APM
 SG_ WindowLifterFrontR : 15|3@0+ (1,0) [0|7] ""  APM
 SG_ WindowLifterRearL : 23|3@0+ (1,0) [0|7] ""  APM
 SG_ WindowLifterRearR : 31|3@0+ (1,0) [0|7] ""  APM
 SG_ MHU_SET_WindowAutoClose : 39|3@0+ (1,0) [0|3] ""  APM

BO_ 1110 SCM_Raw_Status: 5 BCM
 SG_ OP_WISW_SZL_LIN : 7|8@0+ (1,0) [0|255] ""  ADAS_Body,XGW_Body
 SG_ COMM_ERR_SZL_LIN : 8|1@0+ (1,0) [0|1] ""  XGW_Body
 SG_ BCM_Wiper_Front_Status : 12|3@0+ (1,0) [0|7] ""  ADAS_Body,XGW_Body
 SG_ OP_WIPO_SZL_LIN : 15|3@0+ (1,0) [0|7] "-"  ADAS_Body,XGW_Body
 SG_ OP_COLS_SZL_LIN : 23|8@0+ (1,0) [0|255] "-"  ADAS_Body,XGW_Body
 SG_ NOD_ERR_SZL_LIN : 25|2@0+ (1,0) [0|3] ""  XGW_Body
 SG_ BCM_Wiper_Rear_Status : 27|2@0+ (1,0) [0|3] ""  XGW_Body
 SG_ ALIV_WISW_SZL_LIN : 31|4@0+ (1,0) [0|14] ""  ADAS_Body,XGW_Body

BO_ 1111 BCM_ALM_warning: 1 BCM
 SG_ AmbLight_Error_Z5 : 3|1@0+ (1,0) [0|1] "-"  XGW_Body
 SG_ AmbLight_Error_Z4 : 4|1@0+ (1,0) [0|1] ""  XGW_Body
 SG_ AmbLight_Error_Z3 : 5|1@0+ (1,0) [0|1] "-"  XGW_Body
 SG_ AmbLight_Error_Z2 : 6|1@0+ (1,0) [0|1] ""  XGW_Body
 SG_ AmbLight_Error_Z1 : 7|1@0+ (1,0) [0|1] ""  XGW_Body

BO_ 1112 MHU_BCM_Color_Req: 8 XGW_Body
 SG_ AmbLightColorZoneReq : 7|8@0+ (1,0) [0|31] "-"  BCM
 SG_ AmbLightColorRed : 15|8@0+ (1,0) [0|255] ""  BCM
 SG_ AmbLightColorGreen : 23|8@0+ (1,0) [0|255] "-"  BCM
 SG_ AmbLightColorBlue : 31|8@0+ (1,0) [0|255] "-"  BCM
 SG_ SECCAN_BCM_Clr_Rq : 63|8@0+ (1,0) [0|255] ""  BCM

BO_ 1113 MHU_BCM_IntensityTiming_Req: 8 XGW_Body
 SG_ AmbLightIntensityTimingZoneReq : 7|8@0+ (1,0) [0|31] ""  BCM
 SG_ AmbLightIntensityTimingTypeReq : 15|8@0+ (1,0) [0|5] ""  BCM
 SG_ AmbLightIntenTimingBrightReq : 23|8@0+ (1,0) [0|100] ""  BCM
 SG_ AmbLightIntensityTimingT1Req : 31|8@0+ (0.1,0) [0|25.5] "s"  BCM
 SG_ AmbLightIntensityTimingT2Req : 39|8@0+ (0.1,0) [0|25.5] "s"  BCM
 SG_ AmbLightIntensityTimingT3Req : 47|8@0+ (0.1,0) [0|25.5] "s"  BCM
 SG_ AmbLightIntensityTimingT4Req : 55|8@0+ (0.1,0) [0|25.5] "s"  BCM
 SG_ AmbLightIntensityTimingN2Req : 59|4@0+ (1,0) [0|15] "-"  BCM
 SG_ AmbLightIntensityTimingN1Req : 63|4@0+ (1,0) [0|15] ""  BCM

BO_ 1115 ADAS_HOD: 8 ADAS_Body
 SG_ HOD_steering_wheel_type : 5|4@0+ (1,0) [0|15] ""  XGW_Body
 SG_ HOD_vehicle_type : 15|8@0+ (1,0) [0|255] ""  XGW_Body
 SG_ ADAS_HOD_state_requesting : 57|2@0+ (1,0) [0|3] ""  XGW_Body

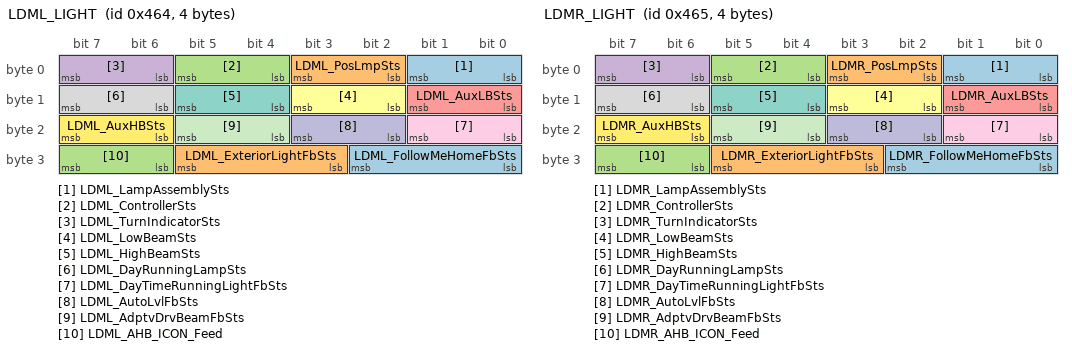
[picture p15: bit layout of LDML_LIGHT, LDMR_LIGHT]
BO_ 1124 LDML_LIGHT: 4 LDM_L
 SG_ LDML_LampAssemblySts : 1|2@0+ (1,0) [0|3] "-"  BCM,XGW_Body
 SG_ LDML_PosLmpSts : 3|2@0+ (1,0) [0|3] ""  BCM,XGW_Body
 SG_ LDML_ControllerSts : 5|2@0+ (1,0) [0|3] ""  BCM,XGW_Body
 SG_ LDML_TurnIndicatorSts : 7|2@0+ (1,0) [0|3] ""  BCM,XGW_Body
 SG_ LDML_AuxLBSts : 9|2@0+ (1,0) [0|3] "-"  BCM,XGW_Body
 SG_ LDML_LowBeamSts : 11|2@0+ (1,0) [0|3] "-"  BCM,XGW_Body
 SG_ LDML_HighBeamSts : 13|2@0+ (1,0) [0|3] ""  BCM,XGW_Body
 SG_ LDML_DayRunningLampSts : 15|2@0+ (1,0) [0|3] ""  BCM,XGW_Body
 SG_ LDML_DayTimeRunningLightFbSts : 17|2@0+ (1,0) [0|3] ""  BCM,XGW_Body
 SG_ LDML_AutoLvlFbSts : 19|2@0+ (1,0) [0|3] ""  BCM,XGW_Body
 SG_ LDML_AdptvDrvBeamFbSts : 21|2@0+ (1,0) [0|3] "-"  BCM,XGW_Body
 SG_ LDML_AuxHBSts : 23|2@0+ (1,0) [0|3] "-"  BCM,XGW_Body
 SG_ LDML_FollowMeHomeFbSts : 26|3@0+ (1,0) [0|5] "-"  BCM,XGW_Body
 SG_ LDML_ExteriorLightFbSts : 29|3@0+ (1,0) [0|4] "-"  BCM,XGW_Body
 SG_ LDML_AHB_ICON_Feed : 31|2@0+ (1,0) [0|3] ""  XGW_Body

BO_ 1125 LDMR_LIGHT: 4 LDM_R
 SG_ LDMR_LampAssemblySts : 1|2@0+ (1,0) [0|3] ""  BCM,XGW_Body
 SG_ LDMR_PosLmpSts : 3|2@0+ (1,0) [0|3] "-"  BCM,XGW_Body
 SG_ LDMR_ControllerSts : 5|2@0+ (1,0) [0|3] ""  BCM,XGW_Body
 SG_ LDMR_TurnIndicatorSts : 7|2@0+ (1,0) [0|3] "-"  BCM,XGW_Body
 SG_ LDMR_AuxLBSts : 9|2@0+ (1,0) [0|3] "-"  BCM,XGW_Body
 SG_ LDMR_LowBeamSts : 11|2@0+ (1,0) [0|3] "-"  BCM,XGW_Body
 SG_ LDMR_HighBeamSts : 13|2@0+ (1,0) [0|3] ""  BCM,XGW_Body
 SG_ LDMR_DayRunningLampSts : 15|2@0+ (1,0) [0|3] ""  BCM,XGW_Body
 SG_ LDMR_DayTimeRunningLightFbSts : 17|2@0+ (1,0) [0|3] "-"  BCM,XGW_Body
 SG_ LDMR_AutoLvlFbSts : 19|2@0+ (1,0) [0|3] "-"  BCM,XGW_Body
 SG_ LDMR_AdptvDrvBeamFbSts : 21|2@0+ (1,0) [0|3] ""  BCM,XGW_Body
 SG_ LDMR_AuxHBSts : 23|2@0+ (1,0) [0|3] "-"  BCM,XGW_Body
 SG_ LDMR_FollowMeHomeFbSts : 26|3@0+ (1,0) [0|5] ""  BCM,XGW_Body
 SG_ LDMR_ExteriorLightFbSts : 29|3@0+ (1,0) [0|4] "-"  BCM,XGW_Body
 SG_ LDMR_AHB_ICON_Feed : 31|2@0+ (1,0) [0|3] ""  XGW_Body

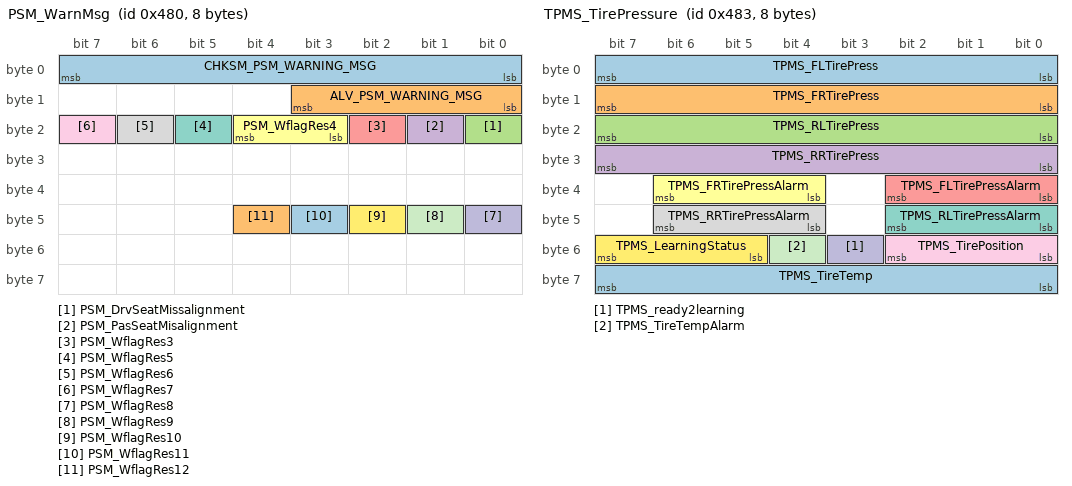
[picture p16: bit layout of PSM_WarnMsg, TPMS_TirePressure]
BO_ 1152 PSM_WarnMsg: 8 PSM_D
 SG_ CHKSM_PSM_WARNING_MSG : 7|8@0+ (1,0) [0|255] ""  XGW_Body
 SG_ ALV_PSM_WARNING_MSG : 11|4@0+ (1,0) [0|14] ""  XGW_Body
 SG_ PSM_DrvSeatMissalignment : 16|1@0+ (1,0) [0|1] ""  XGW_Body
 SG_ PSM_PasSeatMisalignment : 17|1@0+ (1,0) [0|1] "Bit"  XGW_Body
 SG_ PSM_WflagRes3 : 18|1@0+ (1,0) [0|1] "Bit"  XGW_Body
 SG_ PSM_WflagRes4 : 20|2@0+ (1,0) [0|3] "Bit"  XGW_Body
 SG_ PSM_WflagRes5 : 21|1@0+ (1,0) [0|1] "-"  XGW_Body
 SG_ PSM_WflagRes6 : 22|1@0+ (1,0) [0|1] "-"  XGW_Body
 SG_ PSM_WflagRes7 : 23|1@0+ (1,0) [0|1] "-"  XGW_Body
 SG_ PSM_WflagRes8 : 40|1@0+ (1,0) [0|1] ""  XGW_Body
 SG_ PSM_WflagRes9 : 41|1@0+ (1,0) [0|1] ""  XGW_Body
 SG_ PSM_WflagRes10 : 42|1@0+ (1,0) [0|1] "-"  XGW_Body
 SG_ PSM_WflagRes11 : 43|1@0+ (1,0) [0|1] "-"  XGW_Body
 SG_ PSM_WflagRes12 : 44|1@0+ (1,0) [0|1] "-"  XGW_Body

BO_ 1153 BCM_WarnMsg: 8 BCM
 SG_ CHSKM_BCM_WarnMsg : 7|8@0+ (1,0) [0|255] "" XGW_Body
 SG_ ALV_BCM_WarnMsg : 11|4@0+ (1,0) [0|14] "" XGW_Body
 SG_ BCM_NoValidKey_1 : 12|1@0+ (1,0) [0|1] "" XGW_Body
 SG_ BCM_SSB_defect : 13|1@0+ (1,0) [0|1] "" XGW_Body
 SG_ BCM_WrongGearPosToStart : 14|1@0+ (1,0) [0|1] "" XGW_Body
 SG_ BCM_NoValidKey_2 : 15|1@0+ (1,0) [0|1] "" XGW_Body
 SG_ BCM_PressBrakeToStart : 16|1@0+ (1,0) [0|1] "" XGW_Body
 SG_ BCM_TurnOffPosLightRemindr : 17|1@0+ (1,0) [0|1] "" XGW_Body
 SG_ BCM_KeyFob_LowBattery : 18|1@0+ (1,0) [0|1] "" XGW_Body
 SG_ BCM_StopLightDefect : 19|1@0+ (1,0) [0|1] "" XGW_Body
 SG_ BCM_LowBeamDefect : 20|1@0+ (1,0) [0|1] "" XGW_Body
 SG_ BCM_HighBeamDefect : 21|1@0+ (1,0) [0|1] "" XGW_Body
 SG_ BCM_PositionLightDefect : 22|1@0+ (1,0) [0|1] "" XGW_Body
 SG_ BCM_CHMLS_Defect : 23|1@0+ (1,0) [0|1] "" XGW_Body
 SG_ BCM_LicencePlateLight_Defect : 24|1@0+ (1,0) [0|1] "" XGW_Body
 SG_ BCM_FrontFog_Defect : 25|1@0+ (1,0) [0|1] "" XGW_Body
 SG_ BCM_RearFog_Defect : 26|1@0+ (1,0) [0|1] "" XGW_Body
 SG_ BCM_ReverseLightDefect : 27|1@0+ (1,0) [0|1] "" XGW_Body
 SG_ BCM_RLS_Malfunction : 28|1@0+ (1,0) [0|1] "" XGW_Body
 SG_ BCM_12VBattery_LowLevel : 29|1@0+ (1,0) [0|1] "" XGW_Body
 SG_ BCM_ForgetKeyFOBInCar : 30|1@0+ (1,0) [0|1] "" XGW_Body
 SG_ BCM_12VBattery_Discharging : 31|1@0+ (1,0) [0|1] "" XGW_Body
 SG_ BCM_TurnIndicatorDefect : 32|1@0+ (1,0) [0|1] "" XGW_Body
 SG_ BCM_dTPMS_Malfunc : 33|1@0+ (1,0) [0|1] "" XGW_Body
 SG_ BCM_dTPMS_Malfunc_LostSensor : 34|1@0+ (1,0) [0|1] "" XGW_Body
 SG_ BCM_dTPMS_LowPressure : 35|1@0+ (1,0) [0|1] "" XGW_Body
 SG_ BCM_dTPMS_RapidLeak : 36|1@0+ (1,0) [0|1] "" XGW_Body
 SG_ BCM_dTPMS_HighTemperature : 37|1@0+ (1,0) [0|1] "" XGW_Body
 SG_ BCM_dTPMS_HighPressure : 38|1@0+ (1,0) [0|1] "" XGW_Body
 SG_ BCM_dTPMS_LowBattery : 39|1@0+ (1,0) [0|1] "" XGW_Body
 SG_ BCM_Keyfob_Leftcar : 40|1@0+ (1,0) [0|1] "" XGW_Body
 SG_ BCM_IDB_Brakelight_Malfunction : 41|1@0+ (1,0) [0|1] "" XGW_Body
 SG_ BCM_VCU_Brakelight_Malfunction : 42|1@0+ (1,0) [0|1] "" XGW_Body
 SG_ BCM_ADAS_Turnlight_Malfunction : 43|1@0+ (1,0) [0|1] "" XGW_Body
 SG_ BCM_ADAS_Highbeam_Malfunction : 44|1@0+ (1,0) [0|1] "" XGW_Body
 SG_ BCM_ADAS_LowBeam_Malfunction : 45|1@0+ (1,0) [0|1] "" XGW_Body
 SG_ BCM_MHU_Malfunction : 46|1@0+ (1,0) [0|1] "" XGW_Body
 SG_ BCM_BCM_Malfunction : 47|1@0+ (1,0) [0|1] "" XGW_Body
 SG_ BCM_SCM_Malfunction : 48|1@0+ (1,0) [0|1] "" XGW_Body
 SG_ BCM_CrashSignalDefect : 49|1@0+ (1,0) [0|1] "" XGW_Body
 SG_ BCM_FrontWiperDefect : 51|1@0+ (1,0) [0|1] "" XGW_Body
 SG_ BCM_Rear_RightDoorLockDefect : 52|1@0+ (1,0) [0|1] "" XGW_Body
 SG_ BCM_RearLeftDoorLockDefect : 53|1@0+ (1,0) [0|1] "" XGW_Body
 SG_ BCM_Front_RightDoorLockDefect : 54|1@0+ (1,0) [0|1] "" XGW_Body
 SG_ BCM_FrontLeftDoorLockDefect : 55|1@0+ (1,0) [0|1] "" XGW_Body
 SG_ BCM_LDML_Malfunction : 56|1@0+ (1,0) [0|1] "" XGW_Body
 SG_ BCM_LDMR_Malfunction : 57|1@0+ (1,0) [0|1] "" XGW_Body
 SG_ BCM_RLBL_Malfunction : 58|1@0+ (1,0) [0|1] "" XGW_Body
 SG_ BCM_RLBR_Malfunction : 59|1@0+ (1,0) [0|1] "" XGW_Body
 SG_ BCM_RLT_Malfunction : 60|1@0+ (1,0) [0|1] "" XGW_Body
 SG_ BCM_BCM_POWER_Malfunction : 61|1@0+ (1,0) [0|1] "" XGW_Body
 SG_ BCM_IDB_AutoHazardBlinking_Malf : 62|1@0+ (1,0) [0|1] "" XGW_Body

BO_ 1155 TPMS_TirePressure: 8 BCM
 SG_ TPMS_FLTirePress : 7|8@0+ (1.373,0) [0|350] "kPa"  ADAS_Body,XGW_Body
 SG_ TPMS_FRTirePress : 15|8@0+ (1.373,0) [0|350] "kPa"  ADAS_Body,XGW_Body
 SG_ TPMS_RLTirePress : 23|8@0+ (1.373,0) [0|350] "kPa"  ADAS_Body,XGW_Body
 SG_ TPMS_RRTirePress : 31|8@0+ (1.373,0) [0|350] "kPa"  ADAS_Body,XGW_Body
 SG_ TPMS_FLTirePressAlarm : 34|3@0+ (1,0) [0|7] ""  ADAS_Body,XGW_Body
 SG_ TPMS_FRTirePressAlarm : 38|3@0+ (1,0) [0|7] "-"  ADAS_Body,XGW_Body
 SG_ TPMS_RLTirePressAlarm : 42|3@0+ (1,0) [0|7] ""  ADAS_Body,XGW_Body
 SG_ TPMS_RRTirePressAlarm : 46|3@0+ (1,0) [0|7] ""  ADAS_Body,XGW_Body
 SG_ TPMS_TirePosition : 50|3@0+ (1,0) [0|7] "-"  XGW_Body
 SG_ TPMS_ready2learning : 51|1@0+ (1,0) [0|1] "-"  XGW_Body
 SG_ TPMS_TireTempAlarm : 52|1@0+ (1,0) [0|1] "-"  XGW_Body
 SG_ TPMS_LearningStatus : 55|3@0+ (1,0) [0|7] "-"  XGW_Body
 SG_ TPMS_TireTemp : 63|8@0+ (1,-40) [-40|215] "Degree C"  XGW_Body

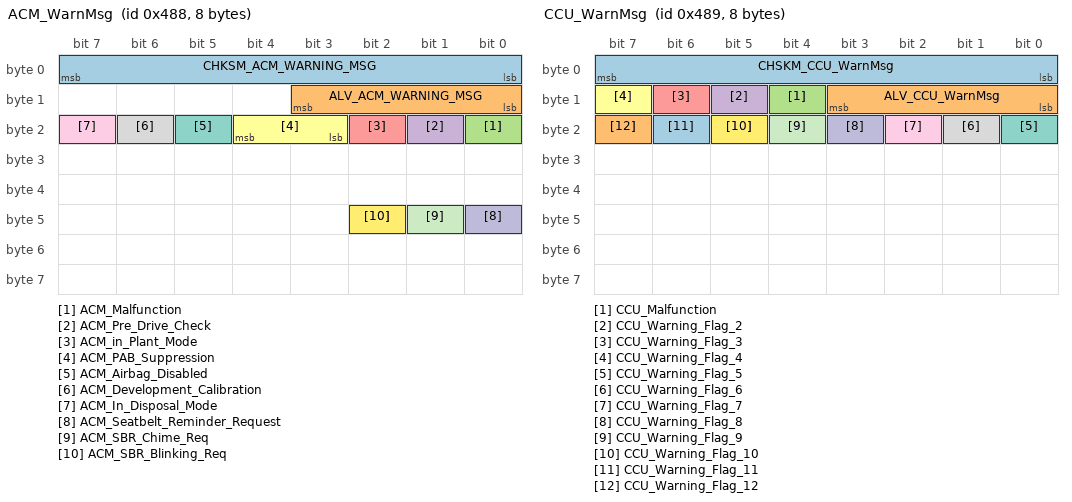
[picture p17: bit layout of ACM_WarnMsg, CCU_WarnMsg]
BO_ 1160 ACM_WarnMsg: 8 ACM
 SG_ CHKSM_ACM_WARNING_MSG : 7|8@0+ (1,0) [0|255] ""  XGW_Body
 SG_ ALV_ACM_WARNING_MSG : 11|4@0+ (1,0) [0|14] ""  XGW_Body
 SG_ ACM_Malfunction : 16|1@0+ (1,0) [0|1] ""  XGW_Body
 SG_ ACM_Pre_Drive_Check : 17|1@0+ (1,0) [0|1] "Bit"  XGW_Body
 SG_ ACM_in_Plant_Mode : 18|1@0+ (1,0) [0|1] "Bit"  XGW_Body
 SG_ ACM_PAB_Suppression : 20|2@0+ (1,0) [0|3] "Bit"  XGW_Body
 SG_ ACM_Airbag_Disabled : 21|1@0+ (1,0) [0|1] "-"  XGW_Body
 SG_ ACM_Development_Calibration : 22|1@0+ (1,0) [0|1] "-"  XGW_Body
 SG_ ACM_In_Disposal_Mode : 23|1@0+ (1,0) [0|1] ""  XGW_Body
 SG_ ACM_Seatbelt_Reminder_Request : 40|1@0+ (1,0) [0|1] "-"  XGW_Body
 SG_ ACM_SBR_Chime_Req : 41|1@0+ (1,0) [0|1] ""  XGW_Body
 SG_ ACM_SBR_Blinking_Req : 42|1@0+ (1,0) [0|1] ""  XGW_Body

BO_ 1161 CCU_WarnMsg: 8 CCU_F
 SG_ CHSKM_CCU_WarnMsg : 7|8@0+ (1,0) [0|255] ""  XGW_Body
 SG_ ALV_CCU_WarnMsg : 11|4@0+ (1,0) [0|14] ""  XGW_Body
 SG_ CCU_Malfunction : 12|1@0+ (1,0) [0|1] ""  XGW_Body
 SG_ CCU_Warning_Flag_2 : 13|1@0+ (1,0) [0|1] "-"  XGW_Body
 SG_ CCU_Warning_Flag_3 : 14|1@0+ (1,0) [0|1] ""  XGW_Body
 SG_ CCU_Warning_Flag_4 : 15|1@0+ (1,0) [0|1] "-"  XGW_Body
 SG_ CCU_Warning_Flag_5 : 16|1@0+ (1,0) [0|1] "-"  XGW_Body
 SG_ CCU_Warning_Flag_6 : 17|1@0+ (1,0) [0|1] "-"  XGW_Body
 SG_ CCU_Warning_Flag_7 : 18|1@0+ (1,0) [0|1] "-"  XGW_Body
 SG_ CCU_Warning_Flag_8 : 19|1@0+ (1,0) [0|1] ""  XGW_Body
 SG_ CCU_Warning_Flag_9 : 20|1@0+ (1,0) [0|1] ""  XGW_Body
 SG_ CCU_Warning_Flag_10 : 21|1@0+ (1,0) [0|1] ""  XGW_Body
 SG_ CCU_Warning_Flag_11 : 22|1@0+ (1,0) [0|1] ""  XGW_Body
 SG_ CCU_Warning_Flag_12 : 23|1@0+ (1,0) [0|1] ""  XGW_Body

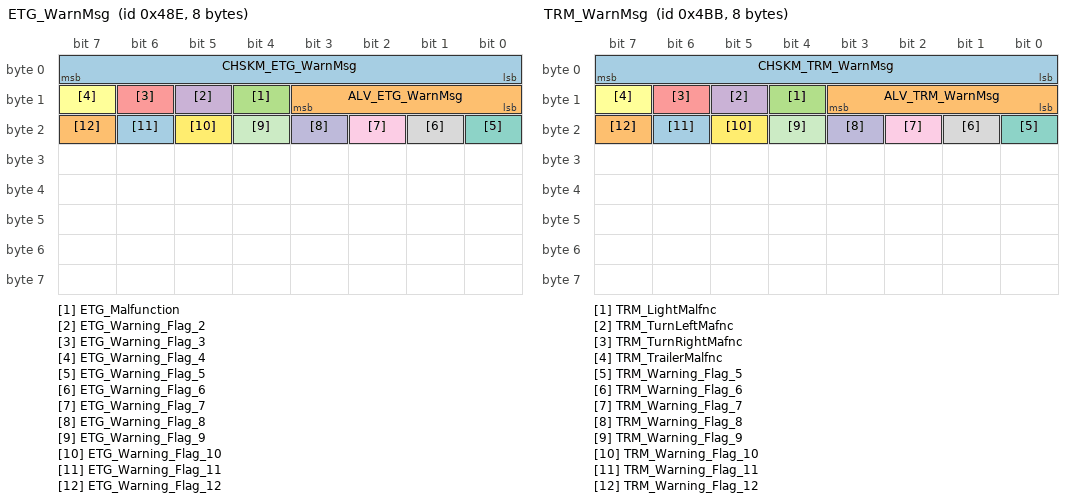
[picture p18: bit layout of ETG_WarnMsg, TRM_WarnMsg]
BO_ 1166 ETG_WarnMsg: 8 ETG
 SG_ CHSKM_ETG_WarnMsg : 7|8@0+ (1,0) [0|255] ""  XGW_Body
 SG_ ALV_ETG_WarnMsg : 11|4@0+ (1,0) [0|14] ""  XGW_Body
 SG_ ETG_Malfunction : 12|1@0+ (1,0) [0|1] "-"  XGW_Body
 SG_ ETG_Warning_Flag_2 : 13|1@0+ (1,0) [0|1] "-"  XGW_Body
 SG_ ETG_Warning_Flag_3 : 14|1@0+ (1,0) [0|1] ""  XGW_Body
 SG_ ETG_Warning_Flag_4 : 15|1@0+ (1,0) [0|1] ""  XGW_Body
 SG_ ETG_Warning_Flag_5 : 16|1@0+ (1,0) [0|1] "-"  XGW_Body
 SG_ ETG_Warning_Flag_6 : 17|1@0+ (1,0) [0|1] "-"  XGW_Body
 SG_ ETG_Warning_Flag_7 : 18|1@0+ (1,0) [0|1] "-"  XGW_Body
 SG_ ETG_Warning_Flag_8 : 19|1@0+ (1,0) [0|1] ""  XGW_Body
 SG_ ETG_Warning_Flag_9 : 20|1@0+ (1,0) [0|1] ""  XGW_Body
 SG_ ETG_Warning_Flag_10 : 21|1@0+ (1,0) [0|1] ""  XGW_Body
 SG_ ETG_Warning_Flag_11 : 22|1@0+ (1,0) [0|1] "-"  XGW_Body
 SG_ ETG_Warning_Flag_12 : 23|1@0+ (1,0) [0|1] ""  XGW_Body

BO_ 1171 BMS_WarnMsg: 8 XGW_Body
 SG_ CHSKM_BMS_WarnMsg : 7|8@0+ (1,0) [0|255] "" BCM
 SG_ ALV_BMS_WarnMsg : 11|4@0+ (1,0) [0|14] "" BCM
 SG_ BMS_PackTempSts : 13|2@0+ (1,0) [0|3] "" BCM
 SG_ BMS_ThermalRunaway : 14|1@0+ (1,0) [0|1] "" BCM
 SG_ BMS_BatteryReplacement : 15|1@0+ (1,0) [0|1] "" BCM
 SG_ BMS_Warning_PowerDegrade : 16|1@0+ (1,0) [0|1] "" BCM
 SG_ BMS_Warning_DeltaSoC : 17|1@0+ (1,0) [0|1] "" BCM
 SG_ BMS_Warning_HVILSts : 18|1@0+ (1,0) [0|1] "" BCM
 SG_ BMS_Warning_Isolation : 19|1@0+ (1,0) [0|1] "" BCM
 SG_ BMS_Warning_CoolantLeakage : 20|1@0+ (1,0) [0|1] "" BCM
 SG_ BMS_MalfunctionSts : 21|1@0+ (1,0) [0|1] "" BCM
 SG_ BMS_LowBattery : 23|2@0+ (1,0) [0|3] "" BCM
 SG_ BMS_Warning_DeltaTemperature : 31|8@0+ (1,0) [0|255] "" BCM
 SG_ BMS_Warning_BDUTemperatureSts : 39|8@0+ (1,0) [0|255] "" BCM
 SG_ BMS_Warning_Contactor_Aging : 47|1@0+ (1,0) [0|1] "" DUMMY_ECU
 SG_ BMS_Reserved_signal4 : 55|8@0+ (1,0) [0|255] "" BCM
 SG_ BMS_Reserved_signal5 : 63|8@0+ (1,0) [0|255] "" BCM

BO_ 1211 TRM_WarnMsg: 8 TRM
 SG_ CHSKM_TRM_WarnMsg : 7|8@0+ (1,0) [0|255] ""  XGW_Body
 SG_ ALV_TRM_WarnMsg : 11|4@0+ (1,0) [0|14] ""  XGW_Body
 SG_ TRM_LightMalfnc : 12|1@0+ (1,0) [0|1] "-"  XGW_Body
 SG_ TRM_TurnLeftMafnc : 13|1@0+ (1,0) [0|1] "-"  XGW_Body
 SG_ TRM_TurnRightMafnc : 14|1@0+ (1,0) [0|1] ""  XGW_Body
 SG_ TRM_TrailerMalfnc : 15|1@0+ (1,0) [0|1] ""  XGW_Body
 SG_ TRM_Warning_Flag_5 : 16|1@0+ (1,0) [0|1] "-"  XGW_Body
 SG_ TRM_Warning_Flag_6 : 17|1@0+ (1,0) [0|1] ""  XGW_Body
 SG_ TRM_Warning_Flag_7 : 18|1@0+ (1,0) [0|1] ""  XGW_Body
 SG_ TRM_Warning_Flag_8 : 19|1@0+ (1,0) [0|1] "-"  XGW_Body
 SG_ TRM_Warning_Flag_9 : 20|1@0+ (1,0) [0|1] "-"  XGW_Body
 SG_ TRM_Warning_Flag_10 : 21|1@0+ (1,0) [0|1] "-"  XGW_Body
 SG_ TRM_Warning_Flag_11 : 22|1@0+ (1,0) [0|1] ""  XGW_Body
 SG_ TRM_Warning_Flag_12 : 23|1@0+ (1,0) [0|1] ""  XGW_Body

BO_ 1216 BCM_STAT_DOOR: 8 BCM
 SG_ SECCAN_BCM_STAT_Door : 55|8@0+ (1,0) [0|255] ""  ADAS_Body
 SG_ BCM_STAT_DoorHandleRR : 56|1@0+ (1,0) [0|1] ""  ADAS_Body
 SG_ BCM_STAT_DoorHandleRL : 57|1@0+ (1,0) [0|1] ""  ADAS_Body
 SG_ BCM_STAT_DoorHandleFR : 58|1@0+ (1,0) [0|1] ""  ADAS_Body
 SG_ BCM_STAT_DoorHandleFL : 59|1@0+ (1,0) [0|1] ""  ADAS_Body

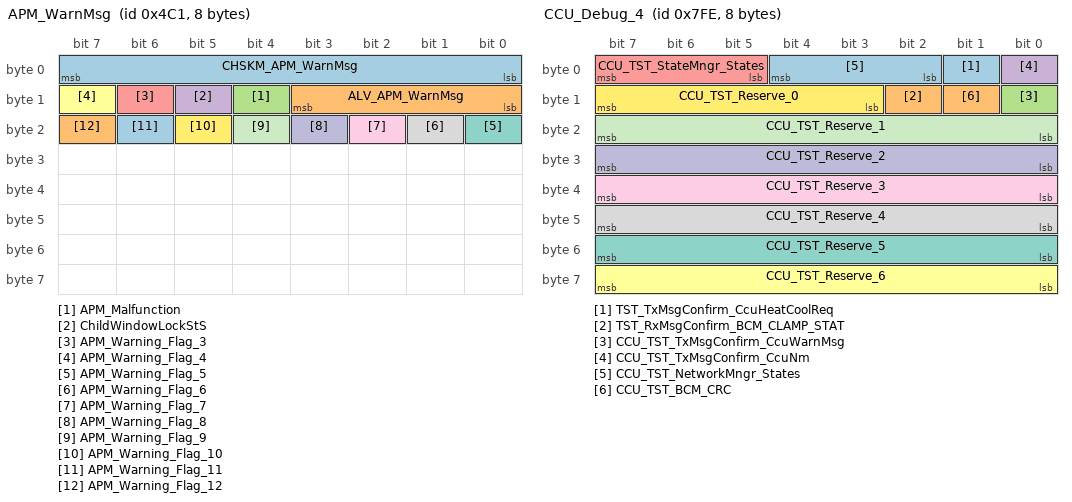
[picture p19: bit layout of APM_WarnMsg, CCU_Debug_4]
BO_ 1217 APM_WarnMsg: 8 APM
 SG_ CHSKM_APM_WarnMsg : 7|8@0+ (1,0) [0|255] ""  XGW_Body
 SG_ ALV_APM_WarnMsg : 11|4@0+ (1,0) [0|14] ""  XGW_Body
 SG_ APM_Malfunction : 12|1@0+ (1,0) [0|1] ""  XGW_Body
 SG_ ChildWindowLockStS : 13|1@0+ (1,0) [0|1] "-"  XGW_Body
 SG_ APM_Warning_Flag_3 : 14|1@0+ (1,0) [0|1] ""  XGW_Body
 SG_ APM_Warning_Flag_4 : 15|1@0+ (1,0) [0|1] ""  XGW_Body
 SG_ APM_Warning_Flag_5 : 16|1@0+ (1,0) [0|1] "-"  XGW_Body
 SG_ APM_Warning_Flag_6 : 17|1@0+ (1,0) [0|1] ""  XGW_Body
 SG_ APM_Warning_Flag_7 : 18|1@0+ (1,0) [0|1] "-"  XGW_Body
 SG_ APM_Warning_Flag_8 : 19|1@0+ (1,0) [0|1] ""  XGW_Body
 SG_ APM_Warning_Flag_9 : 20|1@0+ (1,0) [0|1] ""  XGW_Body
 SG_ APM_Warning_Flag_10 : 21|1@0+ (1,0) [0|1] ""  XGW_Body
 SG_ APM_Warning_Flag_11 : 22|1@0+ (1,0) [0|1] ""  XGW_Body
 SG_ APM_Warning_Flag_12 : 23|1@0+ (1,0) [0|1] "-"  XGW_Body

BO_ 1281 BCM_NM: 8 BCM
 SG_ BCM_srcNodeID : 7|8@0+ (1,0) [0|255] ""  APM,CCU_F,CCU_R,ETG,LDM_L,LDM_R,PSM_D,TRM,XGW_Body
 SG_ BCM_CtrlBitVector : 15|8@0+ (1,0) [0|255] ""  APM,CCU_F,CCU_R,ETG,LDM_L,LDM_R,PSM_D,TRM,XGW_Body
 SG_ BCM_usrData0 : 23|8@0+ (1,0) [0|255] ""  APM,CCU_F,CCU_R,ETG,LDM_L,LDM_R,PSM_D,TRM,XGW_Body
 SG_ BCM_usrData1 : 31|8@0+ (1,0) [0|255] ""  APM,CCU_F,CCU_R,ETG,LDM_L,LDM_R,PSM_D,TRM,XGW_Body
 SG_ BCM_usrData2 : 39|8@0+ (1,0) [0|255] ""  APM,CCU_F,CCU_R,ETG,LDM_L,LDM_R,PSM_D,TRM,XGW_Body
 SG_ BCM_usrData3 : 47|8@0+ (1,0) [0|255] ""  APM,CCU_F,CCU_R,ETG,LDM_L,LDM_R,PSM_D,TRM,XGW_Body
 SG_ BCM_usrData4 : 55|8@0+ (1,0) [0|255] ""  APM,CCU_F,CCU_R,ETG,LDM_L,LDM_R,PSM_D,TRM,XGW_Body
 SG_ BCM_usrData5 : 63|8@0+ (1,0) [0|255] ""  APM,CCU_F,CCU_R,ETG,LDM_L,LDM_R,PSM_D,TRM,XGW_Body

BO_ 1282 XGW_NM: 8 XGW_Body
 SG_ XGW_srcNodeID : 7|8@0+ (1,0) [0|255] ""  APM,ASU_Gateway,BCM,CCU_F,CCU_R,ETG,LDM_L,LDM_R,PSM_D,TRM
 SG_ XGW_CtrlBitVector : 15|8@0+ (1,0) [0|255] ""  APM,ASU_Gateway,BCM,CCU_F,CCU_R,ETG,LDM_L,LDM_R,PSM_D,TRM
 SG_ XGW_usrData0 : 23|8@0+ (1,0) [0|255] ""  APM,ASU_Gateway,BCM,CCU_F,CCU_R,ETG,LDM_L,LDM_R,PSM_D,TRM
 SG_ XGW_usrData1 : 31|8@0+ (1,0) [0|255] ""  APM,ASU_Gateway,BCM,CCU_F,CCU_R,ETG,LDM_L,LDM_R,PSM_D,TRM
 SG_ XGW_usrData2 : 39|8@0+ (1,0) [0|255] ""  APM,ASU_Gateway,BCM,CCU_F,CCU_R,ETG,LDM_L,LDM_R,PSM_D,TRM
 SG_ XGW_usrData3 : 47|8@0+ (1,0) [0|255] ""  APM,ASU_Gateway,BCM,CCU_F,CCU_R,ETG,LDM_L,LDM_R,PSM_D,TRM
 SG_ XGW_usrData4 : 55|8@0+ (1,0) [0|255] ""  APM,ASU_Gateway,BCM,CCU_F,CCU_R,ETG,LDM_L,LDM_R,PSM_D,TRM
 SG_ XGW_usrData5 : 63|8@0+ (1,0) [0|255] ""  APM,ASU_Gateway,BCM,CCU_F,CCU_R,ETG,LDM_L,LDM_R,PSM_D,TRM

BO_ 1289 CCUF_NM: 8 CCU_F
 SG_ CCUF_srcNodeID : 7|8@0+ (1,0) [0|255] ""  APM,BCM,CCU_R,ETG,LDM_L,LDM_R,PSM_D,TRM,XGW_Body
 SG_ CCUF_CtrlBitVector : 15|8@0+ (1,0) [0|255] ""  APM,BCM,CCU_R,ETG,LDM_L,LDM_R,PSM_D,TRM,XGW_Body
 SG_ CCUF_usrData0 : 23|8@0+ (1,0) [0|255] ""  APM,BCM,CCU_R,ETG,LDM_L,LDM_R,PSM_D,TRM,XGW_Body
 SG_ CCUF_usrData1 : 31|8@0+ (1,0) [0|255] ""  APM,BCM,CCU_R,ETG,LDM_L,LDM_R,PSM_D,TRM,XGW_Body
 SG_ CCUF_usrData2 : 39|8@0+ (1,0) [0|255] ""  APM,BCM,CCU_R,ETG,LDM_L,LDM_R,PSM_D,TRM,XGW_Body
 SG_ CCUF_usrData3 : 47|8@0+ (1,0) [0|255] ""  APM,BCM,CCU_R,ETG,LDM_L,LDM_R,PSM_D,TRM,XGW_Body
 SG_ CCUF_usrData4 : 55|8@0+ (1,0) [0|255] ""  APM,BCM,CCU_R,ETG,LDM_L,LDM_R,PSM_D,TRM,XGW_Body
 SG_ CCUF_usrData5 : 63|8@0+ (1,0) [0|255] ""  APM,BCM,CCU_R,ETG,LDM_L,LDM_R,PSM_D,TRM,XGW_Body

BO_ 1294 ETG_NM: 8 ETG
 SG_ ETG_srcNodeID : 7|8@0+ (1,0) [0|255] ""  APM,BCM,CCU_F,CCU_R,LDM_L,LDM_R,PSM_D,TRM,XGW_Body
 SG_ ETG_CtrlBitVector : 15|8@0+ (1,0) [0|255] ""  APM,BCM,CCU_F,CCU_R,LDM_L,LDM_R,PSM_D,TRM,XGW_Body
 SG_ ETG_usrData0 : 23|8@0+ (1,0) [0|255] ""  APM,BCM,CCU_F,CCU_R,LDM_L,LDM_R,PSM_D,TRM,XGW_Body
 SG_ ETG_usrData1 : 31|8@0+ (1,0) [0|255] ""  APM,BCM,CCU_F,CCU_R,LDM_L,LDM_R,PSM_D,TRM,XGW_Body
 SG_ ETG_usrData2 : 39|8@0+ (1,0) [0|255] ""  APM,BCM,CCU_F,CCU_R,LDM_L,LDM_R,PSM_D,TRM,XGW_Body
 SG_ ETG_usrData3 : 47|8@0+ (1,0) [0|255] ""  APM,BCM,CCU_F,CCU_R,LDM_L,LDM_R,PSM_D,TRM,XGW_Body
 SG_ ETG_usrData4 : 55|8@0+ (1,0) [0|255] ""  APM,BCM,CCU_F,CCU_R,LDM_L,LDM_R,PSM_D,TRM,XGW_Body
 SG_ ETG_usrData5 : 63|8@0+ (1,0) [0|255] ""  APM,BCM,CCU_F,CCU_R,LDM_L,LDM_R,PSM_D,TRM,XGW_Body

BO_ 1310 PSM_D_NM: 8 PSM_D
 SG_ PSM_D_srcNodeID : 7|8@0+ (1,0) [0|255] ""  APM,BCM,CCU_F,CCU_R,ETG,LDM_L,LDM_R,TRM,XGW_Body
 SG_ PSM_D_CtrlBitVector : 15|8@0+ (1,0) [0|255] ""  APM,BCM,CCU_F,CCU_R,ETG,LDM_L,LDM_R,TRM,XGW_Body
 SG_ PSM_D_usrData0 : 23|8@0+ (1,0) [0|255] ""  APM,BCM,CCU_F,CCU_R,ETG,LDM_L,LDM_R,TRM,XGW_Body
 SG_ PSM_D_usrData1 : 31|8@0+ (1,0) [0|255] ""  APM,BCM,CCU_F,CCU_R,ETG,LDM_L,LDM_R,TRM,XGW_Body
 SG_ PSM_D_usrData2 : 39|8@0+ (1,0) [0|255] ""  APM,BCM,CCU_F,CCU_R,ETG,LDM_L,LDM_R,TRM,XGW_Body
 SG_ PSM_D_usrData3 : 47|8@0+ (1,0) [0|255] ""  APM,BCM,CCU_F,CCU_R,ETG,LDM_L,LDM_R,TRM,XGW_Body
 SG_ PSM_D_usrData4 : 55|8@0+ (1,0) [0|255] ""  APM,BCM,CCU_F,CCU_R,ETG,LDM_L,LDM_R,TRM,XGW_Body
 SG_ PSM_D_usrData5 : 63|8@0+ (1,0) [0|255] ""  APM,BCM,CCU_F,CCU_R,ETG,LDM_L,LDM_R,TRM,XGW_Body

BO_ 1339 TRM_NM: 8 TRM
SG_ TRM_srcNodeID : 7|8@0+ (1,0) [0|255] ""  LDM_R,LDM_L,XGW_Body,BCM,ETG,APM,CCU_F,PSM_D,CCU_R
SG_ TRM_CtrlBitVector : 15|8@0+ (1,0) [0|255] ""  LDM_R,LDM_L,XGW_Body,BCM,ETG,APM,CCU_F,PSM_D,CCU_R
SG_ TRM_usrData0 : 23|8@0+ (1,0) [0|255] ""  LDM_R,LDM_L,XGW_Body,BCM,ETG,APM,CCU_F,PSM_D,CCU_R
SG_ TRM_usrData1 : 31|8@0+ (1,0) [0|255] ""  LDM_R,LDM_L,XGW_Body,BCM,ETG,APM,CCU_F,PSM_D,CCU_R
SG_ TRM_usrData2 : 39|8@0+ (1,0) [0|255] ""  LDM_R,LDM_L,XGW_Body,BCM,ETG,APM,CCU_F,PSM_D,CCU_R
SG_ TRM_usrData3 : 47|8@0+ (1,0) [0|255] ""  LDM_R,LDM_L,XGW_Body,BCM,ETG,APM,CCU_F,PSM_D,CCU_R
SG_ TRM_usrData4 : 55|8@0+ (1,0) [0|255] ""  LDM_R,LDM_L,XGW_Body,BCM,ETG,APM,CCU_F,PSM_D,CCU_R
SG_ TRM_usrData5 : 63|8@0+ (1,0) [0|255] ""  LDM_R,LDM_L,XGW_Body,BCM,ETG,APM,CCU_F,PSM_D,CCU_R

BO_ 1344 ADAS_NM: 8 ADAS_Body
 SG_ ADAS_srcNodeID : 7|8@0+ (1,0) [0|255] ""  ACM,APM,BCM,BCM_BPM,CCU_F,CCU_R,ETG,LDM_L,LDM_R,OCS_P,PSM_D,SHVU_F,SHVU_R,TRM,XGW_Body
 SG_ ADAS_CtrlBitVector : 15|8@0+ (1,0) [0|255] "-"  ACM,APM,BCM,BCM_BPM,CCU_F,CCU_R,ETG,LDM_L,LDM_R,OCS_P,PSM_D,SHVU_F,SHVU_R,TRM,XGW_Body
 SG_ ADAS_usrData0 : 23|8@0+ (1,0) [0|255] ""  ACM,APM,BCM,BCM_BPM,CCU_F,CCU_R,ETG,LDM_L,LDM_R,OCS_P,PSM_D,SHVU_F,SHVU_R,TRM,XGW_Body
 SG_ ADAS_usrData1 : 31|8@0+ (1,0) [0|255] ""  ACM,APM,BCM,BCM_BPM,CCU_F,CCU_R,ETG,LDM_L,LDM_R,OCS_P,PSM_D,SHVU_F,SHVU_R,TRM,XGW_Body
 SG_ ADAS_usrData2 : 39|8@0+ (1,0) [0|255] ""  ACM,APM,BCM,BCM_BPM,CCU_F,CCU_R,ETG,LDM_L,LDM_R,OCS_P,PSM_D,SHVU_F,SHVU_R,TRM,XGW_Body
 SG_ ADAS_usrData3 : 47|8@0+ (1,0) [0|255] "-"  ACM,APM,BCM,BCM_BPM,CCU_F,CCU_R,ETG,LDM_L,LDM_R,OCS_P,PSM_D,SHVU_F,SHVU_R,TRM,XGW_Body
 SG_ ADAS_usrData4 : 55|8@0+ (1,0) [0|255] "-"  ACM,APM,BCM,BCM_BPM,CCU_F,CCU_R,ETG,LDM_L,LDM_R,OCS_P,PSM_D,SHVU_F,SHVU_R,TRM,XGW_Body
 SG_ ADAS_usrData5 : 63|8@0+ (1,0) [0|255] "-"  ACM,APM,BCM,BCM_BPM,CCU_F,CCU_R,ETG,LDM_L,LDM_R,OCS_P,PSM_D,SHVU_F,SHVU_R,TRM,XGW_Body

BO_ 1345 APM_NM: 8 APM
 SG_ APM_srcNodeID : 7|8@0+ (1,0) [0|255] ""  BCM,CCU_F,CCU_R,ETG,LDM_L,LDM_R,PSM_D,TRM,XGW_Body
 SG_ APM_CtrlBitVector : 15|8@0+ (1,0) [0|255] ""  BCM,CCU_F,CCU_R,ETG,LDM_L,LDM_R,PSM_D,TRM,XGW_Body
 SG_ APM_usrData0 : 23|8@0+ (1,0) [0|255] ""  BCM,CCU_F,CCU_R,ETG,LDM_L,LDM_R,PSM_D,TRM,XGW_Body
 SG_ APM_usrData1 : 31|8@0+ (1,0) [0|255] ""  BCM,CCU_F,CCU_R,ETG,LDM_L,LDM_R,PSM_D,TRM,XGW_Body
 SG_ APM_usrData2 : 39|8@0+ (1,0) [0|255] ""  BCM,CCU_F,CCU_R,ETG,LDM_L,LDM_R,PSM_D,TRM,XGW_Body
 SG_ APM_usrData3 : 47|8@0+ (1,0) [0|255] ""  BCM,CCU_F,CCU_R,ETG,LDM_L,LDM_R,PSM_D,TRM,XGW_Body
 SG_ APM_usrData4 : 55|8@0+ (1,0) [0|255] ""  BCM,CCU_F,CCU_R,ETG,LDM_L,LDM_R,PSM_D,TRM,XGW_Body
 SG_ APM_usrData5 : 63|8@0+ (1,0) [0|255] ""  BCM,CCU_F,CCU_R,ETG,LDM_L,LDM_R,PSM_D,TRM,XGW_Body

BO_ 1353 LDM_L_NM: 8 LDM_L
 SG_ LDM_L_srcNodeID : 7|8@0+ (1,0) [0|255] ""  APM,BCM,CCU_F,CCU_R,ETG,PSM_D,TRM,XGW_Body
 SG_ LDM_L_CtrlBitVector : 15|8@0+ (1,0) [0|255] ""  APM,BCM,CCU_F,CCU_R,ETG,PSM_D,TRM,XGW_Body
 SG_ LDM_L_usrData0 : 23|8@0+ (1,0) [0|255] ""  APM,BCM,CCU_F,CCU_R,ETG,PSM_D,TRM,XGW_Body
 SG_ LDM_L_usrData1 : 31|8@0+ (1,0) [0|255] ""  APM,BCM,CCU_F,CCU_R,ETG,PSM_D,TRM,XGW_Body
 SG_ LDM_L_usrData2 : 39|8@0+ (1,0) [0|255] ""  APM,BCM,CCU_F,CCU_R,ETG,PSM_D,TRM,XGW_Body
 SG_ LDM_L_usrData3 : 47|8@0+ (1,0) [0|255] ""  APM,BCM,CCU_F,CCU_R,ETG,PSM_D,TRM,XGW_Body
 SG_ LDM_L_usrData4 : 55|8@0+ (1,0) [0|255] ""  APM,BCM,CCU_F,CCU_R,ETG,PSM_D,TRM,XGW_Body
 SG_ LDM_L_usrData5 : 63|8@0+ (1,0) [0|255] ""  APM,BCM,CCU_F,CCU_R,ETG,PSM_D,TRM,XGW_Body

BO_ 1354 LDM_R_NM: 8 LDM_R
 SG_ LDM_R_srcNodeID : 7|8@0+ (1,0) [0|255] ""  APM,BCM,CCU_F,CCU_R,ETG,LDM_L,PSM_D,TRM,XGW_Body
 SG_ LDM_R_CtrlBitVector : 15|8@0+ (1,0) [0|255] ""  APM,BCM,CCU_F,CCU_R,ETG,LDM_L,PSM_D,TRM,XGW_Body
 SG_ LDM_R_usrData0 : 23|8@0+ (1,0) [0|255] ""  APM,BCM,CCU_F,CCU_R,ETG,LDM_L,PSM_D,TRM,XGW_Body
 SG_ LDM_R_usrData1 : 31|8@0+ (1,0) [0|255] ""  APM,BCM,CCU_F,CCU_R,ETG,LDM_L,PSM_D,TRM,XGW_Body
 SG_ LDM_R_usrData2 : 39|8@0+ (1,0) [0|255] ""  APM,BCM,CCU_F,CCU_R,ETG,LDM_L,PSM_D,TRM,XGW_Body
 SG_ LDM_R_usrData3 : 47|8@0+ (1,0) [0|255] ""  APM,BCM,CCU_F,CCU_R,ETG,LDM_L,PSM_D,TRM,XGW_Body
 SG_ LDM_R_usrData4 : 55|8@0+ (1,0) [0|255] ""  APM,BCM,CCU_F,CCU_R,ETG,LDM_L,PSM_D,TRM,XGW_Body
 SG_ LDM_R_usrData5 : 63|8@0+ (1,0) [0|255] ""  APM,BCM,CCU_F,CCU_R,ETG,LDM_L,PSM_D,TRM,XGW_Body

BO_ 1360 CCUR_NM: 8 CCU_R
 SG_ CCUR_srcNodeID : 7|8@0+ (1,0) [0|255] ""  APM,BCM,CCU_F,ETG,LDM_L,LDM_R,PSM_D,TRM,XGW_Body
 SG_ CCUR_CtrlBitVector : 15|8@0+ (1,0) [0|255] ""  APM,BCM,CCU_F,ETG,LDM_L,LDM_R,PSM_D,TRM,XGW_Body
 SG_ CCUR_usrData0 : 23|8@0+ (1,0) [0|255] ""  APM,BCM,CCU_F,ETG,LDM_L,LDM_R,PSM_D,TRM,XGW_Body
 SG_ CCUR_usrData1 : 31|8@0+ (1,0) [0|255] ""  APM,BCM,CCU_F,ETG,LDM_L,LDM_R,PSM_D,TRM,XGW_Body
 SG_ CCUR_usrData2 : 39|8@0+ (1,0) [0|255] ""  APM,BCM,CCU_F,ETG,LDM_L,LDM_R,PSM_D,TRM,XGW_Body
 SG_ CCUR_usrData3 : 47|8@0+ (1,0) [0|255] ""  APM,BCM,CCU_F,ETG,LDM_L,LDM_R,PSM_D,TRM,XGW_Body
 SG_ CCUR_usrData4 : 55|8@0+ (1,0) [0|255] ""  APM,BCM,CCU_F,ETG,LDM_L,LDM_R,PSM_D,TRM,XGW_Body
 SG_ CCUR_usrData5 : 63|8@0+ (1,0) [0|255] ""  APM,BCM,CCU_F,ETG,LDM_L,LDM_R,PSM_D,TRM,XGW_Body

BO_ 1537 BCM_DiagResp: 8 BCM
 SG_ BCM_DiagRespData0 : 7|8@0+ (1,0) [0|255] ""  XGW_Body
 SG_ BCM_DiagRespData1 : 15|8@0+ (1,0) [0|255] "-"  XGW_Body
 SG_ BCM_DiagRespData2 : 23|8@0+ (1,0) [0|255] ""  XGW_Body
 SG_ BCM_DiagRespData3 : 31|8@0+ (1,0) [0|255] ""  XGW_Body
 SG_ BCM_DiagRespData4 : 39|8@0+ (1,0) [0|255] ""  XGW_Body
 SG_ BCM_DiagRespData5 : 47|8@0+ (1,0) [0|255] ""  XGW_Body
 SG_ BCM_DiagRespData6 : 55|8@0+ (1,0) [0|255] "-"  XGW_Body
 SG_ BCM_DiagRespData7 : 63|8@0+ (1,0) [0|255] ""  XGW_Body

BO_ 1544 ACM_DiagResp: 8 ACM
 SG_ ACM_DiagRespData0 : 7|8@0+ (1,0) [0|255] ""  XGW_Body
 SG_ ACM_DiagRespData1 : 15|8@0+ (1,0) [0|255] "-"  XGW_Body
 SG_ ACM_DiagRespData2 : 23|8@0+ (1,0) [0|255] ""  XGW_Body
 SG_ ACM_DiagRespData3 : 31|8@0+ (1,0) [0|255] "-"  XGW_Body
 SG_ ACM_DiagRespData4 : 39|8@0+ (1,0) [0|255] ""  XGW_Body
 SG_ ACM_DiagRespData5 : 47|8@0+ (1,0) [0|255] "-"  XGW_Body
 SG_ ACM_DiagRespData6 : 55|8@0+ (1,0) [0|255] ""  XGW_Body
 SG_ ACM_DiagRespData7 : 63|8@0+ (1,0) [0|255] "-"  XGW_Body

BO_ 1545 CCUF_DiagResp: 8 CCU_F
 SG_ CCUF_DiagRespData0 : 7|8@0+ (1,0) [0|255] ""  XGW_Body
 SG_ CCUF_DiagRespData1 : 15|8@0+ (1,0) [0|255] "-"  XGW_Body
 SG_ CCUF_DiagRespData2 : 23|8@0+ (1,0) [0|255] "-"  XGW_Body
 SG_ CCUF_DiagRespData3 : 31|8@0+ (1,0) [0|255] ""  XGW_Body
 SG_ CCUF_DiagRespData4 : 39|8@0+ (1,0) [0|255] ""  XGW_Body
 SG_ CCUF_DiagRespData5 : 47|8@0+ (1,0) [0|255] "-"  XGW_Body
 SG_ CCUF_DiagRespData6 : 55|8@0+ (1,0) [0|255] "-"  XGW_Body
 SG_ CCUF_DiagRespData7 : 63|8@0+ (1,0) [0|255] ""  XGW_Body

BO_ 1550 ETG_DiagResp: 8 ETG
 SG_ ETG_DiagRespData0 : 7|8@0+ (1,0) [0|255] ""  XGW_Body
 SG_ ETG_DiagRespData1 : 15|8@0+ (1,0) [0|255] ""  XGW_Body
 SG_ ETG_DiagRespData2 : 23|8@0+ (1,0) [0|255] ""  XGW_Body
 SG_ ETG_DiagRespData3 : 31|8@0+ (1,0) [0|255] "-"  XGW_Body
 SG_ ETG_DiagRespData4 : 39|8@0+ (1,0) [0|255] ""  XGW_Body
 SG_ ETG_DiagRespData5 : 47|8@0+ (1,0) [0|255] ""  XGW_Body
 SG_ ETG_DiagRespData6 : 55|8@0+ (1,0) [0|255] ""  XGW_Body
 SG_ ETG_DiagRespData7 : 63|8@0+ (1,0) [0|255] ""  XGW_Body

BO_ 1553 ASU_Gateway_DiagResp: 8 ASU_Gateway
 SG_ ASU_Gateway_DiagRespData0 : 7|8@0+ (1,0) [0|255] "-"  XGW_Body
 SG_ ASU_Gateway_DiagRespData1 : 15|8@0+ (1,0) [0|255] "-"  XGW_Body
 SG_ ASU_Gateway_DiagRespData2 : 23|8@0+ (1,0) [0|255] "-"  XGW_Body
 SG_ ASU_Gateway_DiagRespData3 : 31|8@0+ (1,0) [0|255] "-"  XGW_Body
 SG_ ASU_Gateway_DiagRespData4 : 39|8@0+ (1,0) [0|255] "-"  XGW_Body
 SG_ ASU_Gateway_DiagRespData5 : 47|8@0+ (1,0) [0|255] "-"  XGW_Body
 SG_ ASU_Gateway_DiagRespData6 : 55|8@0+ (1,0) [0|255] "-"  XGW_Body
 SG_ ASU_Gateway_DiagRespData7 : 63|8@0+ (1,0) [0|255] "-"  XGW_Body

BO_ 1556 CCUR_DiagResp: 8 CCU_R
 SG_ CCUR_DiagRespData0 : 7|8@0+ (1,0) [0|255] ""  XGW_Body
 SG_ CCUR_DiagRespData1 : 15|8@0+ (1,0) [0|255] ""  XGW_Body
 SG_ CCUR_DiagRespData2 : 23|8@0+ (1,0) [0|255] ""  XGW_Body
 SG_ CCUR_DiagRespData3 : 31|8@0+ (1,0) [0|255] ""  XGW_Body
 SG_ CCUR_DiagRespData4 : 39|8@0+ (1,0) [0|255] "-"  XGW_Body
 SG_ CCUR_DiagRespData5 : 47|8@0+ (1,0) [0|255] ""  XGW_Body
 SG_ CCUR_DiagRespData6 : 55|8@0+ (1,0) [0|255] "-"  XGW_Body
 SG_ CCUR_DiagRespData7 : 63|8@0+ (1,0) [0|255] ""  XGW_Body

BO_ 1566 PSM_D_DiagResp: 8 PSM_D
 SG_ PSM_D_DiagRespData0 : 7|8@0+ (1,0) [0|255] ""  XGW_Body
 SG_ PSM_D_DiagRespData1 : 15|8@0+ (1,0) [0|255] ""  XGW_Body
 SG_ PSM_D_DiagRespData2 : 23|8@0+ (1,0) [0|255] ""  XGW_Body
 SG_ PSM_D_DiagRespData3 : 31|8@0+ (1,0) [0|255] "-"  XGW_Body
 SG_ PSM_D_DiagRespData4 : 39|8@0+ (1,0) [0|255] ""  XGW_Body
 SG_ PSM_D_DiagRespData5 : 47|8@0+ (1,0) [0|255] ""  XGW_Body
 SG_ PSM_D_DiagRespData6 : 55|8@0+ (1,0) [0|255] ""  XGW_Body
 SG_ PSM_D_DiagRespData7 : 63|8@0+ (1,0) [0|255] ""  XGW_Body

BO_ 1592 ASU_DiagResp: 8 ASU_Gateway
 SG_ ASU_DiagRespData0 : 7|8@0+ (1,0) [0|255] "-"  XGW_Body
 SG_ ASU_DiagRespData1 : 15|8@0+ (1,0) [0|255] "-"  XGW_Body
 SG_ ASU_DiagRespData2 : 23|8@0+ (1,0) [0|255] "-"  XGW_Body
 SG_ ASU_DiagRespData3 : 31|8@0+ (1,0) [0|255] "-"  XGW_Body
 SG_ ASU_DiagRespData4 : 39|8@0+ (1,0) [0|255] "-"  XGW_Body
 SG_ ASU_DiagRespData5 : 47|8@0+ (1,0) [0|255] "-"  XGW_Body
 SG_ ASU_DiagRespData6 : 55|8@0+ (1,0) [0|255] "-"  XGW_Body
 SG_ ASU_DiagRespData7 : 63|8@0+ (1,0) [0|255] "-"  XGW_Body

BO_ 1595 TRM_DiagResp: 8 TRM
 SG_ TRM_DiagRespData0 : 7|8@0+ (1,0) [0|255] ""  XGW_Body
 SG_ TRM_DiagRespData1 : 15|8@0+ (1,0) [0|255] ""  XGW_Body
 SG_ TRM_DiagRespData2 : 23|8@0+ (1,0) [0|255] ""  XGW_Body
 SG_ TRM_DiagRespData3 : 31|8@0+ (1,0) [0|255] "-"  XGW_Body
 SG_ TRM_DiagRespData4 : 39|8@0+ (1,0) [0|255] "-"  XGW_Body
 SG_ TRM_DiagRespData5 : 47|8@0+ (1,0) [0|255] "-"  XGW_Body
 SG_ TRM_DiagRespData6 : 55|8@0+ (1,0) [0|255] ""  XGW_Body
 SG_ TRM_DiagRespData7 : 63|8@0+ (1,0) [0|255] "-"  XGW_Body

BO_ 1601 APM_DiagResp: 8 APM
 SG_ APM_DiagRespData0 : 7|8@0+ (1,0) [0|255] ""  XGW_Body
 SG_ APM_DiagRespData1 : 15|8@0+ (1,0) [0|255] ""  XGW_Body
 SG_ APM_DiagRespData2 : 23|8@0+ (1,0) [0|255] ""  XGW_Body
 SG_ APM_DiagRespData3 : 31|8@0+ (1,0) [0|255] ""  XGW_Body
 SG_ APM_DiagRespData4 : 39|8@0+ (1,0) [0|255] "-"  XGW_Body
 SG_ APM_DiagRespData5 : 47|8@0+ (1,0) [0|255] ""  XGW_Body
 SG_ APM_DiagRespData6 : 55|8@0+ (1,0) [0|255] "-"  XGW_Body
 SG_ APM_DiagRespData7 : 63|8@0+ (1,0) [0|255] ""  XGW_Body

BO_ 1602 SHVU_F_DiagResp: 8 SHVU_F
 SG_ SHVU_F_DiagRespData0 : 7|8@0+ (1,0) [0|255] ""  XGW_Body
 SG_ SHVU_F_DiagRespData1 : 15|8@0+ (1,0) [0|255] ""  XGW_Body
 SG_ SHVU_F_DiagRespData2 : 23|8@0+ (1,0) [0|255] "-"  XGW_Body
 SG_ SHVU_F_DiagRespData3 : 31|8@0+ (1,0) [0|255] ""  XGW_Body
 SG_ SHVU_F_DiagRespData4 : 39|8@0+ (1,0) [0|255] ""  XGW_Body
 SG_ SHVU_F_DiagRespData5 : 47|8@0+ (1,0) [0|255] ""  XGW_Body
 SG_ SHVU_F_DiagRespData6 : 55|8@0+ (1,0) [0|255] "-"  XGW_Body
 SG_ SHVU_F_DiagRespData7 : 63|8@0+ (1,0) [0|255] ""  XGW_Body

BO_ 1603 SHVU_R_DiagResp: 8 SHVU_R
 SG_ SHVU_R_DiagRespData0 : 7|8@0+ (1,0) [0|255] ""  XGW_Body
 SG_ SHVU_R_DiagRespData1 : 15|8@0+ (1,0) [0|255] "-"  XGW_Body
 SG_ SHVU_R_DiagRespData2 : 23|8@0+ (1,0) [0|255] ""  XGW_Body
 SG_ SHVU_R_DiagRespData3 : 31|8@0+ (1,0) [0|255] "-"  XGW_Body
 SG_ SHVU_R_DiagRespData4 : 39|8@0+ (1,0) [0|255] "-"  XGW_Body
 SG_ SHVU_R_DiagRespData5 : 47|8@0+ (1,0) [0|255] ""  XGW_Body
 SG_ SHVU_R_DiagRespData6 : 55|8@0+ (1,0) [0|255] "-"  XGW_Body
 SG_ SHVU_R_DiagRespData7 : 63|8@0+ (1,0) [0|255] ""  XGW_Body

BO_ 1604 OCS_P_DiagResp: 8 OCS_P
 SG_ OCS_P_DiagRespData0 : 7|8@0+ (1,0) [0|255] ""  XGW_Body
 SG_ OCS_P_DiagRespData1 : 15|8@0+ (1,0) [0|255] "-"  XGW_Body
 SG_ OCS_P_DiagRespData2 : 23|8@0+ (1,0) [0|255] ""  XGW_Body
 SG_ OCS_P_DiagRespData3 : 31|8@0+ (1,0) [0|255] "-"  XGW_Body
 SG_ OCS_P_DiagRespData4 : 39|8@0+ (1,0) [0|255] ""  XGW_Body
 SG_ OCS_P_DiagRespData5 : 47|8@0+ (1,0) [0|255] ""  XGW_Body
 SG_ OCS_P_DiagRespData6 : 55|8@0+ (1,0) [0|255] ""  XGW_Body
 SG_ OCS_P_DiagRespData7 : 63|8@0+ (1,0) [0|255] ""  XGW_Body

BO_ 1609 LDM_L_DiagResp: 8 LDM_L
 SG_ LDM_L_DiagRespData0 : 7|8@0+ (1,0) [0|255] "-"  XGW_Body
 SG_ LDM_L_DiagRespData1 : 15|8@0+ (1,0) [0|255] ""  XGW_Body
 SG_ LDM_L_DiagRespData2 : 23|8@0+ (1,0) [0|255] "-"  XGW_Body
 SG_ LDM_L_DiagRespData3 : 31|8@0+ (1,0) [0|255] ""  XGW_Body
 SG_ LDM_L_DiagRespData4 : 39|8@0+ (1,0) [0|255] ""  XGW_Body
 SG_ LDM_L_DiagRespData5 : 47|8@0+ (1,0) [0|255] "-"  XGW_Body
 SG_ LDM_L_DiagRespData6 : 55|8@0+ (1,0) [0|255] ""  XGW_Body
 SG_ LDM_L_DiagRespData7 : 63|8@0+ (1,0) [0|255] "-"  XGW_Body

BO_ 1610 LDM_R_DiagResp: 8 LDM_R
 SG_ LDM_R_DiagRespData0 : 7|8@0+ (1,0) [0|255] ""  XGW_Body
 SG_ LDM_R_DiagRespData1 : 15|8@0+ (1,0) [0|255] "-"  XGW_Body
 SG_ LDM_R_DiagRespData2 : 23|8@0+ (1,0) [0|255] ""  XGW_Body
 SG_ LDM_R_DiagRespData3 : 31|8@0+ (1,0) [0|255] ""  XGW_Body
 SG_ LDM_R_DiagRespData4 : 39|8@0+ (1,0) [0|255] "-"  XGW_Body
 SG_ LDM_R_DiagRespData5 : 47|8@0+ (1,0) [0|255] ""  XGW_Body
 SG_ LDM_R_DiagRespData6 : 55|8@0+ (1,0) [0|255] ""  XGW_Body
 SG_ LDM_R_DiagRespData7 : 63|8@0+ (1,0) [0|255] "-"  XGW_Body

BO_ 1624 BAS_DiagResp: 8 BCM
 SG_ BAS_DiagRespData0 : 7|8@0+ (1,0) [0|255] ""  XGW_Body
 SG_ BAS_DiagRespData1 : 15|8@0+ (1,0) [0|255] ""  XGW_Body
 SG_ BAS_DiagRespData2 : 23|8@0+ (1,0) [0|255] ""  XGW_Body
 SG_ BAS_DiagRespData3 : 31|8@0+ (1,0) [0|255] ""  XGW_Body
 SG_ BAS_DiagRespData4 : 39|8@0+ (1,0) [0|255] ""  XGW_Body
 SG_ BAS_DiagRespData5 : 47|8@0+ (1,0) [0|255] ""  XGW_Body
 SG_ BAS_DiagRespData6 : 55|8@0+ (1,0) [0|255] ""  XGW_Body
 SG_ BAS_DiagRespData7 : 63|8@0+ (1,0) [0|255] ""  XGW_Body

BO_ 1636 DCM_APM_DiagResp: 8 APM
 SG_ DCM_APM_DiagRespData0 : 7|8@0+ (1,0) [0|255] "-"  XGW_Body
 SG_ DCM_APM_DiagRespData1 : 15|8@0+ (1,0) [0|255] "-"  XGW_Body
 SG_ DCM_APM_DiagRespData2 : 23|8@0+ (1,0) [0|255] ""  XGW_Body
 SG_ DCM_APM_DiagRespData3 : 31|8@0+ (1,0) [0|255] "-"  XGW_Body
 SG_ DCM_APM_DiagRespData4 : 39|8@0+ (1,0) [0|255] ""  XGW_Body
 SG_ DCM_APM_DiagRespData5 : 47|8@0+ (1,0) [0|255] "-"  XGW_Body
 SG_ DCM_APM_DiagRespData6 : 55|8@0+ (1,0) [0|255] "-"  XGW_Body
 SG_ DCM_APM_DiagRespData7 : 63|8@0+ (1,0) [0|255] ""  XGW_Body

BO_ 1659 BCM_BPM_DiagResp: 8 BCM
 SG_ BCM_BPM_DiagRespData0 : 7|8@0+ (1,0) [0|255] ""  XGW_Body
 SG_ BCM_BPM_DiagRespData1 : 15|8@0+ (1,0) [0|255] "-"  XGW_Body
 SG_ BCM_BPM_DiagRespData2 : 23|8@0+ (1,0) [0|255] ""  XGW_Body
 SG_ BCM_BPM_DiagRespData3 : 31|8@0+ (1,0) [0|255] ""  XGW_Body
 SG_ BCM_BPM_DiagRespData4 : 39|8@0+ (1,0) [0|255] "-"  XGW_Body
 SG_ BCM_BPM_DiagRespData5 : 47|8@0+ (1,0) [0|255] ""  XGW_Body
 SG_ BCM_BPM_DiagRespData6 : 55|8@0+ (1,0) [0|255] "-"  XGW_Body
 SG_ BCM_BPM_DiagRespData7 : 63|8@0+ (1,0) [0|255] ""  XGW_Body

BO_ 1665 BCM_DiagReq: 8 XGW_Body
 SG_ BCM_DiagReqData0 : 7|8@0+ (1,0) [0|255] ""  BCM
 SG_ BCM_DiagReqData1 : 15|8@0+ (1,0) [0|255] ""  BCM
 SG_ BCM_DiagReqData2 : 23|8@0+ (1,0) [0|255] ""  BCM
 SG_ BCM_DiagReqData3 : 31|8@0+ (1,0) [0|255] ""  BCM
 SG_ BCM_DiagReqData4 : 39|8@0+ (1,0) [0|255] ""  BCM
 SG_ BCM_DiagReqData5 : 47|8@0+ (1,0) [0|255] ""  BCM
 SG_ BCM_DiagReqData6 : 55|8@0+ (1,0) [0|255] "-"  BCM
 SG_ BCM_DiagReqData7 : 63|8@0+ (1,0) [0|255] "-"  BCM

BO_ 1672 ACM_DiagReq: 8 XGW_Body
 SG_ ACM_DiagReqData0 : 7|8@0+ (1,0) [0|255] ""  ACM
 SG_ ACM_DiagReqData1 : 15|8@0+ (1,0) [0|255] ""  ACM
 SG_ ACM_DiagReqData2 : 23|8@0+ (1,0) [0|255] ""  ACM
 SG_ ACM_DiagReqData3 : 31|8@0+ (1,0) [0|255] "-"  ACM
 SG_ ACM_DiagReqData4 : 39|8@0+ (1,0) [0|255] ""  ACM
 SG_ ACM_DiagReqData5 : 47|8@0+ (1,0) [0|255] ""  ACM
 SG_ ACM_DiagReqData6 : 55|8@0+ (1,0) [0|255] "-"  ACM
 SG_ ACM_DiagReqData7 : 63|8@0+ (1,0) [0|255] ""  ACM

BO_ 1673 CCUF_DiagReq: 8 XGW_Body
 SG_ CCUF_DiagReqData0 : 7|8@0+ (1,0) [0|255] "-"  CCU_F
 SG_ CCUF_DiagReqData1 : 15|8@0+ (1,0) [0|255] ""  CCU_F
 SG_ CCUF_DiagReqData2 : 23|8@0+ (1,0) [0|255] ""  CCU_F
 SG_ CCUF_DiagReqData3 : 31|8@0+ (1,0) [0|255] ""  CCU_F
 SG_ CCUF_DiagReqData4 : 39|8@0+ (1,0) [0|255] ""  CCU_F
 SG_ CCUF_DiagReqData5 : 47|8@0+ (1,0) [0|255] ""  CCU_F
 SG_ CCUF_DiagReqData6 : 55|8@0+ (1,0) [0|255] ""  CCU_F
 SG_ CCUF_DiagReqData7 : 63|8@0+ (1,0) [0|255] ""  CCU_F

BO_ 1678 ETG_DiagReq: 8 XGW_Body
 SG_ ETG_DiagReqData0 : 7|8@0+ (1,0) [0|255] ""  ETG
 SG_ ETG_DiagReqData1 : 15|8@0+ (1,0) [0|255] ""  ETG
 SG_ ETG_DiagReqData2 : 23|8@0+ (1,0) [0|255] ""  ETG
 SG_ ETG_DiagReqData3 : 31|8@0+ (1,0) [0|255] ""  ETG
 SG_ ETG_DiagReqData4 : 39|8@0+ (1,0) [0|255] ""  ETG
 SG_ ETG_DiagReqData5 : 47|8@0+ (1,0) [0|255] ""  ETG
 SG_ ETG_DiagReqData6 : 55|8@0+ (1,0) [0|255] ""  ETG
 SG_ ETG_DiagReqData7 : 63|8@0+ (1,0) [0|255] "-"  ETG

BO_ 1681 ASU_Gateway_DiagReq: 8 XGW_Body
 SG_ ASU_Gateway_DiagReqData0 : 7|8@0+ (1,0) [0|255] "-"  ASU_Gateway
 SG_ ASU_Gateway_DiagReqData1 : 15|8@0+ (1,0) [0|255] "-"  ASU_Gateway
 SG_ ASU_Gateway_DiagReqData2 : 23|8@0+ (1,0) [0|255] "-"  ASU_Gateway
 SG_ ASU_Gateway_DiagReqData3 : 31|8@0+ (1,0) [0|255] "-"  ASU_Gateway
 SG_ ASU_Gateway_DiagReqData4 : 39|8@0+ (1,0) [0|255] "-"  ASU_Gateway
 SG_ ASU_Gateway_DiagReqData5 : 47|8@0+ (1,0) [0|255] "-"  ASU_Gateway
 SG_ ASU_Gateway_DiagReqData6 : 55|8@0+ (1,0) [0|255] "-"  ASU_Gateway
 SG_ ASU_Gateway_DiagReqData7 : 63|8@0+ (1,0) [0|255] "-"  ASU_Gateway

BO_ 1684 CCUR_DiagReq: 8 XGW_Body
 SG_ CCUR_DiagReqData0 : 7|8@0+ (1,0) [0|255] ""  CCU_R
 SG_ CCUR_DiagReqData1 : 15|8@0+ (1,0) [0|255] ""  CCU_R
 SG_ CCUR_DiagReqData2 : 23|8@0+ (1,0) [0|255] ""  CCU_R
 SG_ CCUR_DiagReqData3 : 31|8@0+ (1,0) [0|255] "-"  CCU_R
 SG_ CCUR_DiagReqData4 : 39|8@0+ (1,0) [0|255] "-"  CCU_R
 SG_ CCUR_DiagReqData5 : 47|8@0+ (1,0) [0|255] ""  CCU_R
 SG_ CCUR_DiagReqData6 : 55|8@0+ (1,0) [0|255] ""  CCU_R
 SG_ CCUR_DiagReqData7 : 63|8@0+ (1,0) [0|255] ""  CCU_R

BO_ 1694 PSM_D_DiagReq: 8 XGW_Body
 SG_ PSM_D_DiagReqData0 : 7|8@0+ (1,0) [0|255] "-"  PSM_D
 SG_ PSM_D_DiagReqData1 : 15|8@0+ (1,0) [0|255] ""  PSM_D
 SG_ PSM_D_DiagReqData2 : 23|8@0+ (1,0) [0|255] "-"  PSM_D
 SG_ PSM_D_DiagReqData3 : 31|8@0+ (1,0) [0|255] ""  PSM_D
 SG_ PSM_D_DiagReqData4 : 39|8@0+ (1,0) [0|255] ""  PSM_D
 SG_ PSM_D_DiagReqData5 : 47|8@0+ (1,0) [0|255] "-"  PSM_D
 SG_ PSM_D_DiagReqData6 : 55|8@0+ (1,0) [0|255] "-"  PSM_D
 SG_ PSM_D_DiagReqData7 : 63|8@0+ (1,0) [0|255] ""  PSM_D

BO_ 1723 TRM_DiagReq: 8 XGW_Body
 SG_ TRM_DiagReqData0 : 7|8@0+ (1,0) [0|255] ""  TRM
 SG_ TRM_DiagReqData1 : 15|8@0+ (1,0) [0|255] ""  TRM
 SG_ TRM_DiagReqData2 : 23|8@0+ (1,0) [0|255] "-"  TRM
 SG_ TRM_DiagReqData3 : 31|8@0+ (1,0) [0|255] "-"  TRM
 SG_ TRM_DiagReqData4 : 39|8@0+ (1,0) [0|255] "-"  TRM
 SG_ TRM_DiagReqData5 : 47|8@0+ (1,0) [0|255] ""  TRM
 SG_ TRM_DiagReqData6 : 55|8@0+ (1,0) [0|255] ""  TRM
 SG_ TRM_DiagReqData7 : 63|8@0+ (1,0) [0|255] "-"  TRM

BO_ 1729 APM_DiagReq: 8 XGW_Body
 SG_ APM_DiagReqData0 : 7|8@0+ (1,0) [0|255] ""  APM
 SG_ APM_DiagReqData1 : 15|8@0+ (1,0) [0|255] ""  APM
 SG_ APM_DiagReqData2 : 23|8@0+ (1,0) [0|255] "-"  APM
 SG_ APM_DiagReqData3 : 31|8@0+ (1,0) [0|255] ""  APM
 SG_ APM_DiagReqData4 : 39|8@0+ (1,0) [0|255] ""  APM
 SG_ APM_DiagReqData5 : 47|8@0+ (1,0) [0|255] "-"  APM
 SG_ APM_DiagReqData6 : 55|8@0+ (1,0) [0|255] ""  APM
 SG_ APM_DiagReqData7 : 63|8@0+ (1,0) [0|255] ""  APM

BO_ 1730 SHVU_F_DiagReq: 8 XGW_Body
 SG_ SHVU_F_DiagReqData0 : 7|8@0+ (1,0) [0|255] ""  SHVU_F
 SG_ SHVU_F_DiagReqData1 : 15|8@0+ (1,0) [0|255] ""  SHVU_F
 SG_ SHVU_F_DiagReqData2 : 23|8@0+ (1,0) [0|255] ""  SHVU_F
 SG_ SHVU_F_DiagReqData3 : 31|8@0+ (1,0) [0|255] "-"  SHVU_F
 SG_ SHVU_F_DiagReqData4 : 39|8@0+ (1,0) [0|255] ""  SHVU_F
 SG_ SHVU_F_DiagReqData5 : 47|8@0+ (1,0) [0|255] ""  SHVU_F
 SG_ SHVU_F_DiagReqData6 : 55|8@0+ (1,0) [0|255] "-"  SHVU_F
 SG_ SHVU_F_DiagReqData7 : 63|8@0+ (1,0) [0|255] ""  SHVU_F

BO_ 1731 SHVU_R_DiagReq: 8 XGW_Body
 SG_ SHVU_R_DiagReqData0 : 7|8@0+ (1,0) [0|255] ""  SHVU_R
 SG_ SHVU_R_DiagReqData1 : 15|8@0+ (1,0) [0|255] ""  SHVU_R
 SG_ SHVU_R_DiagReqData2 : 23|8@0+ (1,0) [0|255] ""  SHVU_R
 SG_ SHVU_R_DiagReqData3 : 31|8@0+ (1,0) [0|255] ""  SHVU_R
 SG_ SHVU_R_DiagReqData4 : 39|8@0+ (1,0) [0|255] ""  SHVU_R
 SG_ SHVU_R_DiagReqData5 : 47|8@0+ (1,0) [0|255] "-"  SHVU_R
 SG_ SHVU_R_DiagReqData6 : 55|8@0+ (1,0) [0|255] ""  SHVU_R
 SG_ SHVU_R_DiagReqData7 : 63|8@0+ (1,0) [0|255] ""  SHVU_R

BO_ 1732 OCS_P_DiagReq: 8 XGW_Body
 SG_ OCS_P_DiagReqData0 : 7|8@0+ (1,0) [0|255] "-"  OCS_P
 SG_ OCS_P_DiagReqData1 : 15|8@0+ (1,0) [0|255] ""  OCS_P
 SG_ OCS_P_DiagReqData2 : 23|8@0+ (1,0) [0|255] ""  OCS_P
 SG_ OCS_P_DiagReqData3 : 31|8@0+ (1,0) [0|255] ""  OCS_P
 SG_ OCS_P_DiagReqData4 : 39|8@0+ (1,0) [0|255] ""  OCS_P
 SG_ OCS_P_DiagReqData5 : 47|8@0+ (1,0) [0|255] ""  OCS_P
 SG_ OCS_P_DiagReqData6 : 55|8@0+ (1,0) [0|255] ""  OCS_P
 SG_ OCS_P_DiagReqData7 : 63|8@0+ (1,0) [0|255] "-"  OCS_P

BO_ 1737 LDM_L_DiagReq: 8 XGW_Body
 SG_ LDM_L_DiagReqData0 : 7|8@0+ (1,0) [0|255] "-"  LDM_L
 SG_ LDM_L_DiagReqData1 : 15|8@0+ (1,0) [0|255] ""  LDM_L
 SG_ LDM_L_DiagReqData2 : 23|8@0+ (1,0) [0|255] ""  LDM_L
 SG_ LDM_L_DiagReqData3 : 31|8@0+ (1,0) [0|255] ""  LDM_L
 SG_ LDM_L_DiagReqData4 : 39|8@0+ (1,0) [0|255] "-"  LDM_L
 SG_ LDM_L_DiagReqData5 : 47|8@0+ (1,0) [0|255] ""  LDM_L
 SG_ LDM_L_DiagReqData6 : 55|8@0+ (1,0) [0|255] ""  LDM_L
 SG_ LDM_L_DiagReqData7 : 63|8@0+ (1,0) [0|255] ""  LDM_L

BO_ 1738 LDM_R_DiagReq: 8 XGW_Body
 SG_ LDM_R_DiagReqData0 : 7|8@0+ (1,0) [0|255] ""  LDM_R
 SG_ LDM_R_DiagReqData1 : 15|8@0+ (1,0) [0|255] ""  LDM_R
 SG_ LDM_R_DiagReqData2 : 23|8@0+ (1,0) [0|255] ""  LDM_R
 SG_ LDM_R_DiagReqData3 : 31|8@0+ (1,0) [0|255] "-"  LDM_R
 SG_ LDM_R_DiagReqData4 : 39|8@0+ (1,0) [0|255] ""  LDM_R
 SG_ LDM_R_DiagReqData5 : 47|8@0+ (1,0) [0|255] ""  LDM_R
 SG_ LDM_R_DiagReqData6 : 55|8@0+ (1,0) [0|255] "-"  LDM_R
 SG_ LDM_R_DiagReqData7 : 63|8@0+ (1,0) [0|255] "-"  LDM_R

BO_ 1752 BAS_DiagReq: 8 XGW_Body
 SG_ BAS_DiagReqData0 : 7|8@0+ (1,0) [0|255] ""  BCM
 SG_ BAS_DiagReqData1 : 15|8@0+ (1,0) [0|255] ""  BCM
 SG_ BAS_DiagReqData2 : 23|8@0+ (1,0) [0|255] ""  BCM
 SG_ BAS_DiagReqData3 : 31|8@0+ (1,0) [0|255] ""  BCM
 SG_ BAS_DiagReqData4 : 39|8@0+ (1,0) [0|255] ""  BCM
 SG_ BAS_DiagReqData5 : 47|8@0+ (1,0) [0|255] ""  BCM
 SG_ BAS_DiagReqData6 : 55|8@0+ (1,0) [0|255] ""  BCM
 SG_ BAS_DiagReqData7 : 63|8@0+ (1,0) [0|255] ""  BCM

BO_ 1764 DCM_APM_DiagReq: 8 XGW_Body
 SG_ DCM_APM_DiagReqData0 : 7|8@0+ (1,0) [0|255] "-"  APM,BCM
 SG_ DCM_APM_DiagReqData1 : 15|8@0+ (1,0) [0|255] "-"  APM
 SG_ DCM_APM_DiagReqData2 : 23|8@0+ (1,0) [0|255] "-"  APM
 SG_ DCM_APM_DiagReqData3 : 31|8@0+ (1,0) [0|255] "-"  APM
 SG_ DCM_APM_DiagReqData4 : 39|8@0+ (1,0) [0|255] ""  APM
 SG_ DCM_APM_DiagReqData5 : 47|8@0+ (1,0) [0|255] ""  APM
 SG_ DCM_APM_DiagReqData6 : 55|8@0+ (1,0) [0|255] ""  APM
 SG_ DCM_APM_DiagReqData7 : 63|8@0+ (1,0) [0|255] ""  APM

BO_ 1775 DIAG_Req_All_CAN: 8 XGW_Body
 SG_ DiagReqAllCANData0 : 7|8@0+ (1,0) [0|255] "-"  ACM,APM,ASU_Gateway,BCM,BCM_BPM,CCU_F,CCU_R,ETG,LDM_L,LDM_R,OCS_P,PSM_D,TRM
 SG_ DiagReqAllCANData1 : 15|8@0+ (1,0) [0|255] ""  ACM,APM,ASU_Gateway,BCM,BCM_BPM,CCU_F,CCU_R,ETG,LDM_L,LDM_R,OCS_P,PSM_D,TRM
 SG_ DiagReqAllCANData2 : 23|8@0+ (1,0) [0|255] "-"  ACM,APM,ASU_Gateway,BCM,BCM_BPM,CCU_F,CCU_R,ETG,LDM_L,LDM_R,OCS_P,PSM_D,TRM
 SG_ DiagReqAllCANData3 : 31|8@0+ (1,0) [0|255] "-"  ACM,APM,ASU_Gateway,BCM,BCM_BPM,CCU_F,CCU_R,ETG,LDM_L,LDM_R,OCS_P,PSM_D,TRM
 SG_ DiagReqAllCANData4 : 39|8@0+ (1,0) [0|255] ""  ACM,APM,ASU_Gateway,BCM,BCM_BPM,CCU_F,CCU_R,ETG,LDM_L,LDM_R,OCS_P,PSM_D,TRM
 SG_ DiagReqAllCANData5 : 47|8@0+ (1,0) [0|255] ""  ACM,APM,ASU_Gateway,BCM,BCM_BPM,CCU_F,CCU_R,ETG,LDM_L,LDM_R,OCS_P,PSM_D,TRM
 SG_ DiagReqAllCANData6 : 55|8@0+ (1,0) [0|255] ""  ACM,APM,ASU_Gateway,BCM,BCM_BPM,CCU_F,CCU_R,ETG,LDM_L,LDM_R,OCS_P,PSM_D,TRM
 SG_ DiagReqAllCANData7 : 63|8@0+ (1,0) [0|255] ""  ACM,APM,ASU_Gateway,BCM,BCM_BPM,CCU_F,CCU_R,ETG,LDM_L,LDM_R,OCS_P,PSM_D,TRM

BO_ 1777 ASU_DiagReq: 8 XGW_Body
 SG_ ASU_DiagReqData0 : 7|8@0+ (1,0) [0|255] "-"  ASU_Gateway
 SG_ ASU_DiagReqData1 : 15|8@0+ (1,0) [0|255] "-"  ASU_Gateway
 SG_ ASU_DiagReqData2 : 23|8@0+ (1,0) [0|255] "-"  ASU_Gateway
 SG_ ASU_DiagReqData3 : 31|8@0+ (1,0) [0|255] "-"  ASU_Gateway
 SG_ ASU_DiagReqData4 : 39|8@0+ (1,0) [0|255] "-"  ASU_Gateway
 SG_ ASU_DiagReqData5 : 47|8@0+ (1,0) [0|255] "-"  ASU_Gateway
 SG_ ASU_DiagReqData6 : 55|8@0+ (1,0) [0|255] "-"  ASU_Gateway
 SG_ ASU_DiagReqData7 : 63|8@0+ (1,0) [0|255] "-"  ASU_Gateway

BO_ 1787 BCM_BPM_DiagReq: 8 XGW_Body
 SG_ BCM_BPM_DiagReqData0 : 7|8@0+ (1,0) [0|255] "-"  DUMMY_BCM_BPM
 SG_ BCM_BPM_DiagReqData1 : 15|8@0+ (1,0) [0|255] ""  DUMMY_BCM_BPM
 SG_ BCM_BPM_DiagReqData2 : 23|8@0+ (1,0) [0|255] ""  DUMMY_BCM_BPM
 SG_ BCM_BPM_DiagReqData3 : 31|8@0+ (1,0) [0|255] ""  DUMMY_BCM_BPM
 SG_ BCM_BPM_DiagReqData4 : 39|8@0+ (1,0) [0|255] ""  DUMMY_BCM_BPM
 SG_ BCM_BPM_DiagReqData5 : 47|8@0+ (1,0) [0|255] ""  DUMMY_BCM_BPM
 SG_ BCM_BPM_DiagReqData6 : 55|8@0+ (1,0) [0|255] "-"  DUMMY_BCM_BPM
 SG_ BCM_BPM_DiagReqData7 : 63|8@0+ (1,0) [0|255] "-"  DUMMY_BCM_BPM

BO_ 1791 DIAG_Req_All_Ecu: 8 XGW_Body
 SG_ OBD_Func_DiagReqData0 : 7|8@0+ (1,0) [0|255] ""  ACM,APM,ASU_Gateway,BCM,BCM_BPM,CCU_F,CCU_R,ETG,LDM_L,LDM_R,OCS_P,PSM_D,SHVU_F,SHVU_R,TRM
 SG_ OBD_Func_DiagReqData1 : 15|8@0+ (1,0) [0|255] ""  ACM,APM,ASU_Gateway,BCM,BCM_BPM,CCU_F,CCU_R,ETG,LDM_L,LDM_R,OCS_P,PSM_D,SHVU_F,SHVU_R,TRM
 SG_ OBD_Func_DiagReqData2 : 23|8@0+ (1,0) [0|255] ""  ACM,APM,ASU_Gateway,BCM,BCM_BPM,CCU_F,CCU_R,ETG,LDM_L,LDM_R,OCS_P,PSM_D,SHVU_F,SHVU_R,TRM
 SG_ OBD_Func_DiagReqData3 : 31|8@0+ (1,0) [0|255] ""  ACM,APM,ASU_Gateway,BCM,BCM_BPM,CCU_F,CCU_R,ETG,LDM_L,LDM_R,OCS_P,PSM_D,SHVU_F,SHVU_R,TRM
 SG_ OBD_Func_DiagReqData4 : 39|8@0+ (1,0) [0|255] ""  ACM,APM,ASU_Gateway,BCM,BCM_BPM,CCU_F,CCU_R,ETG,LDM_L,LDM_R,OCS_P,PSM_D,SHVU_F,SHVU_R,TRM
 SG_ OBD_Func_DiagReqData5 : 47|8@0+ (1,0) [0|255] ""  ACM,APM,ASU_Gateway,BCM,BCM_BPM,CCU_F,CCU_R,ETG,LDM_L,LDM_R,OCS_P,PSM_D,SHVU_F,SHVU_R,TRM
 SG_ OBD_Func_DiagReqData6 : 55|8@0+ (1,0) [0|255] ""  ACM,APM,ASU_Gateway,BCM,BCM_BPM,CCU_F,CCU_R,ETG,LDM_L,LDM_R,OCS_P,PSM_D,SHVU_F,SHVU_R,TRM
 SG_ OBD_Func_DiagReqData7 : 63|8@0+ (1,0) [0|255] ""  ACM,APM,ASU_Gateway,BCM,BCM_BPM,CCU_F,CCU_R,ETG,LDM_L,LDM_R,OCS_P,PSM_D,SHVU_F,SHVU_R,TRM

BO_ 1793 SEED_CAN_Req1_CCU_R: 8 CCU_R
 SG_ SEED_CAN_Req1 : 7|64@0+ (1,0) [0|1.84467440737096E+019] ""  CCU_F,XGW_Body

BO_ 1795 SEED_CAN_Req2_CCU_F: 8 CCU_F
 SG_ SEED_CAN_Req2 : 7|64@0+ (1,0) [0|1.84467440737096E+019] ""  CCU_R,XGW_Body

BO_ 1797 SEED_CAN_Req3_ADAS_Body: 8 ADAS_Body
 SG_ SEED_CAN_Req3 : 7|64@0+ (1,0) [0|1.84467440737096E+019] ""  BCM,XGW_Body

BO_ 1803 SEED_CAN_Req6_BCM: 8 BCM
 SG_ SEED_CAN_Req6 : 7|64@0+ (1,0) [0|1.84467440737096E+019] ""  ADAS_Body,XGW_Body

BO_ 1805 SEED_CAN_Req7_VCU_PT: 8 XGW_Body
 SG_ SEED_CAN_Req7 : 7|64@0+ (1,0) [0|1.84467440737096E+019] ""  BCM,CCU_F,CCU_R

BO_ 1809 BCM_Data: 8 BCM
 SG_ BCM_Data0 : 7|8@0+ (1,0) [0|255] ""  BCM_BPM
 SG_ BCM_Data1 : 15|8@0+ (1,0) [0|255] ""  BCM_BPM
 SG_ BCM_Data2 : 23|8@0+ (1,0) [0|255] ""  BCM_BPM
 SG_ BCM_Data3 : 31|8@0+ (1,0) [0|255] ""  BCM_BPM
 SG_ BCM_Data4 : 39|8@0+ (1,0) [0|255] ""  BCM_BPM
 SG_ BCM_Data5 : 47|8@0+ (1,0) [0|255] ""  BCM_BPM
 SG_ BCM_Data6 : 55|8@0+ (1,0) [0|255] ""  BCM_BPM
 SG_ BCM_Data7 : 63|8@0+ (1,0) [0|255] ""  BCM_BPM

BO_ 1810 BCM_BPM_Data: 8 BCM
 SG_ BCM_BPM_Data0 : 7|8@0+ (1,0) [0|255] ""  BCM_BPM
 SG_ BCM_BPM_Data1 : 15|8@0+ (1,0) [0|255] ""  BCM_BPM
 SG_ BCM_BPM_Data2 : 23|8@0+ (1,0) [0|255] ""  BCM_BPM
 SG_ BCM_BPM_Data3 : 31|8@0+ (1,0) [0|255] ""  BCM_BPM
 SG_ BCM_BPM_Data4 : 39|8@0+ (1,0) [0|255] ""  BCM_BPM
 SG_ BCM_BPM_Data5 : 47|8@0+ (1,0) [0|255] ""  BCM_BPM
 SG_ BCM_BPM_Data6 : 55|8@0+ (1,0) [0|255] ""  BCM_BPM
 SG_ BCM_BPM_Data7 : 63|8@0+ (1,0) [0|255] ""  BCM_BPM

BO_ 1814 CCU_Debug_3: 8 CCU_F
 SG_ CCU_DuctSensor1 : 7|8@0+ (0.5,-30) [-30|97.5] "degree C" Vector__XXX
 SG_ CCU_DuctSensor2 : 15|8@0+ (0.5,-30) [-30|97.5] "degree C" Vector__XXX
 SG_ CCU_DuctSensor3 : 23|8@0+ (0.5,-30) [-30|97.5] "degree C" Vector__XXX
 SG_ CCU_DuctSensor4 : 31|8@0+ (0.5,-30) [-30|97.5] "degree C" Vector__XXX
 SG_ CCU_AQS_PWM_IN : 39|8@0+ (0.5,0) [0|100] "%" Vector__XXX
 SG_ CCU_AQSCtrlFrequency : 47|10@0+ (1,0) [0|1000] "Hz" Vector__XXX
 SG_ CCU_BattVoltSts : 53|4@0+ (1,0) [0|14] "" Vector__XXX
 SG_ CCU_BattVoltVal : 63|8@0+ (0.1,0) [0|25] "V" Vector__XXX

BO_ 1843 SEED_CAN_Req18_MHU: 8 XGW_Body
 SG_ SEED_CAN_Req18 : 7|64@0+ (1,0) [0|1.84467440737096E+019] ""  BCM,ETG

BO_ 1847 SEED_CAN_Req21_ETG: 8 ETG
 SG_ SEED_CAN_Req21 : 7|64@0+ (1,0) [0|1.84467440737096E+019] ""  XGW_Body

BO_ 1857 CCU_Debug_1: 8 CCU_F
 SG_ CCU_ERL_FL : 7|8@0+ (1,0) [0|255] ""  DUMMY_ECU
 SG_ CCU_ERL_FR : 15|8@0+ (1,0) [0|255] ""  DUMMY_ECU
 SG_ CCU_EvapTempSet : 23|8@0+ (0.1,-5) [-5|20.5] "Degree C"  DUMMY_ECU
 SG_ CCU_BlowerFltPWM : 31|8@0+ (0.5,0) [0|100] "%"  DUMMY_ECU
 SG_ CCU_AirDistribFlapPos : 39|8@0+ (0.5,0) [0|100] "%"  DUMMY_ECU
 SG_ CCU_RecircFlapPos : 47|8@0+ (0.5,0) [0|100] "%"  DUMMY_ECU
 SG_ CCU_AirDistribFeedback : 55|8@0+ (0.05,0) [0|5] "V"  DUMMY_ECU
 SG_ CCU_RecircFlapFeedback : 63|8@0+ (0.05,0) [0|5] "V"  DUMMY_ECU

BO_ 1858 CCU_Debug_2: 8 CCU_F
 SG_ CCU_TempFlapPos_FL : 7|8@0+ (0.5,0) [0|100] "%"  DUMMY_ECU
 SG_ CCU_TempFlapPos_FR : 15|8@0+ (0.5,0) [0|100] "%"  DUMMY_ECU
 SG_ CCU_DuctTargetTemp_FL : 23|8@0+ (0.5,-40) [-40|85] "Degree C"  DUMMY_ECU
 SG_ CCU_DuctTargetTemp_FR : 31|8@0+ (0.5,-40) [-40|85] "Degree C"  DUMMY_ECU
 SG_ CCU_TempFLFeedback : 39|8@0+ (0.05,0) [0|5] "V"  DUMMY_ECU
 SG_ CCU_TempFRFeedback : 47|8@0+ (0.05,0) [0|5] "V"  DUMMY_ECU
 SG_ CCU_PTCSetTemp : 55|8@0+ (0.5,0) [0|127] "Degree C"  DUMMY_ECU

BO_ 2046 CCU_Debug_4: 8 CCU_F
 SG_ TST_TxMsgConfirm_CcuHeatCoolReq : 1|1@0+ (1,0) [0|1] ""  DUMMY_ECU
 SG_ TST_RxMsgConfirm_BCM_CLAMP_STAT : 10|1@0+ (1,0) [0|1] ""  DUMMY_ECU
 SG_ CCU_TST_TxMsgConfirm_CcuWarnMsg : 8|1@0+ (1,0) [0|1] ""  DUMMY_ECU
 SG_ CCU_TST_TxMsgConfirm_CcuNm : 0|1@0+ (1,0) [0|1] ""  DUMMY_ECU
 SG_ CCU_TST_StateMngr_States : 7|3@0+ (1,0) [0|7] ""  DUMMY_ECU
 SG_ CCU_TST_Reserve_6 : 63|8@0+ (1,0) [0|255] ""  DUMMY_ECU
 SG_ CCU_TST_Reserve_5 : 55|8@0+ (1,0) [0|255] ""  DUMMY_ECU
 SG_ CCU_TST_Reserve_4 : 47|8@0+ (1,0) [0|255] ""  DUMMY_ECU
 SG_ CCU_TST_Reserve_3 : 39|8@0+ (1,0) [0|255] ""  DUMMY_ECU
 SG_ CCU_TST_Reserve_2 : 31|8@0+ (1,0) [0|255] ""  DUMMY_ECU
 SG_ CCU_TST_Reserve_1 : 23|8@0+ (1,0) [0|255] ""  DUMMY_ECU
 SG_ CCU_TST_Reserve_0 : 15|5@0+ (1,0) [0|31] "" DUMMY_ECU
 SG_ CCU_TST_NetworkMngr_States : 4|3@0+ (1,0) [0|7] ""  DUMMY_ECU
 SG_ CCU_TST_BCM_CRC : 9|1@0+ (1,0) [0|1] ""  DUMMY_ECU

BO_ 1938 CCU_Resp_CCP: 8 CCU_F
 SG_ CCU_Resp_CCP : 7|64@0+ (1,0) [0|0] ""  DUMMY_ECU

BO_ 1939 Internal_MSG_1: 8 LDM_L
 SG_ LDML_FltReactn : 7|32@0+ (1,0) [0|4294967295] ""  LDM_R
 SG_ LDML_RiAdjstAgOutp : 39|11@0+ (0.01,-10) [-10|10] "degree"  LDM_R

BO_ 1940 Internal_MSG_2: 8 LDM_R
 SG_ LDMR_FltReactn : 7|32@0+ (1,0) [0|4294967295] ""  LDM_L
 SG_ LDMR_ModuleCurAg : 39|11@0+ (0.01,-10) [-10|10] "degree"  LDM_L

BO_ 1976 CCU_Req_EOL: 8 DUMMY_ECU
 SG_ CCU_Req_EOL : 7|64@0+ (1,0) [0|0] ""  CCU_F

BO_ 1977 CCU_Resp_EOL: 8 CCU_F
 SG_ CCU_Resp_EOL : 7|64@0+ (1,0) [0|0] ""  DUMMY_ECU

BO_ 1978 CCUR_Req_EOL: 8 DUMMY_ECU
 SG_ CCUR_Req_EOL : 7|64@0+ (1,0) [0|0] ""  CCU_R

BO_ 1980 CCUR_Resp_EOL: 8 CCU_R
 SG_ CCUR_Resp_EOL_ : 7|64@0+ (1,0) [0|0] ""  DUMMY_ECU

BO_ 1985 CCU_Req_CCP: 8 DUMMY_ECU
 SG_ CCU_Req_CCP : 7|64@0+ (1,0) [0|0] ""  CCU_F

BO_ 2015 Diag_Request_ECU: 8 XGW_Body
 SG_ Diag_Request_ECU_Data0 : 7|8@0+ (1,0) [0|255] ""  ACM,APM,BCM,BCM_BPM,CCU_F,ETG,LDM_L,LDM_R,OCS_P,PSM_D,SHVU_F,SHVU_R,TRM
 SG_ Diag_Request_ECU_Data1 : 15|8@0+ (1,0) [0|255] "-"  ACM,APM,BCM,BCM_BPM,CCU_F,ETG,LDM_L,LDM_R,OCS_P,PSM_D,SHVU_F,SHVU_R,TRM
 SG_ Diag_Request_ECU_Data2 : 23|8@0+ (1,0) [0|255] "-"  ACM,APM,BCM,BCM_BPM,CCU_F,ETG,LDM_L,LDM_R,OCS_P,PSM_D,SHVU_F,SHVU_R,TRM
 SG_ Diag_Request_ECU_Data3 : 31|8@0+ (1,0) [0|255] ""  ACM,APM,BCM,BCM_BPM,CCU_F,ETG,LDM_L,LDM_R,OCS_P,PSM_D,SHVU_F,SHVU_R,TRM
 SG_ Diag_Request_ECU_Data4 : 39|8@0+ (1,0) [0|255] "-"  ACM,APM,BCM,BCM_BPM,CCU_F,ETG,LDM_L,LDM_R,OCS_P,PSM_D,SHVU_F,SHVU_R,TRM
 SG_ Diag_Request_ECU_Data5 : 47|8@0+ (1,0) [0|255] ""  ACM,APM,BCM,BCM_BPM,CCU_F,ETG,LDM_L,LDM_R,OCS_P,PSM_D,SHVU_F,SHVU_R,TRM
 SG_ Diag_Request_ECU_Data6 : 55|8@0+ (1,0) [0|255] "-"  ACM,APM,BCM,BCM_BPM,CCU_F,ETG,LDM_L,LDM_R,OCS_P,PSM_D,SHVU_F,SHVU_R,TRM
 SG_ Diag_Request_ECU_Data7 : 63|8@0+ (1,0) [0|255] ""  ACM,APM,BCM,BCM_BPM,CCU_F,ETG,LDM_L,LDM_R,OCS_P,PSM_D,SHVU_F,SHVU_R,TRM

BO_ 2033 DIAG_Req_Airbag_Deploy: 8 XGW_Body
 SG_ Request_Airbag_Deployment : 7|64@0+ (1,0) [0|1.84467440737096E+019] ""  ACM

BO_ 2041 DIAG_Resp_Airbag_Deploy: 8 ACM
 SG_ Response_Airbag_Deployment : 7|64@0+ (1,0) [0|255] ""  XGW_Body
